VERSION "j1939-2025-03-v2.4-light"

NS_ :

BS_:

BU_:

BO_ 2566547198 ASI3: 8 Vector__XXX
 SG_ DslExhstFldTnk1EmptCnt : 0|32@1+ (1,0) [0|4211081215] "count" Vector__XXX
 SG_ DslExhstFldQltMlfntnCnt : 32|32@1+ (1,0) [0|4211081215] "count" Vector__XXX

BO_ 2633656318 FR1: 8 Vector__XXX
 SG_ EngineOilResistance : 0|32@1+ (1000,0) [0|4211081215000] "ohm" Vector__XXX
 SG_ HydraulicOilResistance : 32|32@1+ (1000,0) [0|4211081215000] "ohm" Vector__XXX

BO_ 2566547710 PC2IIR: 8 Vector__XXX
 SG_ PwCvt2HVtBsAtvIstTstCd : 0|2@1+ (1,0) [0|3] "" Vector__XXX
 SG_ PwCvt2HVtBsPssvIstTstCd : 2|2@1+ (1,0) [0|3] "" Vector__XXX
 SG_ PwCvt2HVtBsHSdRsstCtRqst : 4|2@1+ (1,0) [0|3] "" Vector__XXX
 SG_ PwCvt2HVtBsLwSdRsstCtRqst : 6|2@1+ (1,0) [0|3] "" Vector__XXX

BO_ 2566547966 PC1IIR: 8 Vector__XXX
 SG_ PwCvt1HVtBsAtvIstTstCd : 0|2@1+ (1,0) [0|3] "" Vector__XXX
 SG_ PwCvt1HVtBsPssvIstTstCd : 2|2@1+ (1,0) [0|3] "" Vector__XXX
 SG_ PwCvt1HVtBsHSdRsstCtRqst : 4|2@1+ (1,0) [0|3] "" Vector__XXX
 SG_ PwCvt1HVtBsLwSdRsstCtRqst : 6|2@1+ (1,0) [0|3] "" Vector__XXX

BO_ 2566548222 PC2IRP: 8 Vector__XXX
 SG_ PwrCnvrtr2LmtsRqstPwrCr : 0|8@1+ (1,0) [0|250] "count" Vector__XXX
 SG_ PwrCnvrtr2LmtsRqstPwrCntr : 8|4@1+ (1,0) [0|15] "" Vector__XXX
 SG_ PwrCnvrtr2LmtsRqstEltrlPwrMxmm : 12|12@1+ (0.0625,-125) [-125|125.9375] "%" Vector__XXX
 SG_ PwrCnvrtr2LmtsRqstEltrlPwrMnmm : 24|12@1+ (0.0625,-125) [-125|125.9375] "%" Vector__XXX
 SG_ PwCvt2LtsRqstDES1PwMx : 36|12@1+ (0.0625,-125) [-125|125.9375] "%" Vector__XXX
 SG_ PwCvt2LtsRqstDES1PwM : 48|12@1+ (0.0625,-125) [-125|125.9375] "%" Vector__XXX

BO_ 2566548478 PC2ILRM: 8 Vector__XXX
 SG_ PwrCnvrtr2LmtsRqstEltrlCr : 0|8@1+ (1,0) [0|250] "count" Vector__XXX
 SG_ PwrCnvrtr2LmtsRqstEltrlCntr : 8|4@1+ (1,0) [0|15] "" Vector__XXX
 SG_ PwrCnvrtr2LmtsRqstCrrntMxmm : 12|12@1+ (0.0625,-125) [-125|125.9375] "%" Vector__XXX
 SG_ PwrCnvrtr2LmtsRqstCrrntMnmm : 24|12@1+ (0.0625,-125) [-125|125.9375] "%" Vector__XXX
 SG_ PwrCnvrtr2LmtsRqstFrqnMxmm : 36|12@1+ (0.0625,-125) [-125|125.9375] "%" Vector__XXX
 SG_ PwrCnvrtr2LmtsRqstFrqnMnmm : 48|12@1+ (0.0625,-125) [-125|125.9375] "%" Vector__XXX

BO_ 2566548734 PC2ILRDC: 8 Vector__XXX
 SG_ PwrCnvrtr2LmtsRqstDEnrgSr1Cr : 0|8@1+ (1,0) [0|250] "count" Vector__XXX
 SG_ PwrCnvrtr2LmtsRqstDEnrgSr1Cntr : 8|4@1+ (1,0) [0|15] "" Vector__XXX
 SG_ PwCvt2LtsRqstDES1VtMx : 12|12@1+ (0.0625,-125) [-125|125.9375] "%" Vector__XXX
 SG_ PwCvt2LtsRqstDES1VtM : 24|12@1+ (0.0625,-125) [-125|125.9375] "%" Vector__XXX
 SG_ PwCvt2LtsRqstDES1CtMx : 36|12@1+ (0.0625,-125) [-125|125.9375] "%" Vector__XXX
 SG_ PwCvt2LtsRqstDES1CtM : 48|12@1+ (0.0625,-125) [-125|125.9375] "%" Vector__XXX

BO_ 2566548990 PC1ILRDC: 8 Vector__XXX
 SG_ PwrCnvrtr1LmtsRqstDEnrgSr1Cr : 0|8@1+ (1,0) [0|250] "count" Vector__XXX
 SG_ PwrCnvrtr1LmtsRqstDEnrgSr1Cntr : 8|4@1+ (1,0) [0|15] "" Vector__XXX
 SG_ PwCvt1LtsRqstDES1VtMx : 12|12@1+ (0.0625,-125) [-125|125.9375] "%" Vector__XXX
 SG_ PwCvt1LtsRqstDES1VtM : 24|12@1+ (0.0625,-125) [-125|125.9375] "%" Vector__XXX
 SG_ PwCvt1LtsRqstDES1CtMx : 36|12@1+ (0.0625,-125) [-125|125.9375] "%" Vector__XXX
 SG_ PwCvt1LtsRqstDES1CtM : 48|12@1+ (0.0625,-125) [-125|125.9375] "%" Vector__XXX

BO_ 2566549246 PC1ILRM: 8 Vector__XXX
 SG_ PwrCnvrtr1LmtsRqstEltrlCr : 0|8@1+ (1,0) [0|250] "count" Vector__XXX
 SG_ PwrCnvrtr1LmtsRqstEltrlCntr : 8|4@1+ (1,0) [0|15] "" Vector__XXX
 SG_ PwrCnvrtr1LmtsRqstCrrntMxmm : 12|12@1+ (0.0625,-125) [-125|125.9375] "%" Vector__XXX
 SG_ PwrCnvrtr1LmtsRqstCrrntMnmm : 24|12@1+ (0.0625,-125) [-125|125.9375] "%" Vector__XXX
 SG_ PwrCnvrtr1LmtsRqstFrqnMxmm : 36|12@1+ (0.0625,-125) [-125|125.9375] "%" Vector__XXX
 SG_ PwrCnvrtr1LmtsRqstFrqnMnmm : 48|12@1+ (0.0625,-125) [-125|125.9375] "%" Vector__XXX

BO_ 2566549502 PC1IRP: 8 Vector__XXX
 SG_ PwrCnvrtr1LmtsRqstPwrCr : 0|8@1+ (1,0) [0|250] "count" Vector__XXX
 SG_ PwrCnvrtr1LmtsRqstPwrCntr : 8|4@1+ (1,0) [0|15] "" Vector__XXX
 SG_ PwrCnvrtr1LmtsRqstEltrlPwrMxmm : 12|12@1+ (0.0625,-125) [-125|125.9375] "%" Vector__XXX
 SG_ PwrCnvrtr1LmtsRqstEltrlPwrMnmm : 24|12@1+ (0.0625,-125) [-125|125.9375] "%" Vector__XXX
 SG_ PwCvt1LtsRqstDES1PwMx : 36|12@1+ (0.0625,-125) [-125|125.9375] "%" Vector__XXX
 SG_ PwCvt1LtsRqstDES1PwM : 48|12@1+ (0.0625,-125) [-125|125.9375] "%" Vector__XXX

BO_ 2566549758 PC1LD: 16 Vector__XXX
 SG_ PwrCnvrtr1TtlEnrgCnsmd : 0|32@1+ (100,0) [0|421108121500] "Watt-hour" Vector__XXX
 SG_ PwrCnvrtr1TtlEnrgGnrtd : 32|32@1+ (100,0) [0|421108121500] "Watt-hour" Vector__XXX
 SG_ PwrCnvrtr1TtlChrgCnsmd : 64|32@1+ (100,0) [0|421108121500] "Ah" Vector__XXX
 SG_ PwrCnvrtr1TtlChrgGnrtd : 96|32@1+ (100,0) [0|421108121500] "Ah" Vector__XXX

BO_ 2566550014 PC2LD: 16 Vector__XXX
 SG_ PwrCnvrtr2TtlEnrgCnsmd : 0|32@1+ (100,0) [0|421108121500] "Watt-hour" Vector__XXX
 SG_ PwrCnvrtr2TtlEnrgGnrtd : 32|32@1+ (100,0) [0|421108121500] "Watt-hour" Vector__XXX
 SG_ PwrCnvrtr2TtlChrgCnsmd : 64|32@1+ (100,0) [0|421108121500] "Ah" Vector__XXX
 SG_ PwrCnvrtr2TtlChrgGnrtd : 96|32@1+ (100,0) [0|421108121500] "Ah" Vector__XXX

BO_ 2566550270 PC2IAPL: 8 Vector__XXX
 SG_ PwrCnvrtr2PwrLmtdDTUndfndRsn : 0|2@1+ (1,0) [0|3] "" Vector__XXX
 SG_ PwCvt2PwLtdDTDES1CtMx : 2|2@1+ (1,0) [0|3] "" Vector__XXX
 SG_ PwCvt2PwLtdDTDES1CtM : 4|2@1+ (1,0) [0|3] "" Vector__XXX
 SG_ PwCvt2PwLtdDTDES1VtMx : 6|2@1+ (1,0) [0|3] "" Vector__XXX
 SG_ PwCvt2PwLtdDTDES1VtM : 8|2@1+ (1,0) [0|3] "" Vector__XXX
 SG_ PwrCnvrtr2PwrLmtdDTEltrlPwrMxmm : 10|2@1+ (1,0) [0|3] "" Vector__XXX
 SG_ PwrCnvrtr2PwrLmtdDTEltrlPwrMnmm : 12|2@1+ (1,0) [0|3] "" Vector__XXX
 SG_ PwCvt2PwLtdDTDES1PwMx : 14|2@1+ (1,0) [0|3] "" Vector__XXX
 SG_ PwCvt2PwLtdDTDES1PwM : 16|2@1+ (1,0) [0|3] "" Vector__XXX
 SG_ PwrCnvrtr2PwrLmtdDTCrrntMxmm : 18|2@1+ (1,0) [0|3] "" Vector__XXX
 SG_ PwrCnvrtr2PwrLmtdDTCrrntMnmm : 20|2@1+ (1,0) [0|3] "" Vector__XXX
 SG_ PwrCnvrtr2PwrLmtdDTFrqnMxmm : 22|2@1+ (1,0) [0|3] "" Vector__XXX
 SG_ PwrCnvrtr2PwrLmtdDTFrqnMnmm : 24|2@1+ (1,0) [0|3] "" Vector__XXX
 SG_ PwrCnvrtr2PwrLmtdDTInvrtrTmprtr : 28|2@1+ (1,0) [0|3] "" Vector__XXX
 SG_ PwrCnvrtr2PwrLmtdDTTmprtr : 30|2@1+ (1,0) [0|3] "" Vector__XXX
 SG_ PwrCnvrtr2PwrLmtdDTFltCndtn : 32|2@1+ (1,0) [0|3] "" Vector__XXX
 SG_ PwCvt2PwLtdDTAtvCtRtLt : 34|2@1+ (1,0) [0|3] "" Vector__XXX
 SG_ PwCvt2CtLtdDTMCtsts : 38|2@1+ (1,0) [0|3] "" Vector__XXX

BO_ 2566550526 PC1IAPL: 8 Vector__XXX
 SG_ PwrCnvrtr1PwrLmtdDTUndfndRsn : 0|2@1+ (1,0) [0|3] "" Vector__XXX
 SG_ PwCvt1PwLtdDTDES1CtMx : 2|2@1+ (1,0) [0|3] "" Vector__XXX
 SG_ PwCvt1PwLtdDTDES1CtM : 4|2@1+ (1,0) [0|3] "" Vector__XXX
 SG_ PwCvt1PwLtdDTDES1VtMx : 6|2@1+ (1,0) [0|3] "" Vector__XXX
 SG_ PwCvt1PwLtdDTDES1VtM : 8|2@1+ (1,0) [0|3] "" Vector__XXX
 SG_ PwrCnvrtr1PwrLmtdDTEltrlPwrMxmm : 10|2@1+ (1,0) [0|3] "" Vector__XXX
 SG_ PwrCnvrtr1PwrLmtdDTEltrlPwrMnmm : 12|2@1+ (1,0) [0|3] "" Vector__XXX
 SG_ PwCvt1PwLtdDTDES1PwMx : 14|2@1+ (1,0) [0|3] "" Vector__XXX
 SG_ PwCvt1PwLtdDTDES1PwM : 16|2@1+ (1,0) [0|3] "" Vector__XXX
 SG_ PwrCnvrtr1PwrLmtdDTCrrntMxmm : 18|2@1+ (1,0) [0|3] "" Vector__XXX
 SG_ PwrCnvrtr1PwrLmtdDTCrrntMnmm : 20|2@1+ (1,0) [0|3] "" Vector__XXX
 SG_ PwrCnvrtr1PwrLmtdDTFrqnMxmm : 22|2@1+ (1,0) [0|3] "" Vector__XXX
 SG_ PwrCnvrtr1PwrLmtdDTFrqnMnmm : 24|2@1+ (1,0) [0|3] "" Vector__XXX
 SG_ PwrCnvrtr1PwrLmtdDTInvrtrTmprtr : 28|2@1+ (1,0) [0|3] "" Vector__XXX
 SG_ PwrCnvrtr1PwrLmtdDTTmprtr : 30|2@1+ (1,0) [0|3] "" Vector__XXX
 SG_ PwrCnvrtr1PwrLmtdDTFltCndtn : 32|2@1+ (1,0) [0|3] "" Vector__XXX
 SG_ PwCvt1PwLtdDTAtvCtRtLt : 34|2@1+ (1,0) [0|3] "" Vector__XXX
 SG_ PwCvt1CtLtdDTMCtsts : 38|2@1+ (1,0) [0|3] "" Vector__XXX

BO_ 2365224190 PC2IR1: 8 Vector__XXX
 SG_ PowerConverter2Reference1Crc : 0|8@1+ (1,0) [0|250] "count" Vector__XXX
 SG_ PwrCnvrtr2Rfrn1Cntr : 8|4@1+ (1,0) [0|15] "" Vector__XXX
 SG_ PwrCnvrtr2RfrnFrqn : 32|16@1+ (4,0) [0|257020] "rpm" Vector__XXX
 SG_ PowerConverter2ReferencePower : 48|16@1+ (0.0625,0) [0|4015.9375] "kW" Vector__XXX
 SG_ PowerConverter2ReferenceTorque : 16|16@1+ (0.5,0) [0|32127.5] "Nm" Vector__XXX

BO_ 2365224446 PC2IR2: 8 Vector__XXX
 SG_ PowerConverter2ReferenceCurrent : 32|16@1+ (0.125,0) [0|8031.875] "A" Vector__XXX
 SG_ PowerConverter2Reference2Crc : 0|8@1+ (1,0) [0|250] "count" Vector__XXX
 SG_ PwrCnvrtr2Rfrn2Cntr : 8|4@1+ (1,0) [0|15] "" Vector__XXX
 SG_ PowerConverter2ReferenceVoltage : 48|16@1+ (0.125,0) [0|8031.875] "V" Vector__XXX

BO_ 2566551294 PC2IT: 8 Vector__XXX
 SG_ PowerConverter2Temperature1 : 0|8@1+ (1,-40) [-40|210] "degC" Vector__XXX
 SG_ PowerConverter2Temperature2 : 8|8@1+ (1,-40) [-40|210] "degC" Vector__XXX
 SG_ PowerConverter2Temperature3 : 16|8@1+ (1,-40) [-40|210] "degC" Vector__XXX
 SG_ PowerConverter2Temperature4 : 24|8@1+ (1,-40) [-40|210] "degC" Vector__XXX

BO_ 2566551550 PC1IT: 8 Vector__XXX
 SG_ PowerConverter1Temperature1 : 0|8@1+ (1,-40) [-40|210] "degC" Vector__XXX
 SG_ PowerConverter1Temperature2 : 8|8@1+ (1,-40) [-40|210] "degC" Vector__XXX
 SG_ PowerConverter1Temperature3 : 16|8@1+ (1,-40) [-40|210] "degC" Vector__XXX
 SG_ PowerConverter1Temperature4 : 24|8@1+ (1,-40) [-40|210] "degC" Vector__XXX

BO_ 2365225214 PC1IR2: 8 Vector__XXX
 SG_ PowerConverter1Reference2Crc : 0|8@1+ (1,0) [0|250] "count" Vector__XXX
 SG_ PwrCnvrtr1Rfrn2Cntr : 8|4@1+ (1,0) [0|15] "" Vector__XXX
 SG_ PowerConverter1ReferenceCurrent : 32|16@1+ (0.125,0) [0|8031.875] "A" Vector__XXX
 SG_ PowerConverter1ReferenceVoltage : 48|16@1+ (0.125,0) [0|8031.875] "V" Vector__XXX

BO_ 2365225470 PC1IR1: 8 Vector__XXX
 SG_ PowerConverter1Reference1Crc : 0|8@1+ (1,0) [0|250] "count" Vector__XXX
 SG_ PwrCnvrtr1Rfrn1Cntr : 8|4@1+ (1,0) [0|15] "" Vector__XXX
 SG_ PwrCnvrtr1RfrnFrqn : 32|16@1+ (4,0) [0|257020] "rpm" Vector__XXX
 SG_ PowerConverter1ReferencePower : 48|16@1+ (0.0625,0) [0|4015.9375] "kW" Vector__XXX
 SG_ PowerConverter1ReferenceTorque : 16|16@1+ (0.5,0) [0|32127.5] "Nm" Vector__XXX

BO_ 2365225726 PC1PC: 8 Vector__XXX
 SG_ PwrCnvrtr1PwrCnvrtrPhsUCrrnt : 0|16@1+ (0.125,0) [0|8031.875] "A" Vector__XXX
 SG_ PwrCnvrtr1PwrCnvrtrPhsVCrrnt : 16|16@1+ (0.125,0) [0|8031.875] "A" Vector__XXX
 SG_ PwrCnvrtr1PwrCnvrtrPhsWCrrnt : 32|16@1+ (0.125,0) [0|8031.875] "A" Vector__XXX

BO_ 2365225982 S21PC: 8 Vector__XXX
 SG_ PwrCnvrtr2PwrCnvrtrPhsUCrrnt : 0|16@1+ (0.125,0) [0|8031.875] "A" Vector__XXX
 SG_ PwrCnvrtr2PwrCnvrtrPhsVCrrnt : 16|16@1+ (0.125,0) [0|8031.875] "A" Vector__XXX
 SG_ PwrCnvrtr2PwrCnvrtrPhsWCrrnt : 32|16@1+ (0.125,0) [0|8031.875] "A" Vector__XXX

BO_ 2365226238 PC1PV: 8 Vector__XXX
 SG_ PwrCnvrtr1PwrCnvrtrPhsUVltg : 0|16@1+ (0.125,0) [0|8031.875] "V" Vector__XXX
 SG_ PwrCnvrtr1PwrCnvrtrPhsVVltg : 16|16@1+ (0.125,0) [0|8031.875] "V" Vector__XXX
 SG_ PwrCnvrtr1PwrCnvrtrPhsWVltg : 32|16@1+ (0.125,0) [0|8031.875] "V" Vector__XXX

BO_ 2365226494 PC2PV: 8 Vector__XXX
 SG_ PwrCnvrtr2PwrCnvrtrPhsUVltg : 0|16@1+ (0.125,0) [0|8031.875] "V" Vector__XXX
 SG_ PwrCnvrtr2PwrCnvrtrPhsVVltg : 16|16@1+ (0.125,0) [0|8031.875] "V" Vector__XXX
 SG_ PwrCnvrtr2PwrCnvrtrPhsWVltg : 32|16@1+ (0.125,0) [0|8031.875] "V" Vector__XXX

BO_ 2566553342 SIPST: 8 Vector__XXX
 SG_ PwCvt1PwCvtPsUPwMdSwtTpt : 0|8@1+ (1,-40) [-40|210] "degC" Vector__XXX
 SG_ PwCvt1PwCvtPsVPwMdSwtTpt : 8|8@1+ (1,-40) [-40|210] "degC" Vector__XXX
 SG_ PwCvt1PwCvtPsWPwMdSwtTpt : 16|8@1+ (1,-40) [-40|210] "degC" Vector__XXX
 SG_ PwCvt2PwCvtPsUPwMdSwtTpt : 24|8@1+ (1,-40) [-40|210] "degC" Vector__XXX
 SG_ PwCvt2PwCvtPsVPwMdSwtTpt : 32|8@1+ (1,-40) [-40|210] "degC" Vector__XXX
 SG_ PwCvt2PwCvtPsWPwMdSwtTpt : 40|8@1+ (1,-40) [-40|210] "degC" Vector__XXX

BO_ 2365227006 PC1PSV: 8 Vector__XXX
 SG_ PwCvt1PwCvtPsUPwMdSwtPwSppVt : 0|16@1+ (0.125,0) [0|8031.875] "V" Vector__XXX
 SG_ PwCvt1PwCvtPsVPwMdSwtPwSppVt : 16|16@1+ (0.125,0) [0|8031.875] "V" Vector__XXX
 SG_ PwCvt1PwCvtPsWPwMdSwtPwSppVt : 32|16@1+ (0.125,0) [0|8031.875] "V" Vector__XXX

BO_ 2365227262 PC2PSV: 8 Vector__XXX
 SG_ PwCvt2PwCvtPsUPwMdSwtPwSppVt : 0|16@1+ (0.125,0) [0|8031.875] "V" Vector__XXX
 SG_ PwCvt2PwCvtPsVPwMdSwtPwSppVt : 16|16@1+ (0.125,0) [0|8031.875] "V" Vector__XXX
 SG_ PwCvt2PwCvtPsWPwMdSwtPwSppVt : 32|16@1+ (0.125,0) [0|8031.875] "V" Vector__XXX

BO_ 2365227518 SIT1: 8 Vector__XXX
 SG_ PwrCnvrtr1PwrCnvrtrACrrntOtpt : 0|16@1+ (0.125,0) [0|8031.875] "A" Vector__XXX
 SG_ PwrCnvrtr2PwrCnvrtrACrrntOtpt : 16|16@1+ (0.125,0) [0|8031.875] "A" Vector__XXX
 SG_ PwCvt1PwCvtPwMdSwtTpt : 32|8@1+ (1,-40) [-40|210] "degC" Vector__XXX
 SG_ PwCvt2PwCvtPwMdSwtTpt : 40|8@1+ (1,-40) [-40|210] "degC" Vector__XXX

BO_ 2566554366 TFMRT: 8 Vector__XXX
 SG_ Transformer1PhaseUTemperature : 0|8@1+ (1,-40) [-40|210] "degC" Vector__XXX
 SG_ Transformer1PhaseVTemperature : 8|8@1+ (1,-40) [-40|210] "degC" Vector__XXX
 SG_ Transformer1PhaseWTemperature : 16|8@1+ (1,-40) [-40|210] "degC" Vector__XXX
 SG_ Transformer2PhaseUTemperature : 24|8@1+ (1,-40) [-40|210] "degC" Vector__XXX
 SG_ Transformer2PhaseVTemperature : 32|8@1+ (1,-40) [-40|210] "degC" Vector__XXX
 SG_ Transformer2PhaseWTemperature : 40|8@1+ (1,-40) [-40|210] "degC" Vector__XXX

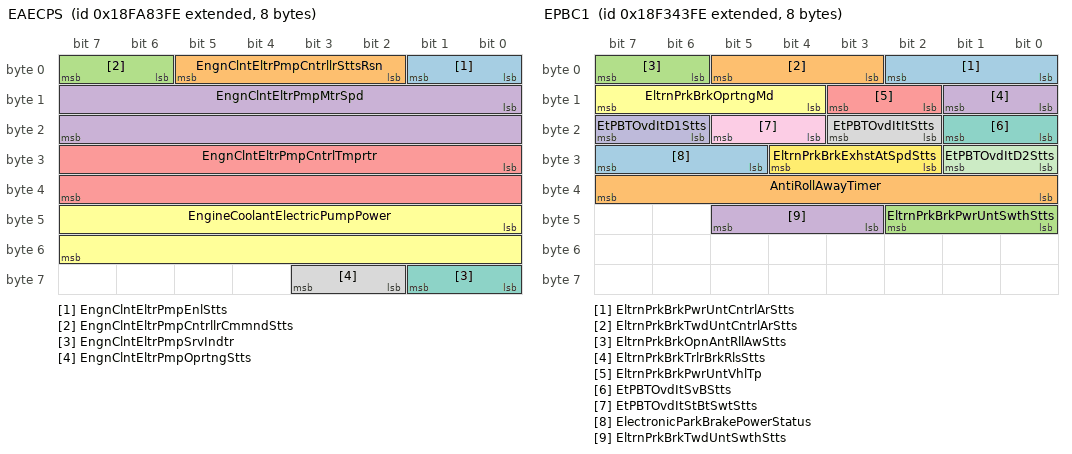
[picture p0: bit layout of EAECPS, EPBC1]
BO_ 2566554622 EAECPS: 8 Vector__XXX
 SG_ EngnClntEltrPmpEnlStts : 0|2@1+ (1,0) [0|3] "" Vector__XXX
 SG_ EngnClntEltrPmpCntrllrSttsRsn : 2|4@1+ (1,0) [0|15] "" Vector__XXX
 SG_ EngnClntEltrPmpCntrllrCmmndStts : 6|2@1+ (1,0) [0|3] "" Vector__XXX
 SG_ EngnClntEltrPmpMtrSpd : 8|16@1+ (0.5,0) [0|32127.5] "rpm" Vector__XXX
 SG_ EngnClntEltrPmpCntrlTmprtr : 24|16@1+ (0.03125,-273) [-273|1734.96875] "degC" Vector__XXX
 SG_ EngineCoolantElectricPumpPower : 40|16@1+ (0.5,0) [0|32127.5] "W" Vector__XXX
 SG_ EngnClntEltrPmpSrvIndtr : 56|2@1+ (1,0) [0|3] "" Vector__XXX
 SG_ EngnClntEltrPmpOprtngStts : 58|2@1+ (1,0) [0|3] "" Vector__XXX

BO_ 2633663742 HVESP11HIST: 19 Vector__XXX
 SG_ Hvesp11StateOfHealth : 0|8@1+ (0.4,0) [0|100] "%" Vector__XXX
 SG_ Hvsp11CnttrOpnUndrLdCnt : 8|16@1+ (1,0) [0|64255] "count" Vector__XXX
 SG_ Hvesp11TotalEnergyThroughput : 24|32@1+ (100,0) [0|421108121500] "Watt-hour" Vector__XXX
 SG_ Hvesp11TotalAccumulatedCharge : 56|32@1+ (100,0) [0|421108121500] "Ah" Vector__XXX
 SG_ Hvesp11TotalLifetimeEnergyInput : 88|32@1+ (1,0) [0|4211081215] "kWh" Vector__XXX
 SG_ Hvsp11TtlLftmEnrgOtpt : 120|32@1+ (1,0) [0|4211081215] "kWh" Vector__XXX

BO_ 2566555134 HVESP11CFG: 19 Vector__XXX
 SG_ Hvesp11NominalVoltage : 0|16@1+ (0.05,0) [0|3212.75] "V" Vector__XXX
 SG_ Hvsp11RmmnddMnmmOprtngVltg : 16|16@1+ (0.05,0) [0|3212.75] "V" Vector__XXX
 SG_ Hvsp11RmmnddMxmmOprtngVltg : 32|16@1+ (0.05,0) [0|3212.75] "V" Vector__XXX
 SG_ Hvsp11RmmnddMnmmSttOfChrg : 48|16@1+ (0.0015625,0) [0|100.3984375] "%" Vector__XXX
 SG_ Hvsp11RmmnddMxmmSttOfChrg : 64|16@1+ (0.0015625,0) [0|100.3984375] "%" Vector__XXX
 SG_ Hvsp11RmmnddMxmmOprtngTmprtr : 80|16@1+ (0.03125,-273) [-273|1734.96875] "degC" Vector__XXX
 SG_ Hvsp11RmmnddMnmmOprtngTmprtr : 96|16@1+ (0.03125,-273) [-273|1734.96875] "degC" Vector__XXX
 SG_ Hvesp11CellMaximumVoltageLimit : 112|8@1+ (0.02044,0) [0|5.11] "V" Vector__XXX
 SG_ Hvesp11CellMinimumVoltageLimit : 120|8@1+ (0.02044,0) [0|5.11] "V" Vector__XXX
 SG_ Hvesp11NominalRatedCapacity : 128|24@1+ (0.001,0) [0|16449.535] "kWh" Vector__XXX

BO_ 2633664254 HVESP12HIST: 19 Vector__XXX
 SG_ Hvesp12StateOfHealth : 0|8@1+ (0.4,0) [0|100] "%" Vector__XXX
 SG_ Hvsp12CnttrOpnUndrLdCnt : 8|16@1+ (1,0) [0|64255] "count" Vector__XXX
 SG_ Hvesp12TotalEnergyThroughput : 24|32@1+ (100,0) [0|421108121500] "Watt-hour" Vector__XXX
 SG_ Hvesp12TotalAccumulatedCharge : 56|32@1+ (100,0) [0|421108121500] "Ah" Vector__XXX
 SG_ Hvesp12TotalLifetimeEnergyInput : 88|32@1+ (1,0) [0|4211081215] "kWh" Vector__XXX
 SG_ Hvsp12TtlLftmEnrgOtpt : 120|32@1+ (1,0) [0|4211081215] "kWh" Vector__XXX

BO_ 2566555646 HVESP12CFG: 19 Vector__XXX
 SG_ Hvesp12NominalVoltage : 0|16@1+ (0.05,0) [0|3212.75] "V" Vector__XXX
 SG_ Hvsp12RmmnddMnmmOprtngVltg : 16|16@1+ (0.05,0) [0|3212.75] "V" Vector__XXX
 SG_ Hvsp12RmmnddMxmmOprtngVltg : 32|16@1+ (0.05,0) [0|3212.75] "V" Vector__XXX
 SG_ Hvsp12RmmnddMnmmSttOfChrg : 48|16@1+ (0.0015625,0) [0|100.3984375] "%" Vector__XXX
 SG_ Hvsp12RmmnddMxmmSttOfChrg : 64|16@1+ (0.0015625,0) [0|100.3984375] "%" Vector__XXX
 SG_ Hvsp12RmmnddMxmmOprtngTmprtr : 80|16@1+ (0.03125,-273) [-273|1734.96875] "degC" Vector__XXX
 SG_ Hvsp12RmmnddMnmmOprtngTmprtr : 96|16@1+ (0.03125,-273) [-273|1734.96875] "degC" Vector__XXX
 SG_ Hvesp12CellMaximumVoltageLimit : 112|8@1+ (0.02044,0) [0|5.11] "V" Vector__XXX
 SG_ Hvesp12CellMinimumVoltageLimit : 120|8@1+ (0.02044,0) [0|5.11] "V" Vector__XXX
 SG_ Hvesp12NominalRatedCapacity : 128|24@1+ (0.001,0) [0|16449.535] "kWh" Vector__XXX

BO_ 2633664766 HVESP13HIST: 19 Vector__XXX
 SG_ Hvesp13StateOfHealth : 0|8@1+ (0.4,0) [0|100] "%" Vector__XXX
 SG_ Hvsp13CnttrOpnUndrLdCnt : 8|16@1+ (1,0) [0|64255] "count" Vector__XXX
 SG_ Hvesp13TotalEnergyThroughput : 24|32@1+ (100,0) [0|421108121500] "Watt-hour" Vector__XXX
 SG_ Hvesp13TotalAccumulatedCharge : 56|32@1+ (100,0) [0|421108121500] "Ah" Vector__XXX
 SG_ Hvesp13TotalLifetimeEnergyInput : 88|32@1+ (1,0) [0|4211081215] "kWh" Vector__XXX
 SG_ Hvsp13TtlLftmEnrgOtpt : 120|32@1+ (1,0) [0|4211081215] "kWh" Vector__XXX

BO_ 2566556158 HVESP13CFG: 19 Vector__XXX
 SG_ Hvesp13NominalVoltage : 0|16@1+ (0.05,0) [0|3212.75] "V" Vector__XXX
 SG_ Hvsp13RmmnddMnmmOprtngVltg : 16|16@1+ (0.05,0) [0|3212.75] "V" Vector__XXX
 SG_ Hvsp13RmmnddMxmmOprtngVltg : 32|16@1+ (0.05,0) [0|3212.75] "V" Vector__XXX
 SG_ Hvsp13RmmnddMnmmSttOfChrg : 48|16@1+ (0.0015625,0) [0|100.3984375] "%" Vector__XXX
 SG_ Hvsp13RmmnddMxmmSttOfChrg : 64|16@1+ (0.0015625,0) [0|100.3984375] "%" Vector__XXX
 SG_ Hvsp13RmmnddMxmmOprtngTmprtr : 80|16@1+ (0.03125,-273) [-273|1734.96875] "degC" Vector__XXX
 SG_ Hvsp13RmmnddMnmmOprtngTmprtr : 96|16@1+ (0.03125,-273) [-273|1734.96875] "degC" Vector__XXX
 SG_ Hvesp13CellMaximumVoltageLimit : 112|8@1+ (0.02044,0) [0|5.11] "V" Vector__XXX
 SG_ Hvesp13CellMinimumVoltageLimit : 120|8@1+ (0.02044,0) [0|5.11] "V" Vector__XXX
 SG_ Hvesp13NominalRatedCapacity : 128|24@1+ (0.001,0) [0|16449.535] "kWh" Vector__XXX

BO_ 2633665278 HVESP14HIST: 19 Vector__XXX
 SG_ Hvesp14StateOfHealth : 0|8@1+ (0.4,0) [0|100] "%" Vector__XXX
 SG_ Hvsp14CnttrOpnUndrLdCnt : 8|16@1+ (1,0) [0|64255] "count" Vector__XXX
 SG_ Hvesp14TotalEnergyThroughput : 24|32@1+ (100,0) [0|421108121500] "Watt-hour" Vector__XXX
 SG_ Hvesp14TotalAccumulatedCharge : 56|32@1+ (100,0) [0|421108121500] "Ah" Vector__XXX
 SG_ Hvesp14TotalLifetimeEnergyInput : 88|32@1+ (1,0) [0|4211081215] "kWh" Vector__XXX
 SG_ Hvsp14TtlLftmEnrgOtpt : 120|32@1+ (1,0) [0|4211081215] "kWh" Vector__XXX

BO_ 2566556670 HVESP14CFG: 19 Vector__XXX
 SG_ Hvesp14NominalVoltage : 0|16@1+ (0.05,0) [0|3212.75] "V" Vector__XXX
 SG_ Hvsp14RmmnddMnmmOprtngVltg : 16|16@1+ (0.05,0) [0|3212.75] "V" Vector__XXX
 SG_ Hvsp14RmmnddMxmmOprtngVltg : 32|16@1+ (0.05,0) [0|3212.75] "V" Vector__XXX
 SG_ Hvsp14RmmnddMnmmSttOfChrg : 48|16@1+ (0.0015625,0) [0|100.3984375] "%" Vector__XXX
 SG_ Hvsp14RmmnddMxmmSttOfChrg : 64|16@1+ (0.0015625,0) [0|100.3984375] "%" Vector__XXX
 SG_ Hvsp14RmmnddMxmmOprtngTmprtr : 80|16@1+ (0.03125,-273) [-273|1734.96875] "degC" Vector__XXX
 SG_ Hvsp14RmmnddMnmmOprtngTmprtr : 96|16@1+ (0.03125,-273) [-273|1734.96875] "degC" Vector__XXX
 SG_ Hvesp14CellMaximumVoltageLimit : 112|8@1+ (0.02044,0) [0|5.11] "V" Vector__XXX
 SG_ Hvesp14CellMinimumVoltageLimit : 120|8@1+ (0.02044,0) [0|5.11] "V" Vector__XXX
 SG_ Hvesp14NominalRatedCapacity : 128|24@1+ (0.001,0) [0|16449.535] "kWh" Vector__XXX

BO_ 2633665790 HVESP15HIST: 19 Vector__XXX
 SG_ Hvesp15StateOfHealth : 0|8@1+ (0.4,0) [0|100] "%" Vector__XXX
 SG_ Hvsp15CnttrOpnUndrLdCnt : 8|16@1+ (1,0) [0|64255] "count" Vector__XXX
 SG_ Hvesp15TotalEnergyThroughput : 24|32@1+ (100,0) [0|421108121500] "Watt-hour" Vector__XXX
 SG_ Hvesp15TotalAccumulatedCharge : 56|32@1+ (100,0) [0|421108121500] "Ah" Vector__XXX
 SG_ Hvesp15TotalLifetimeEnergyInput : 88|32@1+ (1,0) [0|4211081215] "kWh" Vector__XXX
 SG_ Hvsp15TtlLftmEnrgOtpt : 120|32@1+ (1,0) [0|4211081215] "kWh" Vector__XXX

BO_ 2566557182 HVESP15CFG: 19 Vector__XXX
 SG_ Hvesp15NominalVoltage : 0|16@1+ (0.05,0) [0|3212.75] "V" Vector__XXX
 SG_ Hvsp15RmmnddMnmmOprtngVltg : 16|16@1+ (0.05,0) [0|3212.75] "V" Vector__XXX
 SG_ Hvsp15RmmnddMxmmOprtngVltg : 32|16@1+ (0.05,0) [0|3212.75] "V" Vector__XXX
 SG_ Hvsp15RmmnddMnmmSttOfChrg : 48|16@1+ (0.0015625,0) [0|100.3984375] "%" Vector__XXX
 SG_ Hvsp15RmmnddMxmmSttOfChrg : 64|16@1+ (0.0015625,0) [0|100.3984375] "%" Vector__XXX
 SG_ Hvsp15RmmnddMxmmOprtngTmprtr : 80|16@1+ (0.03125,-273) [-273|1734.96875] "degC" Vector__XXX
 SG_ Hvsp15RmmnddMnmmOprtngTmprtr : 96|16@1+ (0.03125,-273) [-273|1734.96875] "degC" Vector__XXX
 SG_ Hvesp15CellMaximumVoltageLimit : 112|8@1+ (0.02044,0) [0|5.11] "V" Vector__XXX
 SG_ Hvesp15CellMinimumVoltageLimit : 120|8@1+ (0.02044,0) [0|5.11] "V" Vector__XXX
 SG_ Hvesp15NominalRatedCapacity : 128|24@1+ (0.001,0) [0|16449.535] "kWh" Vector__XXX

BO_ 2633666302 HVESP16HIST: 19 Vector__XXX
 SG_ Hvesp16StateOfHealth : 0|8@1+ (0.4,0) [0|100] "%" Vector__XXX
 SG_ Hvsp16CnttrOpnUndrLdCnt : 8|16@1+ (1,0) [0|64255] "count" Vector__XXX
 SG_ Hvesp16TotalEnergyThroughput : 24|32@1+ (100,0) [0|421108121500] "Watt-hour" Vector__XXX
 SG_ Hvesp16TotalAccumulatedCharge : 56|32@1+ (100,0) [0|421108121500] "Ah" Vector__XXX
 SG_ Hvesp16TotalLifetimeEnergyInput : 88|32@1+ (1,0) [0|4211081215] "kWh" Vector__XXX
 SG_ Hvsp16TtlLftmEnrgOtpt : 120|32@1+ (1,0) [0|4211081215] "kWh" Vector__XXX

BO_ 2566557694 HVESP16CFG: 19 Vector__XXX
 SG_ Hvesp16NominalVoltage : 0|16@1+ (0.05,0) [0|3212.75] "V" Vector__XXX
 SG_ Hvsp16RmmnddMnmmOprtngVltg : 16|16@1+ (0.05,0) [0|3212.75] "V" Vector__XXX
 SG_ Hvsp16RmmnddMxmmOprtngVltg : 32|16@1+ (0.05,0) [0|3212.75] "V" Vector__XXX
 SG_ Hvsp16RmmnddMnmmSttOfChrg : 48|16@1+ (0.0015625,0) [0|100.3984375] "%" Vector__XXX
 SG_ Hvsp16RmmnddMxmmSttOfChrg : 64|16@1+ (0.0015625,0) [0|100.3984375] "%" Vector__XXX
 SG_ Hvsp16RmmnddMxmmOprtngTmprtr : 80|16@1+ (0.03125,-273) [-273|1734.96875] "degC" Vector__XXX
 SG_ Hvsp16RmmnddMnmmOprtngTmprtr : 96|16@1+ (0.03125,-273) [-273|1734.96875] "degC" Vector__XXX
 SG_ Hvesp16CellMaximumVoltageLimit : 112|8@1+ (0.02044,0) [0|5.11] "V" Vector__XXX
 SG_ Hvesp16CellMinimumVoltageLimit : 120|8@1+ (0.02044,0) [0|5.11] "V" Vector__XXX
 SG_ Hvesp16NominalRatedCapacity : 128|24@1+ (0.001,0) [0|16449.535] "kWh" Vector__XXX

BO_ 2633666814 HVESP17HIST: 19 Vector__XXX
 SG_ Hvesp17StateOfHealth : 0|8@1+ (0.4,0) [0|100] "%" Vector__XXX
 SG_ Hvsp17CnttrOpnUndrLdCnt : 8|16@1+ (1,0) [0|64255] "count" Vector__XXX
 SG_ Hvesp17TotalEnergyThroughput : 24|32@1+ (100,0) [0|421108121500] "Watt-hour" Vector__XXX
 SG_ Hvesp17TotalAccumulatedCharge : 56|32@1+ (100,0) [0|421108121500] "Ah" Vector__XXX
 SG_ Hvesp17TotalLifetimeEnergyInput : 88|32@1+ (1,0) [0|4211081215] "kWh" Vector__XXX
 SG_ Hvsp17TtlLftmEnrgOtpt : 120|32@1+ (1,0) [0|4211081215] "kWh" Vector__XXX

BO_ 2566558206 HVESP17CFG: 19 Vector__XXX
 SG_ Hvesp17NominalVoltage : 0|16@1+ (0.05,0) [0|3212.75] "V" Vector__XXX
 SG_ Hvsp17RmmnddMnmmOprtngVltg : 16|16@1+ (0.05,0) [0|3212.75] "V" Vector__XXX
 SG_ Hvsp17RmmnddMxmmOprtngVltg : 32|16@1+ (0.05,0) [0|3212.75] "V" Vector__XXX
 SG_ Hvsp17RmmnddMnmmSttOfChrg : 48|16@1+ (0.0015625,0) [0|100.3984375] "%" Vector__XXX
 SG_ Hvsp17RmmnddMxmmSttOfChrg : 64|16@1+ (0.0015625,0) [0|100.3984375] "%" Vector__XXX
 SG_ Hvsp17RmmnddMxmmOprtngTmprtr : 80|16@1+ (0.03125,-273) [-273|1734.96875] "degC" Vector__XXX
 SG_ Hvsp17RmmnddMnmmOprtngTmprtr : 96|16@1+ (0.03125,-273) [-273|1734.96875] "degC" Vector__XXX
 SG_ Hvesp17CellMaximumVoltageLimit : 112|8@1+ (0.02044,0) [0|5.11] "V" Vector__XXX
 SG_ Hvesp17CellMinimumVoltageLimit : 120|8@1+ (0.02044,0) [0|5.11] "V" Vector__XXX
 SG_ Hvesp17NominalRatedCapacity : 128|24@1+ (0.001,0) [0|16449.535] "kWh" Vector__XXX

BO_ 2633667326 HVESP18HIST: 19 Vector__XXX
 SG_ Hvesp18StateOfHealth : 0|8@1+ (0.4,0) [0|100] "%" Vector__XXX
 SG_ Hvsp18CnttrOpnUndrLdCnt : 8|16@1+ (1,0) [0|64255] "count" Vector__XXX
 SG_ Hvesp18TotalEnergyThroughput : 24|32@1+ (100,0) [0|421108121500] "Watt-hour" Vector__XXX
 SG_ Hvesp18TotalAccumulatedCharge : 56|32@1+ (100,0) [0|421108121500] "Ah" Vector__XXX
 SG_ Hvesp18TotalLifetimeEnergyInput : 88|32@1+ (1,0) [0|4211081215] "kWh" Vector__XXX
 SG_ Hvsp18TtlLftmEnrgOtpt : 120|32@1+ (1,0) [0|4211081215] "kWh" Vector__XXX

BO_ 2566558718 HVESP18CFG: 19 Vector__XXX
 SG_ Hvesp18NominalVoltage : 0|16@1+ (0.05,0) [0|3212.75] "V" Vector__XXX
 SG_ Hvsp18RmmnddMnmmOprtngVltg : 16|16@1+ (0.05,0) [0|3212.75] "V" Vector__XXX
 SG_ Hvsp18RmmnddMxmmOprtngVltg : 32|16@1+ (0.05,0) [0|3212.75] "V" Vector__XXX
 SG_ Hvsp18RmmnddMnmmSttOfChrg : 48|16@1+ (0.0015625,0) [0|100.3984375] "%" Vector__XXX
 SG_ Hvsp18RmmnddMxmmSttOfChrg : 64|16@1+ (0.0015625,0) [0|100.3984375] "%" Vector__XXX
 SG_ Hvsp18RmmnddMxmmOprtngTmprtr : 80|16@1+ (0.03125,-273) [-273|1734.96875] "degC" Vector__XXX
 SG_ Hvsp18RmmnddMnmmOprtngTmprtr : 96|16@1+ (0.03125,-273) [-273|1734.96875] "degC" Vector__XXX
 SG_ Hvesp18CellMaximumVoltageLimit : 112|8@1+ (0.02044,0) [0|5.11] "V" Vector__XXX
 SG_ Hvesp18CellMinimumVoltageLimit : 120|8@1+ (0.02044,0) [0|5.11] "V" Vector__XXX
 SG_ Hvesp18NominalRatedCapacity : 128|24@1+ (0.001,0) [0|16449.535] "kWh" Vector__XXX

BO_ 2633667838 HVESP19HIST: 19 Vector__XXX
 SG_ Hvesp19StateOfHealth : 0|8@1+ (0.4,0) [0|100] "%" Vector__XXX
 SG_ Hvsp19CnttrOpnUndrLdCnt : 8|16@1+ (1,0) [0|64255] "count" Vector__XXX
 SG_ Hvesp19TotalEnergyThroughput : 24|32@1+ (100,0) [0|421108121500] "Watt-hour" Vector__XXX
 SG_ Hvesp19TotalAccumulatedCharge : 56|32@1+ (100,0) [0|421108121500] "Ah" Vector__XXX
 SG_ Hvesp19TotalLifetimeEnergyInput : 88|32@1+ (1,0) [0|4211081215] "kWh" Vector__XXX
 SG_ Hvsp19TtlLftmEnrgOtpt : 120|32@1+ (1,0) [0|4211081215] "kWh" Vector__XXX

BO_ 2566559230 HVESP19CFG: 19 Vector__XXX
 SG_ Hvesp19NominalVoltage : 0|16@1+ (0.05,0) [0|3212.75] "V" Vector__XXX
 SG_ Hvsp19RmmnddMnmmOprtngVltg : 16|16@1+ (0.05,0) [0|3212.75] "V" Vector__XXX
 SG_ Hvsp19RmmnddMxmmOprtngVltg : 32|16@1+ (0.05,0) [0|3212.75] "V" Vector__XXX
 SG_ Hvsp19RmmnddMnmmSttOfChrg : 48|16@1+ (0.0015625,0) [0|100.3984375] "%" Vector__XXX
 SG_ Hvsp19RmmnddMxmmSttOfChrg : 64|16@1+ (0.0015625,0) [0|100.3984375] "%" Vector__XXX
 SG_ Hvsp19RmmnddMxmmOprtngTmprtr : 80|16@1+ (0.03125,-273) [-273|1734.96875] "degC" Vector__XXX
 SG_ Hvsp19RmmnddMnmmOprtngTmprtr : 96|16@1+ (0.03125,-273) [-273|1734.96875] "degC" Vector__XXX
 SG_ Hvesp19CellMaximumVoltageLimit : 112|8@1+ (0.02044,0) [0|5.11] "V" Vector__XXX
 SG_ Hvesp19CellMinimumVoltageLimit : 120|8@1+ (0.02044,0) [0|5.11] "V" Vector__XXX
 SG_ Hvesp19NominalRatedCapacity : 128|24@1+ (0.001,0) [0|16449.535] "kWh" Vector__XXX

BO_ 2633668350 HVESP20HIST: 19 Vector__XXX
 SG_ Hvesp20StateOfHealth : 0|8@1+ (0.4,0) [0|100] "%" Vector__XXX
 SG_ Hvsp20CnttrOpnUndrLdCnt : 8|16@1+ (1,0) [0|64255] "count" Vector__XXX
 SG_ Hvesp20TotalEnergyThroughput : 24|32@1+ (100,0) [0|421108121500] "Watt-hour" Vector__XXX
 SG_ Hvesp20TotalAccumulatedCharge : 56|32@1+ (100,0) [0|421108121500] "Ah" Vector__XXX
 SG_ Hvesp20TotalLifetimeEnergyInput : 88|32@1+ (1,0) [0|4211081215] "kWh" Vector__XXX
 SG_ Hvsp20TtlLftmEnrgOtpt : 120|32@1+ (1,0) [0|4211081215] "kWh" Vector__XXX

BO_ 2566559742 HVESP20CFG: 19 Vector__XXX
 SG_ Hvesp20NominalVoltage : 0|16@1+ (0.05,0) [0|3212.75] "V" Vector__XXX
 SG_ Hvsp20RmmnddMnmmOprtngVltg : 16|16@1+ (0.05,0) [0|3212.75] "V" Vector__XXX
 SG_ Hvsp20RmmnddMxmmOprtngVltg : 32|16@1+ (0.05,0) [0|3212.75] "V" Vector__XXX
 SG_ Hvsp20RmmnddMnmmSttOfChrg : 48|16@1+ (0.0015625,0) [0|100.3984375] "%" Vector__XXX
 SG_ Hvsp20RmmnddMxmmSttOfChrg : 64|16@1+ (0.0015625,0) [0|100.3984375] "%" Vector__XXX
 SG_ Hvsp20RmmnddMxmmOprtngTmprtr : 80|16@1+ (0.03125,-273) [-273|1734.96875] "degC" Vector__XXX
 SG_ Hvsp20RmmnddMnmmOprtngTmprtr : 96|16@1+ (0.03125,-273) [-273|1734.96875] "degC" Vector__XXX
 SG_ Hvesp20CellMaximumVoltageLimit : 112|8@1+ (0.02044,0) [0|5.11] "V" Vector__XXX
 SG_ Hvesp20CellMinimumVoltageLimit : 120|8@1+ (0.02044,0) [0|5.11] "V" Vector__XXX
 SG_ Hvesp20NominalRatedCapacity : 128|24@1+ (0.001,0) [0|16449.535] "kWh" Vector__XXX

BO_ 2633668862 HVESP21HIST: 19 Vector__XXX
 SG_ Hvesp21StateOfHealth : 0|8@1+ (0.4,0) [0|100] "%" Vector__XXX
 SG_ Hvsp21CnttrOpnUndrLdCnt : 8|16@1+ (1,0) [0|64255] "count" Vector__XXX
 SG_ Hvesp21TotalEnergyThroughput : 24|32@1+ (100,0) [0|421108121500] "Watt-hour" Vector__XXX
 SG_ Hvesp21TotalAccumulatedCharge : 56|32@1+ (100,0) [0|421108121500] "Ah" Vector__XXX
 SG_ Hvesp21TotalLifetimeEnergyInput : 88|32@1+ (1,0) [0|4211081215] "kWh" Vector__XXX
 SG_ Hvsp21TtlLftmEnrgOtpt : 120|32@1+ (1,0) [0|4211081215] "kWh" Vector__XXX

BO_ 2566560254 HVESP21CFG: 19 Vector__XXX
 SG_ Hvesp21NominalVoltage : 0|16@1+ (0.05,0) [0|3212.75] "V" Vector__XXX
 SG_ Hvsp21RmmnddMnmmOprtngVltg : 16|16@1+ (0.05,0) [0|3212.75] "V" Vector__XXX
 SG_ Hvsp21RmmnddMxmmOprtngVltg : 32|16@1+ (0.05,0) [0|3212.75] "V" Vector__XXX
 SG_ Hvsp21RmmnddMnmmSttOfChrg : 48|16@1+ (0.0015625,0) [0|100.3984375] "%" Vector__XXX
 SG_ Hvsp21RmmnddMxmmSttOfChrg : 64|16@1+ (0.0015625,0) [0|100.3984375] "%" Vector__XXX
 SG_ Hvsp21RmmnddMxmmOprtngTmprtr : 80|16@1+ (0.03125,-273) [-273|1734.96875] "degC" Vector__XXX
 SG_ Hvsp21RmmnddMnmmOprtngTmprtr : 96|16@1+ (0.03125,-273) [-273|1734.96875] "degC" Vector__XXX
 SG_ Hvesp21CellMaximumVoltageLimit : 112|8@1+ (0.02044,0) [0|5.11] "V" Vector__XXX
 SG_ Hvesp21CellMinimumVoltageLimit : 120|8@1+ (0.02044,0) [0|5.11] "V" Vector__XXX
 SG_ Hvesp21NominalRatedCapacity : 128|24@1+ (0.001,0) [0|16449.535] "kWh" Vector__XXX

BO_ 2633669374 HVESP22HIST: 19 Vector__XXX
 SG_ Hvesp22StateOfHealth : 0|8@1+ (0.4,0) [0|100] "%" Vector__XXX
 SG_ Hvsp22CnttrOpnUndrLdCnt : 8|16@1+ (1,0) [0|64255] "count" Vector__XXX
 SG_ Hvesp22TotalEnergyThroughput : 24|32@1+ (100,0) [0|421108121500] "Watt-hour" Vector__XXX
 SG_ Hvesp22TotalAccumulatedCharge : 56|32@1+ (100,0) [0|421108121500] "Ah" Vector__XXX
 SG_ Hvesp22TotalLifetimeEnergyInput : 88|32@1+ (1,0) [0|4211081215] "kWh" Vector__XXX
 SG_ Hvsp22TtlLftmEnrgOtpt : 120|32@1+ (1,0) [0|4211081215] "kWh" Vector__XXX

BO_ 2566560766 HVESP22CFG: 19 Vector__XXX
 SG_ Hvesp22NominalVoltage : 0|16@1+ (0.05,0) [0|3212.75] "V" Vector__XXX
 SG_ Hvsp22RmmnddMnmmOprtngVltg : 16|16@1+ (0.05,0) [0|3212.75] "V" Vector__XXX
 SG_ Hvsp22RmmnddMxmmOprtngVltg : 32|16@1+ (0.05,0) [0|3212.75] "V" Vector__XXX
 SG_ Hvsp22RmmnddMnmmSttOfChrg : 48|16@1+ (0.0015625,0) [0|100.3984375] "%" Vector__XXX
 SG_ Hvsp22RmmnddMxmmSttOfChrg : 64|16@1+ (0.0015625,0) [0|100.3984375] "%" Vector__XXX
 SG_ Hvsp22RmmnddMxmmOprtngTmprtr : 80|16@1+ (0.03125,-273) [-273|1734.96875] "degC" Vector__XXX
 SG_ Hvsp22RmmnddMnmmOprtngTmprtr : 96|16@1+ (0.03125,-273) [-273|1734.96875] "degC" Vector__XXX
 SG_ Hvesp22CellMaximumVoltageLimit : 112|8@1+ (0.02044,0) [0|5.11] "V" Vector__XXX
 SG_ Hvesp22CellMinimumVoltageLimit : 120|8@1+ (0.02044,0) [0|5.11] "V" Vector__XXX
 SG_ Hvesp22NominalRatedCapacity : 128|24@1+ (0.001,0) [0|16449.535] "kWh" Vector__XXX

BO_ 2633669886 HVESP23HIST: 19 Vector__XXX
 SG_ Hvesp23StateOfHealth : 0|8@1+ (0.4,0) [0|100] "%" Vector__XXX
 SG_ Hvsp23CnttrOpnUndrLdCnt : 8|16@1+ (1,0) [0|64255] "count" Vector__XXX
 SG_ Hvesp23TotalEnergyThroughput : 24|32@1+ (100,0) [0|421108121500] "Watt-hour" Vector__XXX
 SG_ Hvesp23TotalAccumulatedCharge : 56|32@1+ (100,0) [0|421108121500] "Ah" Vector__XXX
 SG_ Hvesp23TotalLifetimeEnergyInput : 88|32@1+ (1,0) [0|4211081215] "kWh" Vector__XXX
 SG_ Hvsp23TtlLftmEnrgOtpt : 120|32@1+ (1,0) [0|4211081215] "kWh" Vector__XXX

BO_ 2566561278 HVESP23CFG: 19 Vector__XXX
 SG_ Hvesp23NominalVoltage : 0|16@1+ (0.05,0) [0|3212.75] "V" Vector__XXX
 SG_ Hvsp23RmmnddMnmmOprtngVltg : 16|16@1+ (0.05,0) [0|3212.75] "V" Vector__XXX
 SG_ Hvsp23RmmnddMxmmOprtngVltg : 32|16@1+ (0.05,0) [0|3212.75] "V" Vector__XXX
 SG_ Hvsp23RmmnddMnmmSttOfChrg : 48|16@1+ (0.0015625,0) [0|100.3984375] "%" Vector__XXX
 SG_ Hvsp23RmmnddMxmmSttOfChrg : 64|16@1+ (0.0015625,0) [0|100.3984375] "%" Vector__XXX
 SG_ Hvsp23RmmnddMxmmOprtngTmprtr : 80|16@1+ (0.03125,-273) [-273|1734.96875] "degC" Vector__XXX
 SG_ Hvsp23RmmnddMnmmOprtngTmprtr : 96|16@1+ (0.03125,-273) [-273|1734.96875] "degC" Vector__XXX
 SG_ Hvesp23CellMaximumVoltageLimit : 112|8@1+ (0.02044,0) [0|5.11] "V" Vector__XXX
 SG_ Hvesp23CellMinimumVoltageLimit : 120|8@1+ (0.02044,0) [0|5.11] "V" Vector__XXX
 SG_ Hvesp23NominalRatedCapacity : 128|24@1+ (0.001,0) [0|16449.535] "kWh" Vector__XXX

BO_ 2633670398 HVESP24HIST: 19 Vector__XXX
 SG_ Hvesp24StateOfHealth : 0|8@1+ (0.4,0) [0|100] "%" Vector__XXX
 SG_ Hvsp24CnttrOpnUndrLdCnt : 8|16@1+ (1,0) [0|64255] "count" Vector__XXX
 SG_ Hvesp24TotalEnergyThroughput : 24|32@1+ (100,0) [0|421108121500] "Watt-hour" Vector__XXX
 SG_ Hvesp24TotalAccumulatedCharge : 56|32@1+ (100,0) [0|421108121500] "Ah" Vector__XXX
 SG_ Hvesp24TotalLifetimeEnergyInput : 88|32@1+ (1,0) [0|4211081215] "kWh" Vector__XXX
 SG_ Hvsp24TtlLftmEnrgOtpt : 120|32@1+ (1,0) [0|4211081215] "kWh" Vector__XXX

BO_ 2566561790 HVESP24CFG: 19 Vector__XXX
 SG_ Hvesp24NominalVoltage : 0|16@1+ (0.05,0) [0|3212.75] "V" Vector__XXX
 SG_ Hvsp24RmmnddMnmmOprtngVltg : 16|16@1+ (0.05,0) [0|3212.75] "V" Vector__XXX
 SG_ Hvsp24RmmnddMxmmOprtngVltg : 32|16@1+ (0.05,0) [0|3212.75] "V" Vector__XXX
 SG_ Hvsp24RmmnddMnmmSttOfChrg : 48|16@1+ (0.0015625,0) [0|100.3984375] "%" Vector__XXX
 SG_ Hvsp24RmmnddMxmmSttOfChrg : 64|16@1+ (0.0015625,0) [0|100.3984375] "%" Vector__XXX
 SG_ Hvsp24RmmnddMxmmOprtngTmprtr : 80|16@1+ (0.03125,-273) [-273|1734.96875] "degC" Vector__XXX
 SG_ Hvsp24RmmnddMnmmOprtngTmprtr : 96|16@1+ (0.03125,-273) [-273|1734.96875] "degC" Vector__XXX
 SG_ Hvesp24CellMaximumVoltageLimit : 112|8@1+ (0.02044,0) [0|5.11] "V" Vector__XXX
 SG_ Hvesp24CellMinimumVoltageLimit : 120|8@1+ (0.02044,0) [0|5.11] "V" Vector__XXX
 SG_ Hvesp24NominalRatedCapacity : 128|24@1+ (0.001,0) [0|16449.535] "kWh" Vector__XXX

BO_ 2633670910 HVESP25HIST: 19 Vector__XXX
 SG_ Hvesp25StateOfHealth : 0|8@1+ (0.4,0) [0|100] "%" Vector__XXX
 SG_ Hvsp25CnttrOpnUndrLdCnt : 8|16@1+ (1,0) [0|64255] "count" Vector__XXX
 SG_ Hvesp25TotalEnergyThroughput : 24|32@1+ (100,0) [0|421108121500] "Watt-hour" Vector__XXX
 SG_ Hvesp25TotalAccumulatedCharge : 56|32@1+ (100,0) [0|421108121500] "Ah" Vector__XXX
 SG_ Hvesp25TotalLifetimeEnergyInput : 88|32@1+ (1,0) [0|4211081215] "kWh" Vector__XXX
 SG_ Hvsp25TtlLftmEnrgOtpt : 120|32@1+ (1,0) [0|4211081215] "kWh" Vector__XXX

BO_ 2566562302 HVESP25CFG: 19 Vector__XXX
 SG_ Hvesp25NominalVoltage : 0|16@1+ (0.05,0) [0|3212.75] "V" Vector__XXX
 SG_ Hvsp25RmmnddMnmmOprtngVltg : 16|16@1+ (0.05,0) [0|3212.75] "V" Vector__XXX
 SG_ Hvsp25RmmnddMxmmOprtngVltg : 32|16@1+ (0.05,0) [0|3212.75] "V" Vector__XXX
 SG_ Hvsp25RmmnddMnmmSttOfChrg : 48|16@1+ (0.0015625,0) [0|100.3984375] "%" Vector__XXX
 SG_ Hvsp25RmmnddMxmmSttOfChrg : 64|16@1+ (0.0015625,0) [0|100.3984375] "%" Vector__XXX
 SG_ Hvsp25RmmnddMxmmOprtngTmprtr : 80|16@1+ (0.03125,-273) [-273|1734.96875] "degC" Vector__XXX
 SG_ Hvsp25RmmnddMnmmOprtngTmprtr : 96|16@1+ (0.03125,-273) [-273|1734.96875] "degC" Vector__XXX
 SG_ Hvesp25CellMaximumVoltageLimit : 112|8@1+ (0.02044,0) [0|5.11] "V" Vector__XXX
 SG_ Hvesp25CellMinimumVoltageLimit : 120|8@1+ (0.02044,0) [0|5.11] "V" Vector__XXX
 SG_ Hvesp25NominalRatedCapacity : 128|24@1+ (0.001,0) [0|16449.535] "kWh" Vector__XXX

BO_ 2633671422 HVESP26HIST: 19 Vector__XXX
 SG_ Hvesp26StateOfHealth : 0|8@1+ (0.4,0) [0|100] "%" Vector__XXX
 SG_ Hvsp26CnttrOpnUndrLdCnt : 8|16@1+ (1,0) [0|64255] "count" Vector__XXX
 SG_ Hvesp26TotalEnergyThroughput : 24|32@1+ (100,0) [0|421108121500] "Watt-hour" Vector__XXX
 SG_ Hvesp26TotalAccumulatedCharge : 56|32@1+ (100,0) [0|421108121500] "Ah" Vector__XXX
 SG_ Hvesp26TotalLifetimeEnergyInput : 88|32@1+ (1,0) [0|4211081215] "kWh" Vector__XXX
 SG_ Hvsp26TtlLftmEnrgOtpt : 120|32@1+ (1,0) [0|4211081215] "kWh" Vector__XXX

BO_ 2566562814 HVESP26CFG: 19 Vector__XXX
 SG_ Hvesp26NominalVoltage : 0|16@1+ (0.05,0) [0|3212.75] "V" Vector__XXX
 SG_ Hvsp26RmmnddMnmmOprtngVltg : 16|16@1+ (0.05,0) [0|3212.75] "V" Vector__XXX
 SG_ Hvsp26RmmnddMxmmOprtngVltg : 32|16@1+ (0.05,0) [0|3212.75] "V" Vector__XXX
 SG_ Hvsp26RmmnddMnmmSttOfChrg : 48|16@1+ (0.0015625,0) [0|100.3984375] "%" Vector__XXX
 SG_ Hvsp26RmmnddMxmmSttOfChrg : 64|16@1+ (0.0015625,0) [0|100.3984375] "%" Vector__XXX
 SG_ Hvsp26RmmnddMxmmOprtngTmprtr : 80|16@1+ (0.03125,-273) [-273|1734.96875] "degC" Vector__XXX
 SG_ Hvsp26RmmnddMnmmOprtngTmprtr : 96|16@1+ (0.03125,-273) [-273|1734.96875] "degC" Vector__XXX
 SG_ Hvesp26CellMaximumVoltageLimit : 112|8@1+ (0.02044,0) [0|5.11] "V" Vector__XXX
 SG_ Hvesp26CellMinimumVoltageLimit : 120|8@1+ (0.02044,0) [0|5.11] "V" Vector__XXX
 SG_ Hvesp26NominalRatedCapacity : 128|24@1+ (0.001,0) [0|16449.535] "kWh" Vector__XXX

BO_ 2566563070 ADSC2: 8 Vector__XXX
 SG_ AdsVehicleSpeedControlCommand : 0|16@1+ (0.00390625,0) [0|250.99609375] "km/h" Vector__XXX
 SG_ AdsVhlSpdCntrlCmmndPrrt : 16|3@1+ (1,0) [0|7] "" Vector__XXX
 SG_ Adsc2EmbeddedIntegritySupport : 50|2@1+ (1,0) [0|3] "" Vector__XXX
 SG_ Adsc2Counter : 52|4@1+ (1,0) [0|15] "" Vector__XXX
 SG_ Adsc2Crc : 56|8@1+ (1,0) [0|250] "count" Vector__XXX

BO_ 2566658814 HVESSTC1: 8 Vector__XXX
 SG_ HvssTMtSstItCtTptRqst : 0|8@1+ (1,-40) [-40|210] "degC" Vector__XXX
 SG_ HvssTMtSstOttCtTptRqst : 8|8@1+ (1,-40) [-40|210] "degC" Vector__XXX
 SG_ HvssTMtSstCtFwRtRqst : 16|16@1+ (0.5,0) [0|32127.5] "l/min" Vector__XXX
 SG_ HvssThrmlMngmntSstmHtrEnlCmmnd : 32|2@1+ (1,0) [0|3] "" Vector__XXX
 SG_ HvssTMtSstCtPpECd : 34|2@1+ (1,0) [0|3] "" Vector__XXX
 SG_ HvssTMtSstCpssECd : 36|2@1+ (1,0) [0|3] "" Vector__XXX

BO_ 2365332478 HVESSTC2: 8 Vector__XXX
 SG_ HvssTMtSstCtPpSpdCd : 0|16@1+ (0.5,0) [0|32127.5] "rpm" Vector__XXX
 SG_ HvssTMtSstCtPpPtSpdCd : 16|8@1+ (0.5,0) [0|100] "%" Vector__XXX
 SG_ HvssTMtSstCpssSpdCd : 24|16@1+ (0.5,0) [0|32127.5] "rpm" Vector__XXX
 SG_ HvssTMtSstCpssPtSpdCd : 40|8@1+ (0.5,0) [0|100] "%" Vector__XXX

BO_ 2566679038 EVOI1: 8 Vector__XXX
 SG_ HvessEstimatedRemainingDistance : 0|16@1+ (0.25,0) [0|16063.75] "km" Vector__XXX

BO_ 2566079486 EPBC1: 8 Vector__XXX
 SG_ EltrnPrkBrkPwrUntCntrlArStts : 0|3@1+ (1,0) [0|7] "" Vector__XXX
 SG_ EltrnPrkBrkTwdUntCntrlArStts : 3|3@1+ (1,0) [0|7] "" Vector__XXX
 SG_ EltrnPrkBrkOpnAntRllAwStts : 6|2@1+ (1,0) [0|3] "" Vector__XXX
 SG_ EltrnPrkBrkTrlrBrkRlsStts : 8|2@1+ (1,0) [0|3] "" Vector__XXX
 SG_ EltrnPrkBrkPwrUntVhlTp : 10|2@1+ (1,0) [0|3] "" Vector__XXX
 SG_ EltrnPrkBrkOprtngMd : 12|4@1+ (1,0) [0|15] "" Vector__XXX
 SG_ EtPBTOvdItSvBStts : 16|2@1+ (1,0) [0|3] "" Vector__XXX
 SG_ EtPBTOvdItItStts : 18|2@1+ (1,0) [0|3] "" Vector__XXX
 SG_ EtPBTOvdItStBtSwtStts : 20|2@1+ (1,0) [0|3] "" Vector__XXX
 SG_ EtPBTOvdItD1Stts : 22|2@1+ (1,0) [0|3] "" Vector__XXX
 SG_ EtPBTOvdItD2Stts : 24|2@1+ (1,0) [0|3] "" Vector__XXX
 SG_ EltrnPrkBrkExhstAtSpdStts : 26|3@1+ (1,0) [0|7] "" Vector__XXX
 SG_ ElectronicParkBrakePowerStatus : 29|3@1+ (1,0) [0|7] "" Vector__XXX
 SG_ AntiRollAwayTimer : 32|8@1+ (1,0) [0|240] "s" Vector__XXX
 SG_ EltrnPrkBrkPwrUntSwthStts : 40|3@1+ (1,0) [0|7] "" Vector__XXX
 SG_ EltrnPrkBrkTwdUntSwthStts : 43|3@1+ (1,0) [0|7] "" Vector__XXX

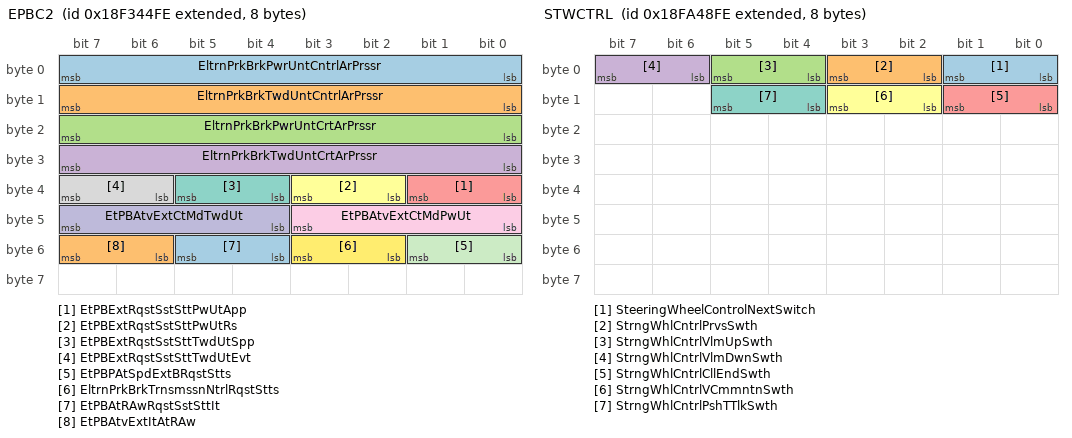
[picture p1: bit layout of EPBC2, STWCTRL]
BO_ 2566079742 EPBC2: 8 Vector__XXX
 SG_ EltrnPrkBrkPwrUntCntrlArPrssr : 0|8@1+ (8,0) [0|2000] "kPa" Vector__XXX
 SG_ EltrnPrkBrkTwdUntCntrlArPrssr : 8|8@1+ (8,0) [0|2000] "kPa" Vector__XXX
 SG_ EltrnPrkBrkPwrUntCrtArPrssr : 16|8@1+ (8,0) [0|2000] "kPa" Vector__XXX
 SG_ EltrnPrkBrkTwdUntCrtArPrssr : 24|8@1+ (8,0) [0|2000] "kPa" Vector__XXX
 SG_ EtPBExtRqstSstSttPwUtApp : 32|2@1+ (1,0) [0|3] "" Vector__XXX
 SG_ EtPBExtRqstSstSttPwUtRs : 34|2@1+ (1,0) [0|3] "" Vector__XXX
 SG_ EtPBExtRqstSstSttTwdUtSpp : 36|2@1+ (1,0) [0|3] "" Vector__XXX
 SG_ EtPBExtRqstSstSttTwdUtEvt : 38|2@1+ (1,0) [0|3] "" Vector__XXX
 SG_ EtPBAtvExtCtMdPwUt : 40|4@1+ (1,0) [0|15] "" Vector__XXX
 SG_ EtPBAtvExtCtMdTwdUt : 44|4@1+ (1,0) [0|15] "" Vector__XXX
 SG_ EtPBPAtSpdExtBRqstStts : 48|2@1+ (1,0) [0|3] "" Vector__XXX
 SG_ EltrnPrkBrkTrnsmssnNtrlRqstStts : 50|2@1+ (1,0) [0|3] "" Vector__XXX
 SG_ EtPBAtRAwRqstSstSttIt : 52|2@1+ (1,0) [0|3] "" Vector__XXX
 SG_ EtPBAtvExtItAtRAw : 54|2@1+ (1,0) [0|3] "" Vector__XXX

BO_ 2566538494 LF2: 8 Vector__XXX
 SG_ TripAverageLoadFactor : 0|8@1+ (0.4,0) [0|100] "%" Vector__XXX
 SG_ TotalAverageLoadFactor : 8|8@1+ (0.4,0) [0|100] "%" Vector__XXX

BO_ 2365212158 GTRACE2: 8 Vector__XXX
 SG_ GeneratorTripKvarHoursImport : 0|32@1+ (1,0) [0|4211081215] "kVArh" Vector__XXX

BO_ 2566539006 SSMOI: 8 Vector__XXX
 SG_ SrtSstmTmTDslMhnOprtn : 0|16@1+ (1,0) [0|64255] "min" Vector__XXX
 SG_ SrtSstmTmTLmtMhnOprtn : 16|16@1+ (1,0) [0|64255] "min" Vector__XXX
 SG_ SrtSstmMhnOprtnDslRsn : 32|4@1+ (1,0) [0|15] "" Vector__XXX
 SG_ SrtSstmMhnOprtnLmtRsn : 36|4@1+ (1,0) [0|15] "" Vector__XXX
 SG_ SrtSstmMhnOprtnStts : 40|3@1+ (1,0) [0|7] "" Vector__XXX

BO_ 2566539262 EFASM: 8 Vector__XXX
 SG_ FuelActuator1ServiceModeRequest : 0|2@1+ (1,0) [0|3] "" Vector__XXX
 SG_ FuelActuator2ServiceModeRequest : 2|2@1+ (1,0) [0|3] "" Vector__XXX

BO_ 2566539518 STWCTRL: 8 Vector__XXX
 SG_ SteeringWheelControlNextSwitch : 0|2@1+ (1,0) [0|3] "" Vector__XXX
 SG_ StrngWhlCntrlPrvsSwth : 2|2@1+ (1,0) [0|3] "" Vector__XXX
 SG_ StrngWhlCntrlVlmUpSwth : 4|2@1+ (1,0) [0|3] "" Vector__XXX
 SG_ StrngWhlCntrlVlmDwnSwth : 6|2@1+ (1,0) [0|3] "" Vector__XXX
 SG_ StrngWhlCntrlCllEndSwth : 8|2@1+ (1,0) [0|3] "" Vector__XXX
 SG_ StrngWhlCntrlVCmmntnSwth : 10|2@1+ (1,0) [0|3] "" Vector__XXX
 SG_ StrngWhlCntrlPshTTlkSwth : 12|2@1+ (1,0) [0|3] "" Vector__XXX

BO_ 2566539774 PA: 8 Vector__XXX
 SG_ FrontParkAssistStatus : 0|3@1+ (1,0) [0|7] "" Vector__XXX
 SG_ RearParkAssistStatus : 3|3@1+ (1,0) [0|7] "" Vector__XXX

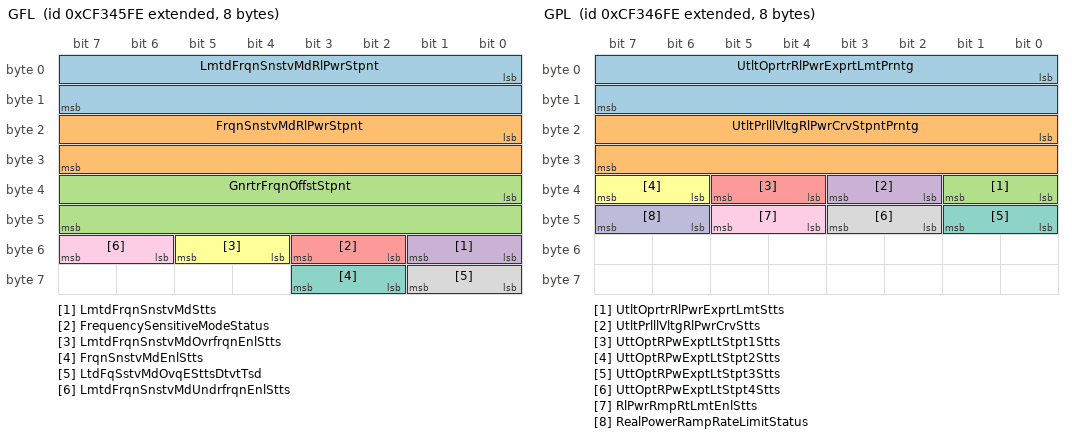
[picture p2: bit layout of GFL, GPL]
BO_ 2364753406 GFL: 8 Vector__XXX
 SG_ LmtdFrqnSnstvMdRlPwrStpnt : 0|16@1+ (0.01,-321.27) [-321.27|321.28] "%" Vector__XXX
 SG_ FrqnSnstvMdRlPwrStpnt : 16|16@1+ (0.01,-321.27) [-321.27|321.28] "%" Vector__XXX
 SG_ GnrtrFrqnOffstStpnt : 32|16@1+ (0.0078125,0) [0|501.9921875] "Hz" Vector__XXX
 SG_ LmtdFrqnSnstvMdStts : 48|2@1+ (1,0) [0|3] "" Vector__XXX
 SG_ FrequencySensitiveModeStatus : 50|2@1+ (1,0) [0|3] "" Vector__XXX
 SG_ LmtdFrqnSnstvMdOvrfrqnEnlStts : 52|2@1+ (1,0) [0|3] "" Vector__XXX
 SG_ FrqnSnstvMdEnlStts : 58|2@1+ (1,0) [0|3] "" Vector__XXX
 SG_ LtdFqSstvMdOvqESttsDtvtTsd : 56|2@1+ (1,0) [0|3] "" Vector__XXX
 SG_ LmtdFrqnSnstvMdUndrfrqnEnlStts : 54|2@1+ (1,0) [0|3] "" Vector__XXX

BO_ 2364753662 GPL: 8 Vector__XXX
 SG_ UtltOprtrRlPwrExprtLmtPrntg : 0|16@1+ (0.01,-321.27) [-321.27|321.28] "%" Vector__XXX
 SG_ UtltPrlllVltgRlPwrCrvStpntPrntg : 16|16@1+ (0.01,-321.27) [-321.27|321.28] "%" Vector__XXX
 SG_ UtltOprtrRlPwrExprtLmtStts : 32|2@1+ (1,0) [0|3] "" Vector__XXX
 SG_ UtltPrlllVltgRlPwrCrvStts : 34|2@1+ (1,0) [0|3] "" Vector__XXX
 SG_ UttOptRPwExptLtStpt1Stts : 36|2@1+ (1,0) [0|3] "" Vector__XXX
 SG_ UttOptRPwExptLtStpt2Stts : 38|2@1+ (1,0) [0|3] "" Vector__XXX
 SG_ UttOptRPwExptLtStpt3Stts : 40|2@1+ (1,0) [0|3] "" Vector__XXX
 SG_ UttOptRPwExptLtStpt4Stts : 42|2@1+ (1,0) [0|3] "" Vector__XXX
 SG_ RlPwrRmpRtLmtEnlStts : 44|2@1+ (1,0) [0|3] "" Vector__XXX
 SG_ RealPowerRampRateLimitStatus : 46|2@1+ (1,0) [0|3] "" Vector__XXX

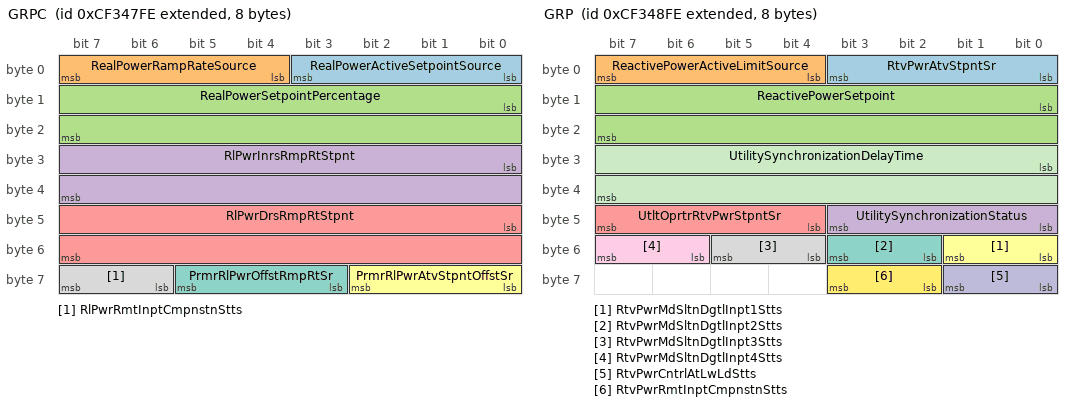
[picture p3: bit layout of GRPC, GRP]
BO_ 2364753918 GRPC: 8 Vector__XXX
 SG_ RealPowerActiveSetpointSource : 0|4@1+ (1,0) [0|15] "" Vector__XXX
 SG_ RealPowerRampRateSource : 4|4@1+ (1,0) [0|15] "" Vector__XXX
 SG_ RealPowerSetpointPercentage : 8|16@1+ (0.01,-321.27) [-321.27|321.28] "%" Vector__XXX
 SG_ RlPwrInrsRmpRtStpnt : 24|16@1+ (0.01,0) [0|642.55] "%/s" Vector__XXX
 SG_ RlPwrDrsRmpRtStpnt : 40|16@1+ (0.01,0) [0|642.55] "%/s" Vector__XXX
 SG_ PrmrRlPwrAtvStpntOffstSr : 56|3@1+ (1,0) [0|7] "" Vector__XXX
 SG_ PrmrRlPwrOffstRmpRtSr : 59|3@1+ (1,0) [0|7] "" Vector__XXX
 SG_ RlPwrRmtInptCmpnstnStts : 62|2@1+ (1,0) [0|3] "" Vector__XXX

BO_ 2364754174 GRP: 8 Vector__XXX
 SG_ RtvPwrAtvStpntSr : 0|4@1+ (1,0) [0|15] "" Vector__XXX
 SG_ ReactivePowerActiveLimitSource : 4|4@1+ (1,0) [0|15] "" Vector__XXX
 SG_ ReactivePowerSetpoint : 8|16@1+ (0.01,-321.27) [-321.27|321.28] "%" Vector__XXX
 SG_ UtilitySynchronizationStatus : 40|4@1+ (1,0) [0|15] "" Vector__XXX
 SG_ UtltOprtrRtvPwrStpntSr : 44|4@1+ (1,0) [0|15] "" Vector__XXX
 SG_ RtvPwrMdSltnDgtlInpt1Stts : 48|2@1+ (1,0) [0|3] "" Vector__XXX
 SG_ RtvPwrMdSltnDgtlInpt2Stts : 50|2@1+ (1,0) [0|3] "" Vector__XXX
 SG_ RtvPwrMdSltnDgtlInpt3Stts : 52|2@1+ (1,0) [0|3] "" Vector__XXX
 SG_ RtvPwrMdSltnDgtlInpt4Stts : 54|2@1+ (1,0) [0|3] "" Vector__XXX
 SG_ RtvPwrCntrlAtLwLdStts : 56|2@1+ (1,0) [0|3] "" Vector__XXX
 SG_ UtilitySynchronizationDelayTime : 24|16@1+ (1,0) [0|64255] "s" Vector__XXX
 SG_ RtvPwrRmtInptCmpnstnStts : 58|2@1+ (1,0) [0|3] "" Vector__XXX

BO_ 2566081022 FCCI: 8 Vector__XXX
 SG_ FlCllEnlsr1HdrgnCnntrtn : 0|8@1+ (500,0) [0|125000] "ppm" Vector__XXX
 SG_ FlCllEnlsr2HdrgnCnntrtn : 8|8@1+ (500,0) [0|125000] "ppm" Vector__XXX
 SG_ FlCllCmprtmntHdrgnCnntrtn : 16|8@1+ (500,0) [0|125000] "ppm" Vector__XXX

BO_ 2365210878 ETC15: 8 Vector__XXX
 SG_ EltrnTrnsmssnCntrl15Cr : 0|8@1+ (1,0) [0|250] "count" Vector__XXX
 SG_ EltrnTrnsmssnCntrl15Cntr : 8|4@1+ (1,0) [0|15] "count" Vector__XXX
 SG_ TrnsmssnAtNtrlAtRtrnRqstFdk : 16|3@1+ (1,0) [0|7] "" Vector__XXX
 SG_ TrnsmssnAtNtrlAtRtrnFntnStt : 24|4@1+ (1,0) [0|15] "" Vector__XXX
 SG_ LaunchProcessStatus : 19|2@1+ (1,0) [0|3] "" Vector__XXX

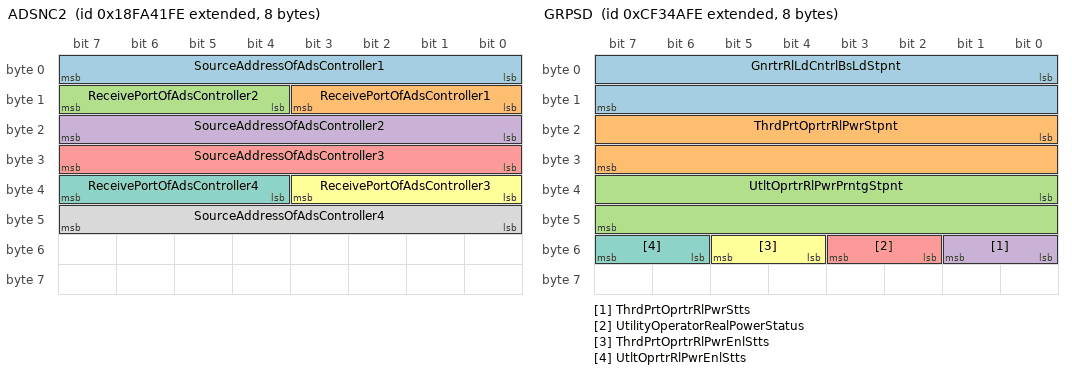
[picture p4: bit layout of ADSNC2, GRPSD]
BO_ 2566537726 ADSNC2: 8 Vector__XXX
 SG_ SourceAddressOfAdsController1 : 0|8@1+ (1,0) [0|250] "sourceadr" Vector__XXX
 SG_ ReceivePortOfAdsController1 : 8|4@1+ (1,0) [0|15] "" Vector__XXX
 SG_ ReceivePortOfAdsController2 : 12|4@1+ (1,0) [0|15] "" Vector__XXX
 SG_ SourceAddressOfAdsController2 : 16|8@1+ (1,0) [0|250] "sourceadr" Vector__XXX
 SG_ SourceAddressOfAdsController3 : 24|8@1+ (1,0) [0|250] "sourceadr" Vector__XXX
 SG_ ReceivePortOfAdsController3 : 32|4@1+ (1,0) [0|15] "" Vector__XXX
 SG_ ReceivePortOfAdsController4 : 36|4@1+ (1,0) [0|15] "" Vector__XXX
 SG_ SourceAddressOfAdsController4 : 40|8@1+ (1,0) [0|250] "sourceadr" Vector__XXX

BO_ 2499429374 HSI2: 8 Vector__XXX
 SG_ HrdOrEvSstmTtlRgnrtvBrkngLvl : 16|8@1+ (0.4,0) [0|100] "%" Vector__XXX

BO_ 2566686206 FCHTRC: 8 Vector__XXX
 SG_ FlCllAxlrHtrMdRqst : 0|4@1+ (1,0) [0|15] "" Vector__XXX
 SG_ FlCllAxlrHtrOtptClntTmprtrStpnt : 16|16@1+ (0.0078125,-273) [-273|228.9921875] "degC" Vector__XXX
 SG_ FlCllAxlrHtrOtptPwrPrntCmmnd : 8|8@1+ (0.4,0) [0|100] "%" Vector__XXX

BO_ 2566686462 FCHTR: 8 Vector__XXX
 SG_ FuelCellAuxiliaryHeaterMode : 0|4@1+ (1,0) [0|15] "" Vector__XXX
 SG_ FlCllAxlrHtrOtptPwrPrnt : 8|8@1+ (0.4,0) [0|100] "%" Vector__XXX
 SG_ FlCllAxlrHtrOtptClntTmprtr : 16|16@1+ (0.0078125,-273) [-273|228.9921875] "degC" Vector__XXX
 SG_ FlCllAxlrHtrInptCrrntLvl : 32|8@1+ (0.25,0) [0|62.5] "A" Vector__XXX
 SG_ FlCllAxlrHtrInptVltgLvl : 40|16@1+ (1,0) [0|64255] "V" Vector__XXX

BO_ 2566686718 FCCP1C: 8 Vector__XXX
 SG_ FlCllClntPmp1SpdCmmnd : 0|16@1+ (0.5,0) [0|32127.5] "rpm" Vector__XXX
 SG_ FlCllClntPmp1PrntSpdCmmnd : 16|8@1+ (0.5,0) [0|125] "%" Vector__XXX
 SG_ FlCllClntPmp1EnlCmmnd : 24|2@1+ (1,0) [0|3] "" Vector__XXX

BO_ 2566686974 FCCP2C: 8 Vector__XXX
 SG_ FlCllClntPmp2SpdCmmnd : 0|16@1+ (0.5,0) [0|32127.5] "rpm" Vector__XXX
 SG_ FlCllClntPmp2PrntSpdCmmnd : 16|8@1+ (0.5,0) [0|125] "%" Vector__XXX
 SG_ FlCllClntPmp2EnlCmmnd : 24|2@1+ (1,0) [0|3] "" Vector__XXX

BO_ 2566687230 FCCP1S: 8 Vector__XXX
 SG_ FuelCellCoolantPump1Speed : 0|16@1+ (0.5,0) [0|32127.5] "rpm" Vector__XXX
 SG_ FlCllClntPmp1InptVltg : 16|16@1+ (1,0) [0|64255] "V" Vector__XXX
 SG_ FlCllClntPmp1InptCrrnt : 32|16@1+ (0.001,0) [0|64.255] "A" Vector__XXX
 SG_ FlCllClntPmp1EnlStts : 48|2@1+ (1,0) [0|3] "" Vector__XXX

BO_ 2566687486 FCCP2S: 8 Vector__XXX
 SG_ FuelCellCoolantPump2Speed : 0|16@1+ (0.5,0) [0|32127.5] "rpm" Vector__XXX
 SG_ FlCllClntPmp2InptVltg : 16|16@1+ (1,0) [0|64255] "V" Vector__XXX
 SG_ FlCllClntPmp2InptCrrnt : 32|16@1+ (0.001,0) [0|64.255] "A" Vector__XXX
 SG_ FlCllClntPmp2EnlStts : 48|2@1+ (1,0) [0|3] "" Vector__XXX

BO_ 2364754686 GRPSD: 8 Vector__XXX
 SG_ GnrtrRlLdCntrlBsLdStpnt : 0|16@1+ (0.01,-321.27) [-321.27|321.28] "%" Vector__XXX
 SG_ ThrdPrtOprtrRlPwrStpnt : 16|16@1+ (0.01,-321.27) [-321.27|321.28] "%" Vector__XXX
 SG_ UtltOprtrRlPwrPrntgStpnt : 32|16@1+ (0.01,-321.27) [-321.27|321.28] "%" Vector__XXX
 SG_ ThrdPrtOprtrRlPwrStts : 48|2@1+ (1,0) [0|3] "" Vector__XXX
 SG_ UtilityOperatorRealPowerStatus : 50|2@1+ (1,0) [0|3] "" Vector__XXX
 SG_ ThrdPrtOprtrRlPwrEnlStts : 52|2@1+ (1,0) [0|3] "" Vector__XXX
 SG_ UtltOprtrRlPwrEnlStts : 54|2@1+ (1,0) [0|3] "" Vector__XXX

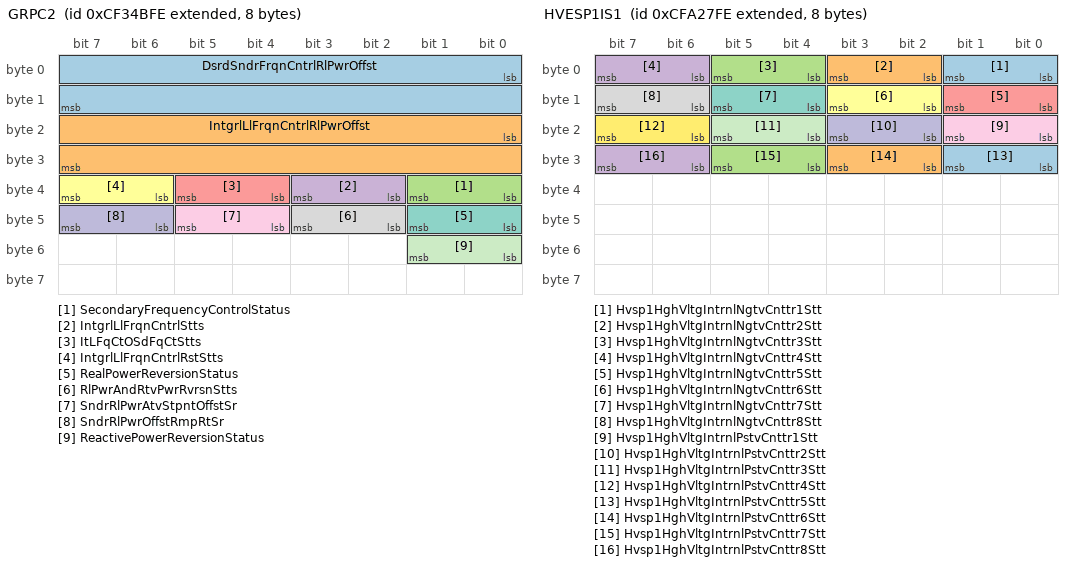
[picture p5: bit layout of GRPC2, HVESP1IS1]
BO_ 2364754942 GRPC2: 8 Vector__XXX
 SG_ DsrdSndrFrqnCntrlRlPwrOffst : 0|16@1+ (0.01,-321.27) [-321.27|321.28] "%" Vector__XXX
 SG_ IntgrlLlFrqnCntrlRlPwrOffst : 16|16@1+ (0.01,-321.27) [-321.27|321.28] "%" Vector__XXX
 SG_ SecondaryFrequencyControlStatus : 32|2@1+ (1,0) [0|3] "" Vector__XXX
 SG_ IntgrlLlFrqnCntrlStts : 34|2@1+ (1,0) [0|3] "" Vector__XXX
 SG_ ItLFqCtOSdFqCtStts : 36|2@1+ (1,0) [0|3] "" Vector__XXX
 SG_ IntgrlLlFrqnCntrlRstStts : 38|2@1+ (1,0) [0|3] "" Vector__XXX
 SG_ RealPowerReversionStatus : 40|2@1+ (1,0) [0|3] "" Vector__XXX
 SG_ RlPwrAndRtvPwrRvrsnStts : 42|2@1+ (1,0) [0|3] "" Vector__XXX
 SG_ SndrRlPwrAtvStpntOffstSr : 44|2@1+ (1,0) [0|3] "" Vector__XXX
 SG_ SndrRlPwrOffstRmpRtSr : 46|2@1+ (1,0) [0|3] "" Vector__XXX
 SG_ ReactivePowerReversionStatus : 48|2@1+ (1,0) [0|3] "" Vector__XXX

BO_ 2364755198 HVESP1D12: 8 Vector__XXX
 SG_ Hvsp1AvllDshrgPwrExtnddRng : 0|16@1+ (0.25,0) [0|16063.75] "kW" Vector__XXX
 SG_ Hvsp1AvllChrgPwrExtnddRng : 16|16@1+ (0.25,0) [0|16063.75] "kW" Vector__XXX
 SG_ Hvesp1VoltageLevelExtendedRange : 32|16@1+ (0.125,0) [0|8031.875] "V" Vector__XXX
 SG_ Hvesp1CurrentExtendedRange : 48|16@1+ (0.125,-4000) [-4000|4031.875] "A" Vector__XXX

BO_ 2364755454 HVESP1D13: 8 Vector__XXX
 SG_ Hvsp1MxIsttsDsCtLtExtddR : 0|16@1+ (0.125,-4000) [-4000|0] "A" Vector__XXX
 SG_ Hvsp1MxIsttsCCtLtExtddR : 16|16@1+ (0.125,-4000) [0|4031.875] "A" Vector__XXX
 SG_ Hvsp1NmnlDshrgCrrntLmt : 32|16@1+ (0.125,-4000) [-4000|0] "A" Vector__XXX
 SG_ Hvesp1NominalChargeCurrentLimit : 48|16@1+ (0.125,-4000) [0|4031.875] "A" Vector__XXX

BO_ 2364755710 HVESP2D12: 8 Vector__XXX
 SG_ Hvsp2AvllDshrgPwrExtnddRng : 0|16@1+ (0.25,0) [0|16063.75] "kW" Vector__XXX
 SG_ Hvsp2AvllChrgPwrExtnddRng : 16|16@1+ (0.25,0) [0|16063.75] "kW" Vector__XXX
 SG_ Hvesp2VoltageLevelExtendedRange : 32|16@1+ (0.125,0) [0|8031.875] "V" Vector__XXX
 SG_ Hvesp2CurrentExtendedRange : 48|16@1+ (0.125,-4000) [-4000|4031.875] "A" Vector__XXX

BO_ 2364755966 HVESP2D13: 8 Vector__XXX
 SG_ Hvsp2MxIsttsDsCtLtExtddR : 0|16@1+ (0.125,-4000) [-4000|0] "A" Vector__XXX
 SG_ Hvsp2MxIsttsCCtLtExtddR : 16|16@1+ (0.125,-4000) [0|4031.875] "A" Vector__XXX
 SG_ Hvsp2NmnlDshrgCrrntLmt : 32|16@1+ (0.125,-4000) [-4000|0] "A" Vector__XXX
 SG_ Hvesp2NominalChargeCurrentLimit : 48|16@1+ (0.125,-4000) [0|4031.875] "A" Vector__XXX

BO_ 2364756222 HVESP3D12: 8 Vector__XXX
 SG_ Hvsp3AvllDshrgPwrExtnddRng : 0|16@1+ (0.25,0) [0|16063.75] "kW" Vector__XXX
 SG_ Hvsp3AvllChrgPwrExtnddRng : 16|16@1+ (0.25,0) [0|16063.75] "kW" Vector__XXX
 SG_ Hvesp3VoltageLevelExtendedRange : 32|16@1+ (0.125,0) [0|8031.875] "V" Vector__XXX
 SG_ Hvesp3CurrentExtendedRange : 48|16@1+ (0.125,-4000) [-4000|4031.875] "A" Vector__XXX

BO_ 2364756478 HVESP3D13: 8 Vector__XXX
 SG_ Hvsp3MxIsttsDsCtLtExtddR : 0|16@1+ (0.125,-4000) [-4000|0] "A" Vector__XXX
 SG_ Hvsp3MxIsttsCCtLtExtddR : 16|16@1+ (0.125,-4000) [0|4031.875] "A" Vector__XXX
 SG_ Hvsp3NmnlDshrgCrrntLmt : 32|16@1+ (0.125,-4000) [-4000|0] "A" Vector__XXX
 SG_ Hvesp3NominalChargeCurrentLimit : 48|16@1+ (0.125,-4000) [0|4031.875] "A" Vector__XXX

BO_ 2364756734 HVESP4D12: 8 Vector__XXX
 SG_ Hvsp4AvllDshrgPwrExtnddRng : 0|16@1+ (0.25,0) [0|16063.75] "kW" Vector__XXX
 SG_ Hvsp4AvllChrgPwrExtnddRng : 16|16@1+ (0.25,0) [0|16063.75] "kW" Vector__XXX
 SG_ Hvesp4VoltageLevelExtendedRange : 32|16@1+ (0.125,0) [0|8031.875] "V" Vector__XXX
 SG_ Hvesp4CurrentExtendedRange : 48|16@1+ (0.125,-4000) [-4000|4031.875] "A" Vector__XXX

BO_ 2364756990 HVESP4D13: 8 Vector__XXX
 SG_ Hvsp4MxIsttsDsCtLtExtddR : 0|16@1+ (0.125,-4000) [-4000|0] "A" Vector__XXX
 SG_ Hvsp4MxIsttsCCtLtExtddR : 16|16@1+ (0.125,-4000) [0|4031.875] "A" Vector__XXX
 SG_ Hvsp4NmnlDshrgCrrntLmt : 32|16@1+ (0.125,-4000) [-4000|0] "A" Vector__XXX
 SG_ Hvesp4NominalChargeCurrentLimit : 48|16@1+ (0.125,-4000) [0|4031.875] "A" Vector__XXX

BO_ 2364757246 HVESP5D12: 8 Vector__XXX
 SG_ Hvsp5AvllDshrgPwrExtnddRng : 0|16@1+ (0.25,0) [0|16063.75] "kW" Vector__XXX
 SG_ Hvsp5AvllChrgPwrExtnddRng : 16|16@1+ (0.25,0) [0|16063.75] "kW" Vector__XXX
 SG_ Hvesp5VoltageLevelExtendedRange : 32|16@1+ (0.125,0) [0|8031.875] "V" Vector__XXX
 SG_ Hvesp5CurrentExtendedRange : 48|16@1+ (0.125,-4000) [-4000|4031.875] "A" Vector__XXX

BO_ 2364757502 HVESP5D13: 8 Vector__XXX
 SG_ Hvsp5MxIsttsDsCtLtExtddR : 0|16@1+ (0.125,-4000) [-4000|0] "A" Vector__XXX
 SG_ Hvsp5MxIsttsCCtLtExtddR : 16|16@1+ (0.125,-4000) [0|4031.875] "A" Vector__XXX
 SG_ Hvsp5NmnlDshrgCrrntLmt : 32|16@1+ (0.125,-4000) [-4000|0] "A" Vector__XXX
 SG_ Hvesp5NominalChargeCurrentLimit : 48|16@1+ (0.125,-4000) [0|4031.875] "A" Vector__XXX

BO_ 2364757758 HVESP6D12: 8 Vector__XXX
 SG_ Hvsp6AvllDshrgPwrExtnddRng : 0|16@1+ (0.25,0) [0|16063.75] "kW" Vector__XXX
 SG_ Hvsp6AvllChrgPwrExtnddRng : 16|16@1+ (0.25,0) [0|16063.75] "kW" Vector__XXX
 SG_ Hvesp6VoltageLevelExtendedRange : 32|16@1+ (0.125,0) [0|8031.875] "V" Vector__XXX
 SG_ Hvesp6CurrentExtendedRange : 48|16@1+ (0.125,-4000) [-4000|4031.875] "A" Vector__XXX

BO_ 2364758014 HVESP6D13: 8 Vector__XXX
 SG_ Hvsp6MxIsttsDsCtLtExtddR : 0|16@1+ (0.125,-4000) [-4000|0] "A" Vector__XXX
 SG_ Hvsp6MxIsttsCCtLtExtddR : 16|16@1+ (0.125,-4000) [0|4031.875] "A" Vector__XXX
 SG_ Hvsp6NmnlDshrgCrrntLmt : 32|16@1+ (0.125,-4000) [-4000|0] "A" Vector__XXX
 SG_ Hvesp6NominalChargeCurrentLimit : 48|16@1+ (0.125,-4000) [0|4031.875] "A" Vector__XXX

BO_ 2364758270 HVESP7D12: 8 Vector__XXX
 SG_ Hvsp7AvllDshrgPwrExtnddRng : 0|16@1+ (0.25,0) [0|16063.75] "kW" Vector__XXX
 SG_ Hvsp7AvllChrgPwrExtnddRng : 16|16@1+ (0.25,0) [0|16063.75] "kW" Vector__XXX
 SG_ Hvesp7VoltageLevelExtendedRange : 32|16@1+ (0.125,0) [0|8031.875] "V" Vector__XXX
 SG_ Hvesp7CurrentExtendedRange : 48|16@1+ (0.125,-4000) [-4000|4031.875] "A" Vector__XXX

BO_ 2364758526 HVESP7D13: 8 Vector__XXX
 SG_ Hvsp7MxIsttsDsCtLtExtddR : 0|16@1+ (0.125,-4000) [-4000|0] "A" Vector__XXX
 SG_ Hvsp7MxIsttsCCtLtExtddR : 16|16@1+ (0.125,-4000) [0|4031.875] "A" Vector__XXX
 SG_ Hvsp7NmnlDshrgCrrntLmt : 32|16@1+ (0.125,-4000) [-4000|0] "A" Vector__XXX
 SG_ Hvesp7NominalChargeCurrentLimit : 48|16@1+ (0.125,-4000) [0|4031.875] "A" Vector__XXX

BO_ 2364758782 HVESP8D12: 8 Vector__XXX
 SG_ Hvsp8AvllDshrgPwrExtnddRng : 0|16@1+ (0.25,0) [0|16063.75] "kW" Vector__XXX
 SG_ Hvsp8AvllChrgPwrExtnddRng : 16|16@1+ (0.25,0) [0|16063.75] "kW" Vector__XXX
 SG_ Hvesp8VoltageLevelExtendedRange : 32|16@1+ (0.125,0) [0|8031.875] "V" Vector__XXX
 SG_ Hvesp8CurrentExtendedRange : 48|16@1+ (0.125,-4000) [-4000|4031.875] "A" Vector__XXX

BO_ 2364759038 HVESP8D13: 8 Vector__XXX
 SG_ Hvsp8MxIsttsDsCtLtExtddR : 0|16@1+ (0.125,-4000) [-4000|0] "A" Vector__XXX
 SG_ Hvsp8MxIsttsCCtLtExtddR : 16|16@1+ (0.125,-4000) [0|4031.875] "A" Vector__XXX
 SG_ Hvsp8NmnlDshrgCrrntLmt : 32|16@1+ (0.125,-4000) [-4000|0] "A" Vector__XXX
 SG_ Hvesp8NominalChargeCurrentLimit : 48|16@1+ (0.125,-4000) [0|4031.875] "A" Vector__XXX

BO_ 2364759294 HVESP9D12: 8 Vector__XXX
 SG_ Hvsp9AvllDshrgPwrExtnddRng : 0|16@1+ (0.25,0) [0|16063.75] "kW" Vector__XXX
 SG_ Hvsp9AvllChrgPwrExtnddRng : 16|16@1+ (0.25,0) [0|16063.75] "kW" Vector__XXX
 SG_ Hvesp9VoltageLevelExtendedRange : 32|16@1+ (0.125,0) [0|8031.875] "V" Vector__XXX
 SG_ Hvesp9CurrentExtendedRange : 48|16@1+ (0.125,-4000) [-4000|4031.875] "A" Vector__XXX

BO_ 2364759550 HVESP9D13: 8 Vector__XXX
 SG_ Hvsp9MxIsttsDsCtLtExtddR : 0|16@1+ (0.125,-4000) [-4000|0] "A" Vector__XXX
 SG_ Hvsp9MxIsttsCCtLtExtddR : 16|16@1+ (0.125,-4000) [0|4031.875] "A" Vector__XXX
 SG_ Hvsp9NmnlDshrgCrrntLmt : 32|16@1+ (0.125,-4000) [-4000|0] "A" Vector__XXX
 SG_ Hvesp9NominalChargeCurrentLimit : 48|16@1+ (0.125,-4000) [0|4031.875] "A" Vector__XXX

BO_ 2364759806 HVESP10D12: 8 Vector__XXX
 SG_ Hvsp10AvllDshrgPwrExtnddRng : 0|16@1+ (0.25,0) [0|16063.75] "kW" Vector__XXX
 SG_ Hvsp10AvllChrgPwrExtnddRng : 16|16@1+ (0.25,0) [0|16063.75] "kW" Vector__XXX
 SG_ Hvsp10VltgLvlExtnddRng : 32|16@1+ (0.125,0) [0|8031.875] "V" Vector__XXX
 SG_ Hvesp10CurrentExtendedRange : 48|16@1+ (0.125,-4000) [-4000|4031.875] "A" Vector__XXX

BO_ 2364760062 HVESP10D13: 8 Vector__XXX
 SG_ Hvsp10MxIsttsDsCtLtExtddR : 0|16@1+ (0.125,-4000) [-4000|0] "A" Vector__XXX
 SG_ Hvsp10MxIsttsCCtLtExtddR : 16|16@1+ (0.125,-4000) [0|4031.875] "A" Vector__XXX
 SG_ Hvsp10NmnlDshrgCrrntLmt : 32|16@1+ (0.125,-4000) [-4000|0] "A" Vector__XXX
 SG_ Hvsp10NmnlChrgCrrntLmt : 48|16@1+ (0.125,-4000) [0|4031.875] "A" Vector__XXX

BO_ 2364760318 HVESP11D12: 8 Vector__XXX
 SG_ Hvsp11AvllDshrgPwrExtnddRng : 0|16@1+ (0.25,0) [0|16063.75] "kW" Vector__XXX
 SG_ Hvsp11AvllChrgPwrExtnddRng : 16|16@1+ (0.25,0) [0|16063.75] "kW" Vector__XXX
 SG_ Hvsp11VltgLvlExtnddRng : 32|16@1+ (0.125,0) [0|8031.875] "V" Vector__XXX
 SG_ Hvesp11CurrentExtendedRange : 48|16@1+ (0.125,-4000) [-4000|4031.875] "A" Vector__XXX

BO_ 2364760574 HVESP11D13: 8 Vector__XXX
 SG_ Hvsp11MxIsttsDsCtLtExtddR : 0|16@1+ (0.125,-4000) [-4000|0] "A" Vector__XXX
 SG_ Hvsp11MxIsttsCCtLtExtddR : 16|16@1+ (0.125,-4000) [0|4031.875] "A" Vector__XXX
 SG_ Hvsp11NmnlDshrgCrrntLmt : 32|16@1+ (0.125,-4000) [-4000|0] "A" Vector__XXX
 SG_ Hvsp11NmnlChrgCrrntLmt : 48|16@1+ (0.125,-4000) [0|4031.875] "A" Vector__XXX

BO_ 2364760830 HVESP12D12: 8 Vector__XXX
 SG_ Hvsp12AvllDshrgPwrExtnddRng : 0|16@1+ (0.25,0) [0|16063.75] "kW" Vector__XXX
 SG_ Hvsp12AvllChrgPwrExtnddRng : 16|16@1+ (0.25,0) [0|16063.75] "kW" Vector__XXX
 SG_ Hvsp12VltgLvlExtnddRng : 32|16@1+ (0.125,0) [0|8031.875] "V" Vector__XXX
 SG_ Hvesp12CurrentExtendedRange : 48|16@1+ (0.125,-4000) [-4000|4031.875] "A" Vector__XXX

BO_ 2364761086 HVESP12D13: 8 Vector__XXX
 SG_ Hvsp12MxIsttsDsCtLtExtddR : 0|16@1+ (0.125,-4000) [-4000|0] "A" Vector__XXX
 SG_ Hvsp12MxIsttsCCtLtExtddR : 16|16@1+ (0.125,-4000) [0|4031.875] "A" Vector__XXX
 SG_ Hvsp12NmnlDshrgCrrntLmt : 32|16@1+ (0.125,-4000) [-4000|0] "A" Vector__XXX
 SG_ Hvsp12NmnlChrgCrrntLmt : 48|16@1+ (0.125,-4000) [0|4031.875] "A" Vector__XXX

BO_ 2365203710 HVESSD12: 8 Vector__XXX
 SG_ HvessIntakeCoolantPressure : 0|8@1+ (2,0) [0|500] "kPa" Vector__XXX
 SG_ HvssEstmtdDshrgTmRmnng : 8|16@1+ (0.1,0) [0|6425.5] "min" Vector__XXX
 SG_ HvssEstmtdChrgTmRmnng : 24|16@1+ (0.1,0) [0|6425.5] "min" Vector__XXX
 SG_ HvssHghVltgExpsrIndtr : 40|2@1+ (1,0) [0|3] "" Vector__XXX
 SG_ HvessPowerHoldRelayStatus : 42|2@1+ (1,0) [0|3] "" Vector__XXX
 SG_ HvssHghVltgBsPstvPrChrgRlStt : 44|2@1+ (1,0) [0|3] "" Vector__XXX
 SG_ HvssHghVltgBsNgtvPrChrgRlStt : 46|2@1+ (1,0) [0|3] "" Vector__XXX

BO_ 2365203966 HVESSD13: 8 Vector__XXX
 SG_ HvssAvllDshrgPwrExtnddRng : 0|16@1+ (0.25,0) [0|16063.75] "kW" Vector__XXX
 SG_ HvssAvllChrgPwrExtnddRng : 16|16@1+ (0.25,0) [0|16063.75] "kW" Vector__XXX
 SG_ HvessVoltageLevelExtendedRange : 32|16@1+ (0.125,0) [0|8031.875] "V" Vector__XXX
 SG_ HvessCurrentExtendedRange : 48|16@1+ (0.125,-4000) [-4000|4031.875] "A" Vector__XXX

BO_ 2365204222 HVESSD14: 8 Vector__XXX
 SG_ HvessBusVoltageExtendedRange : 32|16@1+ (0.125,0) [0|8031.875] "V" Vector__XXX
 SG_ HvssMxIsttsDsCtLtExtddR : 0|16@1+ (0.125,-4000) [-4000|0] "A" Vector__XXX
 SG_ HvssMxIsttsCCtLtExtddR : 16|16@1+ (0.125,-4000) [0|4031.875] "A" Vector__XXX
 SG_ HvssMnmmDshrgVltgLmt : 48|16@1+ (0.05,0) [0|3212.75] "V" Vector__XXX

BO_ 2365204478 HVESP1IS1: 8 Vector__XXX
 SG_ Hvsp1HghVltgIntrnlNgtvCnttr1Stt : 0|2@1+ (1,0) [0|3] "" Vector__XXX
 SG_ Hvsp1HghVltgIntrnlNgtvCnttr2Stt : 2|2@1+ (1,0) [0|3] "" Vector__XXX
 SG_ Hvsp1HghVltgIntrnlNgtvCnttr3Stt : 4|2@1+ (1,0) [0|3] "" Vector__XXX
 SG_ Hvsp1HghVltgIntrnlNgtvCnttr4Stt : 6|2@1+ (1,0) [0|3] "" Vector__XXX
 SG_ Hvsp1HghVltgIntrnlNgtvCnttr5Stt : 8|2@1+ (1,0) [0|3] "" Vector__XXX
 SG_ Hvsp1HghVltgIntrnlNgtvCnttr6Stt : 10|2@1+ (1,0) [0|3] "" Vector__XXX
 SG_ Hvsp1HghVltgIntrnlNgtvCnttr7Stt : 12|2@1+ (1,0) [0|3] "" Vector__XXX
 SG_ Hvsp1HghVltgIntrnlNgtvCnttr8Stt : 14|2@1+ (1,0) [0|3] "" Vector__XXX
 SG_ Hvsp1HghVltgIntrnlPstvCnttr1Stt : 16|2@1+ (1,0) [0|3] "" Vector__XXX
 SG_ Hvsp1HghVltgIntrnlPstvCnttr2Stt : 18|2@1+ (1,0) [0|3] "" Vector__XXX
 SG_ Hvsp1HghVltgIntrnlPstvCnttr3Stt : 20|2@1+ (1,0) [0|3] "" Vector__XXX
 SG_ Hvsp1HghVltgIntrnlPstvCnttr4Stt : 22|2@1+ (1,0) [0|3] "" Vector__XXX
 SG_ Hvsp1HghVltgIntrnlPstvCnttr5Stt : 24|2@1+ (1,0) [0|3] "" Vector__XXX
 SG_ Hvsp1HghVltgIntrnlPstvCnttr6Stt : 26|2@1+ (1,0) [0|3] "" Vector__XXX
 SG_ Hvsp1HghVltgIntrnlPstvCnttr7Stt : 28|2@1+ (1,0) [0|3] "" Vector__XXX
 SG_ Hvsp1HghVltgIntrnlPstvCnttr8Stt : 30|2@1+ (1,0) [0|3] "" Vector__XXX

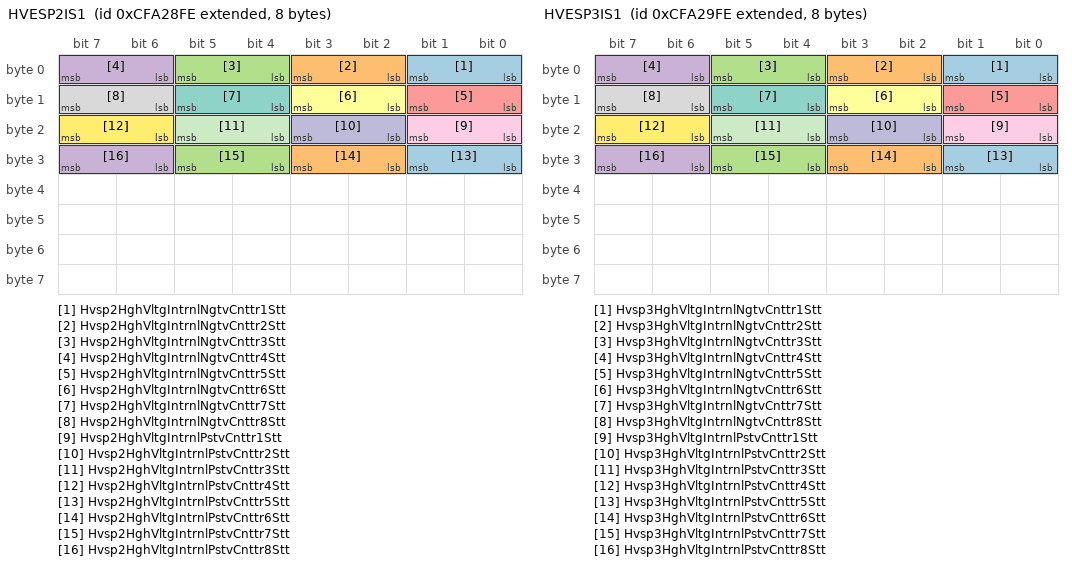
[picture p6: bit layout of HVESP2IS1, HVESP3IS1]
BO_ 2365204734 HVESP2IS1: 8 Vector__XXX
 SG_ Hvsp2HghVltgIntrnlNgtvCnttr1Stt : 0|2@1+ (1,0) [0|3] "" Vector__XXX
 SG_ Hvsp2HghVltgIntrnlNgtvCnttr2Stt : 2|2@1+ (1,0) [0|3] "" Vector__XXX
 SG_ Hvsp2HghVltgIntrnlNgtvCnttr3Stt : 4|2@1+ (1,0) [0|3] "" Vector__XXX
 SG_ Hvsp2HghVltgIntrnlNgtvCnttr4Stt : 6|2@1+ (1,0) [0|3] "" Vector__XXX
 SG_ Hvsp2HghVltgIntrnlNgtvCnttr5Stt : 8|2@1+ (1,0) [0|3] "" Vector__XXX
 SG_ Hvsp2HghVltgIntrnlNgtvCnttr6Stt : 10|2@1+ (1,0) [0|3] "" Vector__XXX
 SG_ Hvsp2HghVltgIntrnlNgtvCnttr7Stt : 12|2@1+ (1,0) [0|3] "" Vector__XXX
 SG_ Hvsp2HghVltgIntrnlNgtvCnttr8Stt : 14|2@1+ (1,0) [0|3] "" Vector__XXX
 SG_ Hvsp2HghVltgIntrnlPstvCnttr1Stt : 16|2@1+ (1,0) [0|3] "" Vector__XXX
 SG_ Hvsp2HghVltgIntrnlPstvCnttr2Stt : 18|2@1+ (1,0) [0|3] "" Vector__XXX
 SG_ Hvsp2HghVltgIntrnlPstvCnttr3Stt : 20|2@1+ (1,0) [0|3] "" Vector__XXX
 SG_ Hvsp2HghVltgIntrnlPstvCnttr4Stt : 22|2@1+ (1,0) [0|3] "" Vector__XXX
 SG_ Hvsp2HghVltgIntrnlPstvCnttr5Stt : 24|2@1+ (1,0) [0|3] "" Vector__XXX
 SG_ Hvsp2HghVltgIntrnlPstvCnttr6Stt : 26|2@1+ (1,0) [0|3] "" Vector__XXX
 SG_ Hvsp2HghVltgIntrnlPstvCnttr7Stt : 28|2@1+ (1,0) [0|3] "" Vector__XXX
 SG_ Hvsp2HghVltgIntrnlPstvCnttr8Stt : 30|2@1+ (1,0) [0|3] "" Vector__XXX

BO_ 2365204990 HVESP3IS1: 8 Vector__XXX
 SG_ Hvsp3HghVltgIntrnlNgtvCnttr1Stt : 0|2@1+ (1,0) [0|3] "" Vector__XXX
 SG_ Hvsp3HghVltgIntrnlNgtvCnttr2Stt : 2|2@1+ (1,0) [0|3] "" Vector__XXX
 SG_ Hvsp3HghVltgIntrnlNgtvCnttr3Stt : 4|2@1+ (1,0) [0|3] "" Vector__XXX
 SG_ Hvsp3HghVltgIntrnlNgtvCnttr4Stt : 6|2@1+ (1,0) [0|3] "" Vector__XXX
 SG_ Hvsp3HghVltgIntrnlNgtvCnttr5Stt : 8|2@1+ (1,0) [0|3] "" Vector__XXX
 SG_ Hvsp3HghVltgIntrnlNgtvCnttr6Stt : 10|2@1+ (1,0) [0|3] "" Vector__XXX
 SG_ Hvsp3HghVltgIntrnlNgtvCnttr7Stt : 12|2@1+ (1,0) [0|3] "" Vector__XXX
 SG_ Hvsp3HghVltgIntrnlNgtvCnttr8Stt : 14|2@1+ (1,0) [0|3] "" Vector__XXX
 SG_ Hvsp3HghVltgIntrnlPstvCnttr1Stt : 16|2@1+ (1,0) [0|3] "" Vector__XXX
 SG_ Hvsp3HghVltgIntrnlPstvCnttr2Stt : 18|2@1+ (1,0) [0|3] "" Vector__XXX
 SG_ Hvsp3HghVltgIntrnlPstvCnttr3Stt : 20|2@1+ (1,0) [0|3] "" Vector__XXX
 SG_ Hvsp3HghVltgIntrnlPstvCnttr4Stt : 22|2@1+ (1,0) [0|3] "" Vector__XXX
 SG_ Hvsp3HghVltgIntrnlPstvCnttr5Stt : 24|2@1+ (1,0) [0|3] "" Vector__XXX
 SG_ Hvsp3HghVltgIntrnlPstvCnttr6Stt : 26|2@1+ (1,0) [0|3] "" Vector__XXX
 SG_ Hvsp3HghVltgIntrnlPstvCnttr7Stt : 28|2@1+ (1,0) [0|3] "" Vector__XXX
 SG_ Hvsp3HghVltgIntrnlPstvCnttr8Stt : 30|2@1+ (1,0) [0|3] "" Vector__XXX

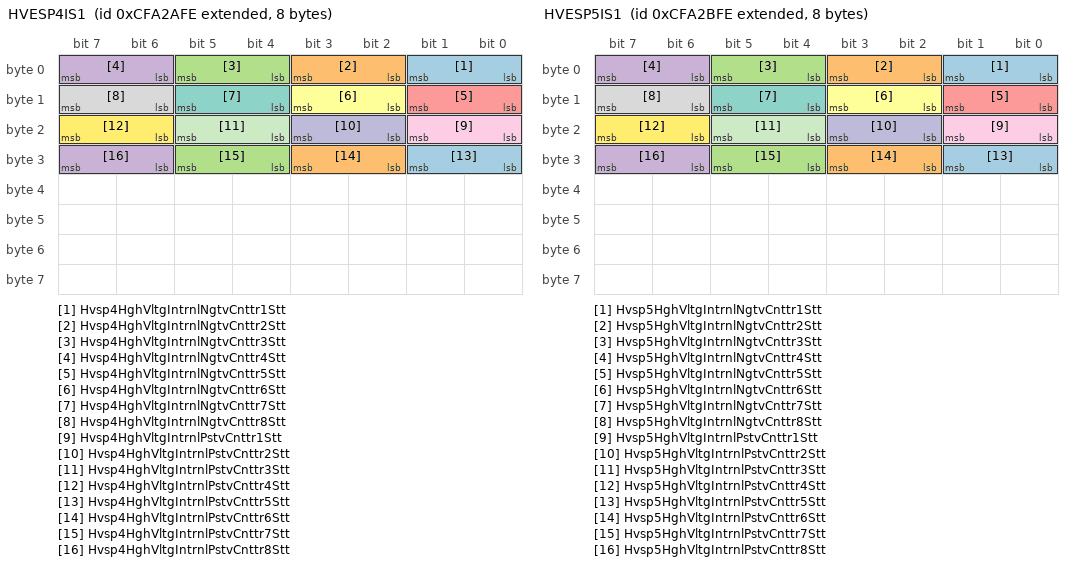
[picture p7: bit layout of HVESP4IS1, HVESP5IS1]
BO_ 2365205246 HVESP4IS1: 8 Vector__XXX
 SG_ Hvsp4HghVltgIntrnlNgtvCnttr1Stt : 0|2@1+ (1,0) [0|3] "" Vector__XXX
 SG_ Hvsp4HghVltgIntrnlNgtvCnttr2Stt : 2|2@1+ (1,0) [0|3] "" Vector__XXX
 SG_ Hvsp4HghVltgIntrnlNgtvCnttr3Stt : 4|2@1+ (1,0) [0|3] "" Vector__XXX
 SG_ Hvsp4HghVltgIntrnlNgtvCnttr4Stt : 6|2@1+ (1,0) [0|3] "" Vector__XXX
 SG_ Hvsp4HghVltgIntrnlNgtvCnttr5Stt : 8|2@1+ (1,0) [0|3] "" Vector__XXX
 SG_ Hvsp4HghVltgIntrnlNgtvCnttr6Stt : 10|2@1+ (1,0) [0|3] "" Vector__XXX
 SG_ Hvsp4HghVltgIntrnlNgtvCnttr7Stt : 12|2@1+ (1,0) [0|3] "" Vector__XXX
 SG_ Hvsp4HghVltgIntrnlNgtvCnttr8Stt : 14|2@1+ (1,0) [0|3] "" Vector__XXX
 SG_ Hvsp4HghVltgIntrnlPstvCnttr1Stt : 16|2@1+ (1,0) [0|3] "" Vector__XXX
 SG_ Hvsp4HghVltgIntrnlPstvCnttr2Stt : 18|2@1+ (1,0) [0|3] "" Vector__XXX
 SG_ Hvsp4HghVltgIntrnlPstvCnttr3Stt : 20|2@1+ (1,0) [0|3] "" Vector__XXX
 SG_ Hvsp4HghVltgIntrnlPstvCnttr4Stt : 22|2@1+ (1,0) [0|3] "" Vector__XXX
 SG_ Hvsp4HghVltgIntrnlPstvCnttr5Stt : 24|2@1+ (1,0) [0|3] "" Vector__XXX
 SG_ Hvsp4HghVltgIntrnlPstvCnttr6Stt : 26|2@1+ (1,0) [0|3] "" Vector__XXX
 SG_ Hvsp4HghVltgIntrnlPstvCnttr7Stt : 28|2@1+ (1,0) [0|3] "" Vector__XXX
 SG_ Hvsp4HghVltgIntrnlPstvCnttr8Stt : 30|2@1+ (1,0) [0|3] "" Vector__XXX

BO_ 2365205502 HVESP5IS1: 8 Vector__XXX
 SG_ Hvsp5HghVltgIntrnlNgtvCnttr1Stt : 0|2@1+ (1,0) [0|3] "" Vector__XXX
 SG_ Hvsp5HghVltgIntrnlNgtvCnttr2Stt : 2|2@1+ (1,0) [0|3] "" Vector__XXX
 SG_ Hvsp5HghVltgIntrnlNgtvCnttr3Stt : 4|2@1+ (1,0) [0|3] "" Vector__XXX
 SG_ Hvsp5HghVltgIntrnlNgtvCnttr4Stt : 6|2@1+ (1,0) [0|3] "" Vector__XXX
 SG_ Hvsp5HghVltgIntrnlNgtvCnttr5Stt : 8|2@1+ (1,0) [0|3] "" Vector__XXX
 SG_ Hvsp5HghVltgIntrnlNgtvCnttr6Stt : 10|2@1+ (1,0) [0|3] "" Vector__XXX
 SG_ Hvsp5HghVltgIntrnlNgtvCnttr7Stt : 12|2@1+ (1,0) [0|3] "" Vector__XXX
 SG_ Hvsp5HghVltgIntrnlNgtvCnttr8Stt : 14|2@1+ (1,0) [0|3] "" Vector__XXX
 SG_ Hvsp5HghVltgIntrnlPstvCnttr1Stt : 16|2@1+ (1,0) [0|3] "" Vector__XXX
 SG_ Hvsp5HghVltgIntrnlPstvCnttr2Stt : 18|2@1+ (1,0) [0|3] "" Vector__XXX
 SG_ Hvsp5HghVltgIntrnlPstvCnttr3Stt : 20|2@1+ (1,0) [0|3] "" Vector__XXX
 SG_ Hvsp5HghVltgIntrnlPstvCnttr4Stt : 22|2@1+ (1,0) [0|3] "" Vector__XXX
 SG_ Hvsp5HghVltgIntrnlPstvCnttr5Stt : 24|2@1+ (1,0) [0|3] "" Vector__XXX
 SG_ Hvsp5HghVltgIntrnlPstvCnttr6Stt : 26|2@1+ (1,0) [0|3] "" Vector__XXX
 SG_ Hvsp5HghVltgIntrnlPstvCnttr7Stt : 28|2@1+ (1,0) [0|3] "" Vector__XXX
 SG_ Hvsp5HghVltgIntrnlPstvCnttr8Stt : 30|2@1+ (1,0) [0|3] "" Vector__XXX

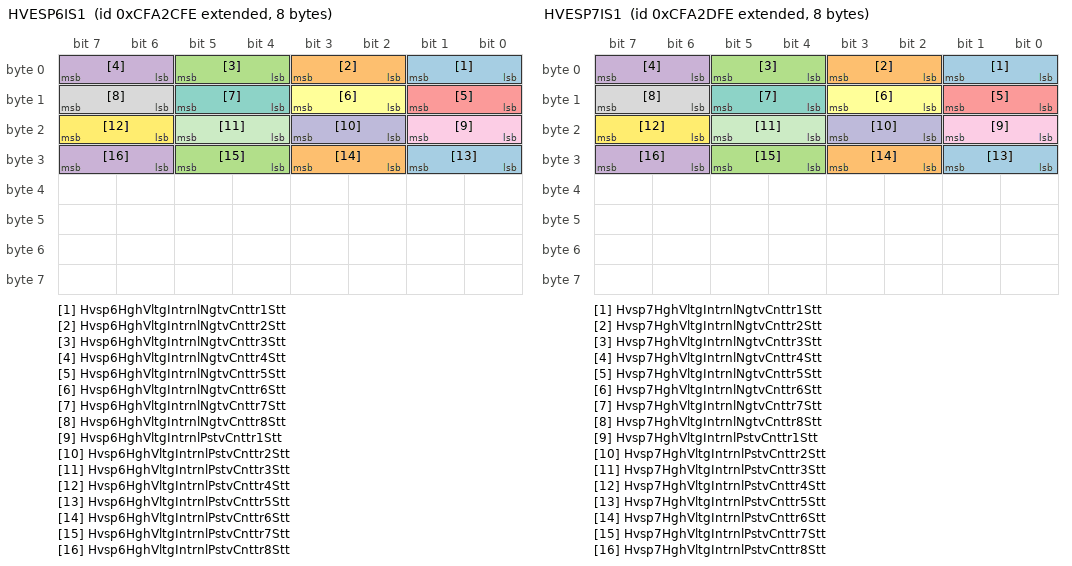
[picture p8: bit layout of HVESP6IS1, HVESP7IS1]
BO_ 2365205758 HVESP6IS1: 8 Vector__XXX
 SG_ Hvsp6HghVltgIntrnlNgtvCnttr1Stt : 0|2@1+ (1,0) [0|3] "" Vector__XXX
 SG_ Hvsp6HghVltgIntrnlNgtvCnttr2Stt : 2|2@1+ (1,0) [0|3] "" Vector__XXX
 SG_ Hvsp6HghVltgIntrnlNgtvCnttr3Stt : 4|2@1+ (1,0) [0|3] "" Vector__XXX
 SG_ Hvsp6HghVltgIntrnlNgtvCnttr4Stt : 6|2@1+ (1,0) [0|3] "" Vector__XXX
 SG_ Hvsp6HghVltgIntrnlNgtvCnttr5Stt : 8|2@1+ (1,0) [0|3] "" Vector__XXX
 SG_ Hvsp6HghVltgIntrnlNgtvCnttr6Stt : 10|2@1+ (1,0) [0|3] "" Vector__XXX
 SG_ Hvsp6HghVltgIntrnlNgtvCnttr7Stt : 12|2@1+ (1,0) [0|3] "" Vector__XXX
 SG_ Hvsp6HghVltgIntrnlNgtvCnttr8Stt : 14|2@1+ (1,0) [0|3] "" Vector__XXX
 SG_ Hvsp6HghVltgIntrnlPstvCnttr1Stt : 16|2@1+ (1,0) [0|3] "" Vector__XXX
 SG_ Hvsp6HghVltgIntrnlPstvCnttr2Stt : 18|2@1+ (1,0) [0|3] "" Vector__XXX
 SG_ Hvsp6HghVltgIntrnlPstvCnttr3Stt : 20|2@1+ (1,0) [0|3] "" Vector__XXX
 SG_ Hvsp6HghVltgIntrnlPstvCnttr4Stt : 22|2@1+ (1,0) [0|3] "" Vector__XXX
 SG_ Hvsp6HghVltgIntrnlPstvCnttr5Stt : 24|2@1+ (1,0) [0|3] "" Vector__XXX
 SG_ Hvsp6HghVltgIntrnlPstvCnttr6Stt : 26|2@1+ (1,0) [0|3] "" Vector__XXX
 SG_ Hvsp6HghVltgIntrnlPstvCnttr7Stt : 28|2@1+ (1,0) [0|3] "" Vector__XXX
 SG_ Hvsp6HghVltgIntrnlPstvCnttr8Stt : 30|2@1+ (1,0) [0|3] "" Vector__XXX

BO_ 2365206014 HVESP7IS1: 8 Vector__XXX
 SG_ Hvsp7HghVltgIntrnlNgtvCnttr1Stt : 0|2@1+ (1,0) [0|3] "" Vector__XXX
 SG_ Hvsp7HghVltgIntrnlNgtvCnttr2Stt : 2|2@1+ (1,0) [0|3] "" Vector__XXX
 SG_ Hvsp7HghVltgIntrnlNgtvCnttr3Stt : 4|2@1+ (1,0) [0|3] "" Vector__XXX
 SG_ Hvsp7HghVltgIntrnlNgtvCnttr4Stt : 6|2@1+ (1,0) [0|3] "" Vector__XXX
 SG_ Hvsp7HghVltgIntrnlNgtvCnttr5Stt : 8|2@1+ (1,0) [0|3] "" Vector__XXX
 SG_ Hvsp7HghVltgIntrnlNgtvCnttr6Stt : 10|2@1+ (1,0) [0|3] "" Vector__XXX
 SG_ Hvsp7HghVltgIntrnlNgtvCnttr7Stt : 12|2@1+ (1,0) [0|3] "" Vector__XXX
 SG_ Hvsp7HghVltgIntrnlNgtvCnttr8Stt : 14|2@1+ (1,0) [0|3] "" Vector__XXX
 SG_ Hvsp7HghVltgIntrnlPstvCnttr1Stt : 16|2@1+ (1,0) [0|3] "" Vector__XXX
 SG_ Hvsp7HghVltgIntrnlPstvCnttr2Stt : 18|2@1+ (1,0) [0|3] "" Vector__XXX
 SG_ Hvsp7HghVltgIntrnlPstvCnttr3Stt : 20|2@1+ (1,0) [0|3] "" Vector__XXX
 SG_ Hvsp7HghVltgIntrnlPstvCnttr4Stt : 22|2@1+ (1,0) [0|3] "" Vector__XXX
 SG_ Hvsp7HghVltgIntrnlPstvCnttr5Stt : 24|2@1+ (1,0) [0|3] "" Vector__XXX
 SG_ Hvsp7HghVltgIntrnlPstvCnttr6Stt : 26|2@1+ (1,0) [0|3] "" Vector__XXX
 SG_ Hvsp7HghVltgIntrnlPstvCnttr7Stt : 28|2@1+ (1,0) [0|3] "" Vector__XXX
 SG_ Hvsp7HghVltgIntrnlPstvCnttr8Stt : 30|2@1+ (1,0) [0|3] "" Vector__XXX

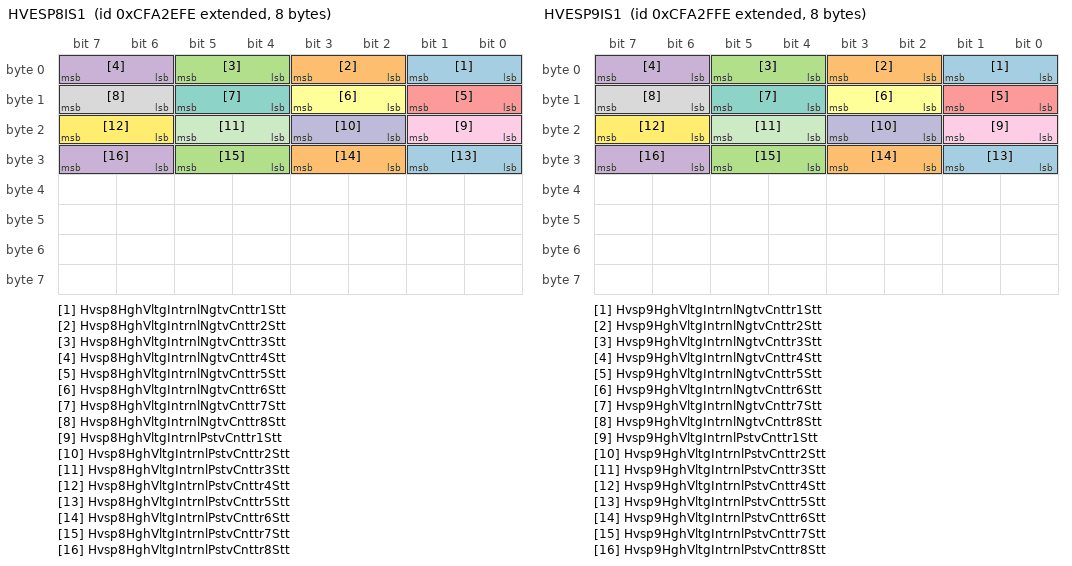
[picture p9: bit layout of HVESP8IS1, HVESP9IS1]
BO_ 2365206270 HVESP8IS1: 8 Vector__XXX
 SG_ Hvsp8HghVltgIntrnlNgtvCnttr1Stt : 0|2@1+ (1,0) [0|3] "" Vector__XXX
 SG_ Hvsp8HghVltgIntrnlNgtvCnttr2Stt : 2|2@1+ (1,0) [0|3] "" Vector__XXX
 SG_ Hvsp8HghVltgIntrnlNgtvCnttr3Stt : 4|2@1+ (1,0) [0|3] "" Vector__XXX
 SG_ Hvsp8HghVltgIntrnlNgtvCnttr4Stt : 6|2@1+ (1,0) [0|3] "" Vector__XXX
 SG_ Hvsp8HghVltgIntrnlNgtvCnttr5Stt : 8|2@1+ (1,0) [0|3] "" Vector__XXX
 SG_ Hvsp8HghVltgIntrnlNgtvCnttr6Stt : 10|2@1+ (1,0) [0|3] "" Vector__XXX
 SG_ Hvsp8HghVltgIntrnlNgtvCnttr7Stt : 12|2@1+ (1,0) [0|3] "" Vector__XXX
 SG_ Hvsp8HghVltgIntrnlNgtvCnttr8Stt : 14|2@1+ (1,0) [0|3] "" Vector__XXX
 SG_ Hvsp8HghVltgIntrnlPstvCnttr1Stt : 16|2@1+ (1,0) [0|3] "" Vector__XXX
 SG_ Hvsp8HghVltgIntrnlPstvCnttr2Stt : 18|2@1+ (1,0) [0|3] "" Vector__XXX
 SG_ Hvsp8HghVltgIntrnlPstvCnttr3Stt : 20|2@1+ (1,0) [0|3] "" Vector__XXX
 SG_ Hvsp8HghVltgIntrnlPstvCnttr4Stt : 22|2@1+ (1,0) [0|3] "" Vector__XXX
 SG_ Hvsp8HghVltgIntrnlPstvCnttr5Stt : 24|2@1+ (1,0) [0|3] "" Vector__XXX
 SG_ Hvsp8HghVltgIntrnlPstvCnttr6Stt : 26|2@1+ (1,0) [0|3] "" Vector__XXX
 SG_ Hvsp8HghVltgIntrnlPstvCnttr7Stt : 28|2@1+ (1,0) [0|3] "" Vector__XXX
 SG_ Hvsp8HghVltgIntrnlPstvCnttr8Stt : 30|2@1+ (1,0) [0|3] "" Vector__XXX

BO_ 2365206526 HVESP9IS1: 8 Vector__XXX
 SG_ Hvsp9HghVltgIntrnlNgtvCnttr1Stt : 0|2@1+ (1,0) [0|3] "" Vector__XXX
 SG_ Hvsp9HghVltgIntrnlNgtvCnttr2Stt : 2|2@1+ (1,0) [0|3] "" Vector__XXX
 SG_ Hvsp9HghVltgIntrnlNgtvCnttr3Stt : 4|2@1+ (1,0) [0|3] "" Vector__XXX
 SG_ Hvsp9HghVltgIntrnlNgtvCnttr4Stt : 6|2@1+ (1,0) [0|3] "" Vector__XXX
 SG_ Hvsp9HghVltgIntrnlNgtvCnttr5Stt : 8|2@1+ (1,0) [0|3] "" Vector__XXX
 SG_ Hvsp9HghVltgIntrnlNgtvCnttr6Stt : 10|2@1+ (1,0) [0|3] "" Vector__XXX
 SG_ Hvsp9HghVltgIntrnlNgtvCnttr7Stt : 12|2@1+ (1,0) [0|3] "" Vector__XXX
 SG_ Hvsp9HghVltgIntrnlNgtvCnttr8Stt : 14|2@1+ (1,0) [0|3] "" Vector__XXX
 SG_ Hvsp9HghVltgIntrnlPstvCnttr1Stt : 16|2@1+ (1,0) [0|3] "" Vector__XXX
 SG_ Hvsp9HghVltgIntrnlPstvCnttr2Stt : 18|2@1+ (1,0) [0|3] "" Vector__XXX
 SG_ Hvsp9HghVltgIntrnlPstvCnttr3Stt : 20|2@1+ (1,0) [0|3] "" Vector__XXX
 SG_ Hvsp9HghVltgIntrnlPstvCnttr4Stt : 22|2@1+ (1,0) [0|3] "" Vector__XXX
 SG_ Hvsp9HghVltgIntrnlPstvCnttr5Stt : 24|2@1+ (1,0) [0|3] "" Vector__XXX
 SG_ Hvsp9HghVltgIntrnlPstvCnttr6Stt : 26|2@1+ (1,0) [0|3] "" Vector__XXX
 SG_ Hvsp9HghVltgIntrnlPstvCnttr7Stt : 28|2@1+ (1,0) [0|3] "" Vector__XXX
 SG_ Hvsp9HghVltgIntrnlPstvCnttr8Stt : 30|2@1+ (1,0) [0|3] "" Vector__XXX

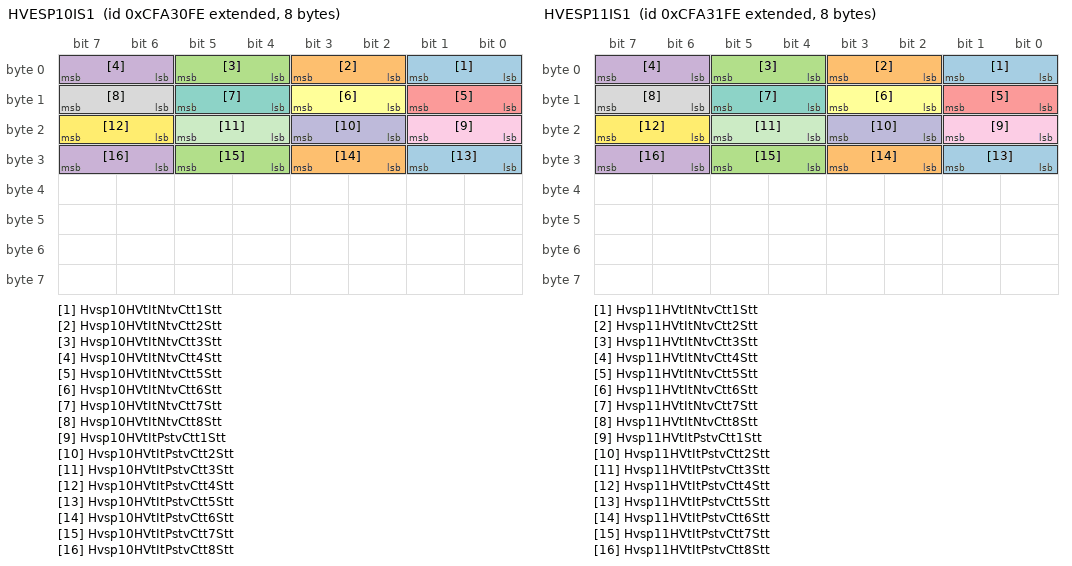
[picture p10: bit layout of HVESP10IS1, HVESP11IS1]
BO_ 2365206782 HVESP10IS1: 8 Vector__XXX
 SG_ Hvsp10HVtItNtvCtt1Stt : 0|2@1+ (1,0) [0|3] "" Vector__XXX
 SG_ Hvsp10HVtItNtvCtt2Stt : 2|2@1+ (1,0) [0|3] "" Vector__XXX
 SG_ Hvsp10HVtItNtvCtt3Stt : 4|2@1+ (1,0) [0|3] "" Vector__XXX
 SG_ Hvsp10HVtItNtvCtt4Stt : 6|2@1+ (1,0) [0|3] "" Vector__XXX
 SG_ Hvsp10HVtItNtvCtt5Stt : 8|2@1+ (1,0) [0|3] "" Vector__XXX
 SG_ Hvsp10HVtItNtvCtt6Stt : 10|2@1+ (1,0) [0|3] "" Vector__XXX
 SG_ Hvsp10HVtItNtvCtt7Stt : 12|2@1+ (1,0) [0|3] "" Vector__XXX
 SG_ Hvsp10HVtItNtvCtt8Stt : 14|2@1+ (1,0) [0|3] "" Vector__XXX
 SG_ Hvsp10HVtItPstvCtt1Stt : 16|2@1+ (1,0) [0|3] "" Vector__XXX
 SG_ Hvsp10HVtItPstvCtt2Stt : 18|2@1+ (1,0) [0|3] "" Vector__XXX
 SG_ Hvsp10HVtItPstvCtt3Stt : 20|2@1+ (1,0) [0|3] "" Vector__XXX
 SG_ Hvsp10HVtItPstvCtt4Stt : 22|2@1+ (1,0) [0|3] "" Vector__XXX
 SG_ Hvsp10HVtItPstvCtt5Stt : 24|2@1+ (1,0) [0|3] "" Vector__XXX
 SG_ Hvsp10HVtItPstvCtt6Stt : 26|2@1+ (1,0) [0|3] "" Vector__XXX
 SG_ Hvsp10HVtItPstvCtt7Stt : 28|2@1+ (1,0) [0|3] "" Vector__XXX
 SG_ Hvsp10HVtItPstvCtt8Stt : 30|2@1+ (1,0) [0|3] "" Vector__XXX

BO_ 2365207038 HVESP11IS1: 8 Vector__XXX
 SG_ Hvsp11HVtItNtvCtt1Stt : 0|2@1+ (1,0) [0|3] "" Vector__XXX
 SG_ Hvsp11HVtItNtvCtt2Stt : 2|2@1+ (1,0) [0|3] "" Vector__XXX
 SG_ Hvsp11HVtItNtvCtt3Stt : 4|2@1+ (1,0) [0|3] "" Vector__XXX
 SG_ Hvsp11HVtItNtvCtt4Stt : 6|2@1+ (1,0) [0|3] "" Vector__XXX
 SG_ Hvsp11HVtItNtvCtt5Stt : 8|2@1+ (1,0) [0|3] "" Vector__XXX
 SG_ Hvsp11HVtItNtvCtt6Stt : 10|2@1+ (1,0) [0|3] "" Vector__XXX
 SG_ Hvsp11HVtItNtvCtt7Stt : 12|2@1+ (1,0) [0|3] "" Vector__XXX
 SG_ Hvsp11HVtItNtvCtt8Stt : 14|2@1+ (1,0) [0|3] "" Vector__XXX
 SG_ Hvsp11HVtItPstvCtt1Stt : 16|2@1+ (1,0) [0|3] "" Vector__XXX
 SG_ Hvsp11HVtItPstvCtt2Stt : 18|2@1+ (1,0) [0|3] "" Vector__XXX
 SG_ Hvsp11HVtItPstvCtt3Stt : 20|2@1+ (1,0) [0|3] "" Vector__XXX
 SG_ Hvsp11HVtItPstvCtt4Stt : 22|2@1+ (1,0) [0|3] "" Vector__XXX
 SG_ Hvsp11HVtItPstvCtt5Stt : 24|2@1+ (1,0) [0|3] "" Vector__XXX
 SG_ Hvsp11HVtItPstvCtt6Stt : 26|2@1+ (1,0) [0|3] "" Vector__XXX
 SG_ Hvsp11HVtItPstvCtt7Stt : 28|2@1+ (1,0) [0|3] "" Vector__XXX
 SG_ Hvsp11HVtItPstvCtt8Stt : 30|2@1+ (1,0) [0|3] "" Vector__XXX

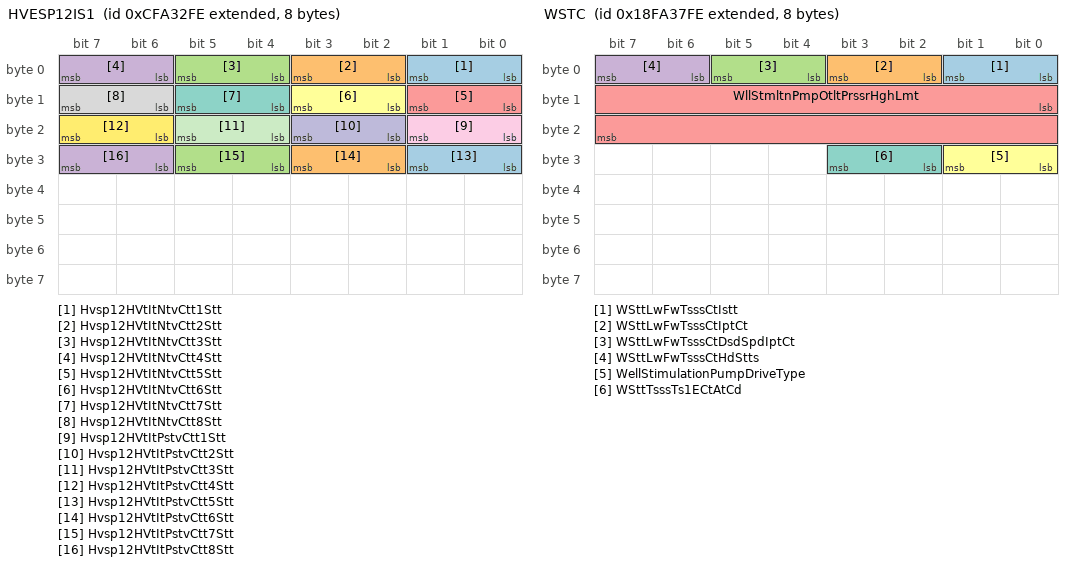
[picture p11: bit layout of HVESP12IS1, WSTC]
BO_ 2365207294 HVESP12IS1: 8 Vector__XXX
 SG_ Hvsp12HVtItNtvCtt1Stt : 0|2@1+ (1,0) [0|3] "" Vector__XXX
 SG_ Hvsp12HVtItNtvCtt2Stt : 2|2@1+ (1,0) [0|3] "" Vector__XXX
 SG_ Hvsp12HVtItNtvCtt3Stt : 4|2@1+ (1,0) [0|3] "" Vector__XXX
 SG_ Hvsp12HVtItNtvCtt4Stt : 6|2@1+ (1,0) [0|3] "" Vector__XXX
 SG_ Hvsp12HVtItNtvCtt5Stt : 8|2@1+ (1,0) [0|3] "" Vector__XXX
 SG_ Hvsp12HVtItNtvCtt6Stt : 10|2@1+ (1,0) [0|3] "" Vector__XXX
 SG_ Hvsp12HVtItNtvCtt7Stt : 12|2@1+ (1,0) [0|3] "" Vector__XXX
 SG_ Hvsp12HVtItNtvCtt8Stt : 14|2@1+ (1,0) [0|3] "" Vector__XXX
 SG_ Hvsp12HVtItPstvCtt1Stt : 16|2@1+ (1,0) [0|3] "" Vector__XXX
 SG_ Hvsp12HVtItPstvCtt2Stt : 18|2@1+ (1,0) [0|3] "" Vector__XXX
 SG_ Hvsp12HVtItPstvCtt3Stt : 20|2@1+ (1,0) [0|3] "" Vector__XXX
 SG_ Hvsp12HVtItPstvCtt4Stt : 22|2@1+ (1,0) [0|3] "" Vector__XXX
 SG_ Hvsp12HVtItPstvCtt5Stt : 24|2@1+ (1,0) [0|3] "" Vector__XXX
 SG_ Hvsp12HVtItPstvCtt6Stt : 26|2@1+ (1,0) [0|3] "" Vector__XXX
 SG_ Hvsp12HVtItPstvCtt7Stt : 28|2@1+ (1,0) [0|3] "" Vector__XXX
 SG_ Hvsp12HVtItPstvCtt8Stt : 30|2@1+ (1,0) [0|3] "" Vector__XXX

BO_ 2499425790 RTBI: 8 Vector__XXX
 SG_ RefuseTransitStatus : 0|2@1+ (1,0) [0|3] "" Vector__XXX
 SG_ RefuseFrontLoaderArmPosition : 2|4@1+ (1,0) [0|15] "" Vector__XXX
 SG_ RefuseFrontLoaderForkPosition : 6|2@1+ (1,0) [0|3] "" Vector__XXX
 SG_ RefuseTailgatePosition : 8|2@1+ (1,0) [0|3] "" Vector__XXX
 SG_ RefuseOverheightOverwidthStatus : 10|2@1+ (1,0) [0|3] "" Vector__XXX

BO_ 2566534910 EFLP14: 8 Vector__XXX
 SG_ EngnThrttlVlv1OtltPrssr : 0|16@1+ (0.1,0) [0|6425.5] "kPa" Vector__XXX
 SG_ EngnThrttlVlv1OtltAsltPrssr : 16|16@1+ (0.1,0) [0|6425.5] "kPa" Vector__XXX
 SG_ EngnThrttlVlv2OtltPrssr : 32|16@1+ (0.1,0) [0|6425.5] "kPa" Vector__XXX
 SG_ EngnThrttlVlv2OtltAsltPrssr : 48|16@1+ (0.1,0) [0|6425.5] "kPa" Vector__XXX

BO_ 2566535166 WSTC: 8 Vector__XXX
 SG_ WSttLwFwTsssCtIstt : 0|2@1+ (1,0) [0|3] "" Vector__XXX
 SG_ WSttLwFwTsssCtIptCt : 2|2@1+ (1,0) [0|3] "" Vector__XXX
 SG_ WSttLwFwTsssCtDsdSpdIptCt : 4|2@1+ (1,0) [0|3] "" Vector__XXX
 SG_ WSttLwFwTsssCtHdStts : 6|2@1+ (1,0) [0|3] "" Vector__XXX
 SG_ WllStmltnPmpOtltPrssrHghLmt : 8|16@1+ (5,0) [0|321275] "kPa" Vector__XXX
 SG_ WellStimulationPumpDriveType : 24|2@1+ (1,0) [0|3] "" Vector__XXX
 SG_ WSttTsssTs1ECtAtCd : 26|2@1+ (1,0) [0|3] "" Vector__XXX

BO_ 2566535422 WSPPS1: 8 Vector__XXX
 SG_ WllStmltnPmpOtltPrssrLvl1Prnt : 0|8@1+ (0.5,0) [0|125] "%" Vector__XXX
 SG_ WllStmltnPmpOtltPrssrLvl2Prnt : 8|8@1+ (0.5,0) [0|125] "%" Vector__XXX
 SG_ WllStmltnPmpOtltPrssrLvl3Prnt : 16|8@1+ (0.5,0) [0|125] "%" Vector__XXX
 SG_ WllStmltnPmpOtltPrssrLvl4Prnt : 24|8@1+ (0.5,0) [0|125] "%" Vector__XXX
 SG_ WllStmltnPmpOtltPrssrLvl5Prnt : 32|8@1+ (0.5,0) [0|125] "%" Vector__XXX
 SG_ WllStmltnPdOprtngPrssrUpprLmt : 40|16@1+ (5,0) [0|321275] "kPa" Vector__XXX
 SG_ WSttPpOttPssDFAv : 56|2@1+ (1,0) [0|3] "" Vector__XXX
 SG_ WllStmltnSstmCntrllrEnlStts : 58|2@1+ (1,0) [0|3] "" Vector__XXX

BO_ 2566535678 WSPPS2: 8 Vector__XXX
 SG_ WllStmltnDshrgPrssrRspnsLvl1Ftr : 0|8@1+ (0.5,0) [0|125] "%" Vector__XXX
 SG_ WllStmltnDshrgPrssrRspnsLvl2Ftr : 8|8@1+ (0.5,0) [0|125] "%" Vector__XXX
 SG_ WllStmltnDshrgPrssrRspnsLvl3Ftr : 16|8@1+ (0.5,0) [0|125] "%" Vector__XXX
 SG_ WllStmltnDshrgPrssrRspnsLvl4Ftr : 24|8@1+ (0.5,0) [0|125] "%" Vector__XXX
 SG_ WllStmltnDshrgPrssrRspnsLvl5Ftr : 32|8@1+ (0.5,0) [0|125] "%" Vector__XXX
 SG_ WllStmltnIntlRmpGnFtr : 40|8@1+ (0.5,0) [0|125] "%" Vector__XXX
 SG_ WSttOttPssPttLvAtvStts : 48|4@1+ (1,0) [0|15] "" Vector__XXX

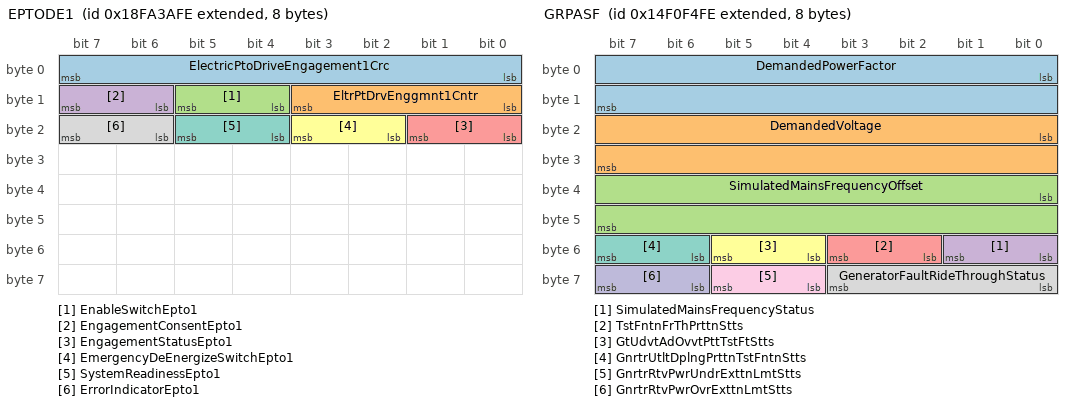
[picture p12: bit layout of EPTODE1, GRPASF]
BO_ 2566535934 EPTODE1: 8 Vector__XXX
 SG_ ElectricPtoDriveEngagement1Crc : 0|8@1+ (1,0) [0|250] "count" Vector__XXX
 SG_ EltrPtDrvEnggmnt1Cntr : 8|4@1+ (1,0) [0|15] "" Vector__XXX
 SG_ EnableSwitchEpto1 : 12|2@1+ (1,0) [0|3] "" Vector__XXX
 SG_ EngagementConsentEpto1 : 14|2@1+ (1,0) [0|3] "" Vector__XXX
 SG_ EngagementStatusEpto1 : 16|2@1+ (1,0) [0|3] "" Vector__XXX
 SG_ EmergencyDeEnergizeSwitchEpto1 : 18|2@1+ (1,0) [0|3] "" Vector__XXX
 SG_ SystemReadinessEpto1 : 20|2@1+ (1,0) [0|3] "" Vector__XXX
 SG_ ErrorIndicatorEpto1 : 22|2@1+ (1,0) [0|3] "" Vector__XXX

BO_ 2566536190 EPTO1I: 8 Vector__XXX
 SG_ Epto1CurrentLimit : 0|16@1+ (0.05,0) [0|3212.75] "A" Vector__XXX
 SG_ Epto1Current : 16|16@1+ (0.05,0) [0|3212.75] "A" Vector__XXX
 SG_ Epto1Voltage : 32|16@1+ (0.05,0) [0|3212.75] "V" Vector__XXX

BO_ 2566536446 E02SI: 8 Vector__XXX
 SG_ EngnExhstO2Snsr1ArFlEqvlnRt : 0|16@1+ (0.0000305,0) [0|1.9597775] "" Vector__XXX
 SG_ EngineExhaustO2Sensor1Voltage : 16|8@1+ (0.01,0) [0|2.5] "V" Vector__XXX
 SG_ EngnExhstO2Snsr2ArFlEqvlnRt : 24|16@1+ (0.0000305,0) [0|1.9597775] "" Vector__XXX
 SG_ EngineExhaustO2Sensor2Voltage : 40|8@1+ (0.01,0) [0|2.5] "V" Vector__XXX

BO_ 2566536702 GFSP3: 8 Vector__XXX
 SG_ EngnGssFl2SpplPrssr1 : 0|16@1+ (0.5,0) [0|32127.5] "kPa" Vector__XXX
 SG_ EGssF1SppPssRtOttPss : 16|16@1+ (1,0) [0|64255] "kPa" Vector__XXX
 SG_ EGssF2SppPssRtOttPss : 32|16@1+ (1,0) [0|64255] "kPa" Vector__XXX
 SG_ EngnGssFl1SpplPrssrRgltrPstn : 48|8@1+ (0.4,0) [0|100] "%" Vector__XXX
 SG_ EngnGssFl2SpplPrssrRgltrPstn : 56|8@1+ (0.4,0) [0|100] "%" Vector__XXX

BO_ 2499428094 TS: 8 Vector__XXX
 SG_ TrafficSignSpeedLimit : 0|16@1+ (0.00390625,0) [0|250.99609375] "km/h" Vector__XXX

BO_ 2566537214 EC4: 8 Vector__XXX
 SG_ EngnClngFnClntAtvtnTmprtr : 0|16@1+ (0.03125,-273) [-273|1734.96875] "degC" Vector__XXX
 SG_ EngnClngFnIntkMnfldAtvtnTmprtr : 16|16@1+ (0.03125,-273) [-273|1734.96875] "degC" Vector__XXX

BO_ 2633768190 RCI1: 8 Vector__XXX
 SG_ RefrigeratedCompartmentPosition : 0|16@1+ (1,0) [0|64255] "count" Vector__XXX
 SG_ RefrigeratedCompartmentId : 16|24@1+ (1,0) [0|16449535] "count" Vector__XXX
 SG_ RefrigeratedCompartmentHumidity : 40|8@1+ (0.4,0) [0|100] "%" Vector__XXX
 SG_ RfrgrtdCmprtmntTmprtr : 48|16@1+ (0.03125,-273) [-273|1734.96875] "degC" Vector__XXX

BO_ 2633768446 RCI2: 8 Vector__XXX
 SG_ TransportationCompartmentDoorId : 0|8@1+ (1,0) [0|250] "count" Vector__XXX
 SG_ TrnsprttnCmprtmntDrStts : 8|2@1+ (1,0) [0|3] "" Vector__XXX

BO_ 2352611070 XAR: 8 Vector__XXX
 SG_ ExtrnlAAlrtnRqstCr : 0|16@1+ (1,0) [0|64255] "count" Vector__XXX
 SG_ ExtrnlAAlrtnRqstCntr : 16|8@1+ (1,0) [0|250] "count" Vector__XXX
 SG_ ExternalAccAccelerationRequest : 24|16@1+ (0.00048828125,-15.6865234375) [-15.6865234375|15.68798828125] "m/(s*s)" Vector__XXX
 SG_ ExtrnlAAlrtnRqstCntrlMd : 40|2@1+ (1,0) [0|3] "" Vector__XXX
 SG_ InMessageIntegrityDataSupported : 42|2@1+ (1,0) [0|3] "" Vector__XXX

BO_ 2554003198 BCH1C1: 8 Vector__XXX
 SG_ ChargerCommandCrc : 0|8@1+ (1,0) [0|250] "count" Vector__XXX
 SG_ ChargerCommandSequenceCounter : 8|4@1+ (1,0) [0|15] "" Vector__XXX
 SG_ ChargerCommandTargetVoltage : 16|16@1+ (0.05,0) [0|3212.75] "V" Vector__XXX
 SG_ ChargerCommandTargetCurrent : 32|16@1+ (0.0625,0) [0|4015.9375] "A" Vector__XXX

BO_ 2554068734 BCH2C1: 8 Vector__XXX
 SG_ AuxChargerCommandCrc : 0|8@1+ (1,0) [0|250] "count" Vector__XXX
 SG_ AxChrgrCmmndSqnCntr : 8|4@1+ (1,0) [0|15] "" Vector__XXX
 SG_ AuxChargerCommandTargetVoltage : 16|16@1+ (0.05,0) [0|3212.75] "V" Vector__XXX
 SG_ AuxChargerCommandTargetCurrent : 32|16@1+ (0.0625,0) [0|4015.9375] "A" Vector__XXX

BO_ 2555051774 EVMCDCS1: 8 Vector__XXX
 SG_ EvMltCnntnCnCndtnngFlg : 0|2@1+ (1,0) [0|3] "" Vector__XXX
 SG_ EvMltCnntnRssCndtnngFlg : 2|2@1+ (1,0) [0|3] "" Vector__XXX
 SG_ EvMultiConnectionErrorCode : 8|4@1+ (1,0) [0|15] "" Vector__XXX
 SG_ EvMultiConnectionStateOfCharge : 16|8@1+ (0.5,0) [0|125] "%" Vector__XXX

BO_ 2555117310 EVMCDCLIM1: 8 Vector__XXX
 SG_ HrdOrEvMltCnntnDChrgngVltgMxmm : 0|16@1+ (0.05,0) [0|3212.75] "V" Vector__XXX
 SG_ HrdOrEvMltCnntnDChrgngCrrntMxmm : 16|16@1+ (0.0625,0) [0|4015.9375] "A" Vector__XXX
 SG_ HrdOrEvMltCnntnDChrgngPwrMxmm : 32|16@1+ (0.05,0) [0|3212.75] "kW" Vector__XXX
 SG_ HdOEvMtCtRqstdETsTp : 48|4@1+ (1,0) [0|15] "" Vector__XXX

BO_ 2565900286 WCSS1: 8 Vector__XXX
 SG_ WirelessChargerSystemState : 0|8@1+ (1,0) [0|250] "" Vector__XXX
 SG_ WrlssChrgrPrsntChrgngVltg : 8|16@1+ (0.03125,0) [0|2007.96875] "V" Vector__XXX
 SG_ WrlssChrgrPrsntChrgngCrrnt : 24|16@1+ (0.1,-3212.7) [-3212.7|3212.8] "A" Vector__XXX
 SG_ WirelessChargerDeratingReason : 40|8@1+ (1,0) [0|250] "" Vector__XXX

BO_ 2565900542 WCAQS: 8 Vector__XXX
 SG_ WrlssChrgrAlgnmntXQlt : 0|8@1+ (0.8,-100) [-100|100] "%" Vector__XXX
 SG_ WrlssChrgrAlgnmntYQlt : 8|8@1+ (0.8,-100) [-100|100] "%" Vector__XXX
 SG_ WrlssChrgrAlgnmntZQlt : 16|8@1+ (0.8,-100) [-100|100] "%" Vector__XXX
 SG_ WrlssChrgrAlgnmntOvrllQlt : 24|8@1+ (0.4,0) [0|100] "%" Vector__XXX

BO_ 2498819326 GRPASF: 8 Vector__XXX
 SG_ DemandedPowerFactor : 0|16@1+ (0.00006103515625,-1) [-1|2.92181396484375] "" Vector__XXX
 SG_ DemandedVoltage : 16|16@1+ (0.01,-321.28) [-321.28|321.27] "V" Vector__XXX
 SG_ SimulatedMainsFrequencyOffset : 32|16@1+ (0.0078125,0) [0|501.9921875] "Hz" Vector__XXX
 SG_ SimulatedMainsFrequencyStatus : 48|2@1+ (1,0) [0|3] "" Vector__XXX
 SG_ TstFntnFrThPrttnStts : 50|2@1+ (1,0) [0|3] "" Vector__XXX
 SG_ GtUdvtAdOvvtPttTstFtStts : 52|2@1+ (1,0) [0|3] "" Vector__XXX
 SG_ GnrtrUtltDplngPrttnTstFntnStts : 54|2@1+ (1,0) [0|3] "" Vector__XXX
 SG_ GeneratorFaultRideThroughStatus : 56|4@1+ (1,0) [0|15] "" Vector__XXX
 SG_ GnrtrRtvPwrUndrExttnLmtStts : 60|2@1+ (1,0) [0|3] "" Vector__XXX
 SG_ GnrtrRtvPwrOvrExttnLmtStts : 62|2@1+ (1,0) [0|3] "" Vector__XXX

BO_ 2364761342 TVD: 8 Vector__XXX
 SG_ LftTrnsmssnOtptShftDrtnlSpd : 0|16@1+ (0.25,-8031.75) [-8031.75|8032] "rpm" Vector__XXX
 SG_ RghtTrnsmssnOtptShftDrtnlSpd : 16|16@1+ (0.25,-8031.75) [-8031.75|8032] "rpm" Vector__XXX

BO_ 2566088190 EAPMCF3S2: 8 Vector__XXX
 SG_ PrplsnMtrClntFn3Vltg : 0|16@1+ (0.05,0) [0|3212.75] "V" Vector__XXX
 SG_ PrplsnMtrClntFn3Crrnt : 16|16@1+ (0.05,-1600) [-1600|1612.75] "A" Vector__XXX
 SG_ PrplsnMtrClntFn3HvlStts : 32|2@1+ (1,0) [0|3] "" Vector__XXX
 SG_ PrplsnMtrClntFn3PrntSpdStts : 34|2@1+ (1,0) [0|3] "" Vector__XXX
 SG_ PrplsnMtrClntFn3PrntSpd : 40|8@1+ (0.5,0) [0|125] "%" Vector__XXX

BO_ 2566088446 EAPMCF2S2: 8 Vector__XXX
 SG_ PrplsnMtrClntFn2Vltg : 0|16@1+ (0.05,0) [0|3212.75] "V" Vector__XXX
 SG_ PrplsnMtrClntFn2Crrnt : 16|16@1+ (0.05,-1600) [-1600|1612.75] "A" Vector__XXX
 SG_ PrplsnMtrClntFn2HvlStts : 32|2@1+ (1,0) [0|3] "" Vector__XXX
 SG_ PrplsnMtrClntFn2PrntSpdStts : 34|2@1+ (1,0) [0|3] "" Vector__XXX
 SG_ PrplsnMtrClntFn2PrntSpd : 40|8@1+ (0.5,0) [0|125] "%" Vector__XXX

BO_ 2566088702 EAPMCF1S2: 8 Vector__XXX
 SG_ PrplsnMtrClntFn1Vltg : 0|16@1+ (0.05,0) [0|3212.75] "V" Vector__XXX
 SG_ PrplsnMtrClntFn1Crrnt : 16|16@1+ (0.05,-1600) [-1600|1612.75] "A" Vector__XXX
 SG_ PrplsnMtrClntFn1HvlStts : 32|2@1+ (1,0) [0|3] "" Vector__XXX
 SG_ PrplsnMtrClntFn1PrntSpdStts : 34|2@1+ (1,0) [0|3] "" Vector__XXX
 SG_ PrplsnMtrClntFn1PrntSpd : 40|8@1+ (0.5,0) [0|125] "%" Vector__XXX

BO_ 2566088958 EAPECF3S2: 8 Vector__XXX
 SG_ PwrEltrnsClntFn3Vltg : 0|16@1+ (0.05,0) [0|3212.75] "V" Vector__XXX
 SG_ PwrEltrnsClntFn3Crrnt : 16|16@1+ (0.05,-1600) [-1600|1612.75] "A" Vector__XXX
 SG_ PwrEltrnsClntFn3HvlStts : 32|2@1+ (1,0) [0|3] "" Vector__XXX
 SG_ PwrEltrnsClntFn3PrntSpdStts : 34|2@1+ (1,0) [0|3] "" Vector__XXX
 SG_ PwrEltrnsClntFn3PrntSpd : 40|8@1+ (0.5,0) [0|125] "%" Vector__XXX

BO_ 2566089214 EAPECF2S2: 8 Vector__XXX
 SG_ PwrEltrnsClntFn2Vltg : 0|16@1+ (0.05,0) [0|3212.75] "V" Vector__XXX
 SG_ PwrEltrnsClntFn2Crrnt : 16|16@1+ (0.05,-1600) [-1600|1612.75] "A" Vector__XXX
 SG_ PwrEltrnsClntFn2HvlStts : 32|2@1+ (1,0) [0|3] "" Vector__XXX
 SG_ PwrEltrnsClntFn2PrntSpdStts : 34|2@1+ (1,0) [0|3] "" Vector__XXX
 SG_ PwrEltrnsClntFn2PrntSpd : 40|8@1+ (0.5,0) [0|125] "%" Vector__XXX

BO_ 2566089470 EAPECF1S2: 8 Vector__XXX
 SG_ PwrEltrnsClntFn1Vltg : 0|16@1+ (0.05,0) [0|3212.75] "V" Vector__XXX
 SG_ PwrEltrnsClntFn1Crrnt : 16|16@1+ (0.05,-1600) [-1600|1612.75] "A" Vector__XXX
 SG_ PwrEltrnsClntFn1HvlStts : 32|2@1+ (1,0) [0|3] "" Vector__XXX
 SG_ PwrEltrnsClntFn1PrntSpdStts : 34|2@1+ (1,0) [0|3] "" Vector__XXX
 SG_ PwrEltrnsClntFn1PrntSpd : 40|8@1+ (0.5,0) [0|125] "%" Vector__XXX

BO_ 2566089726 EAPMOPS2: 8 Vector__XXX
 SG_ PropulsionMotorOilPumpVoltage : 0|16@1+ (0.05,0) [0|3212.75] "V" Vector__XXX
 SG_ PropulsionMotorOilPumpCurrent : 16|16@1+ (0.05,-1600) [-1600|1612.75] "A" Vector__XXX
 SG_ PrplsnMtrOlPmpHvlStts : 32|2@1+ (1,0) [0|3] "" Vector__XXX
 SG_ PrplsnMtrOlPmpPrntSpdStts : 34|2@1+ (1,0) [0|3] "" Vector__XXX
 SG_ PrplsnMtrOlPmpPrntSpd : 40|8@1+ (0.5,0) [0|125] "%" Vector__XXX

BO_ 2566089982 EAPMCPS2: 8 Vector__XXX
 SG_ PrplsnMtrClntPmpVltg : 0|16@1+ (0.05,0) [0|3212.75] "V" Vector__XXX
 SG_ PrplsnMtrClntPmpCrrnt : 16|16@1+ (0.05,-1600) [-1600|1612.75] "A" Vector__XXX
 SG_ PrplsnMtrClntPmpHvlStts : 32|2@1+ (1,0) [0|3] "" Vector__XXX
 SG_ PrplsnMtrClntPmpPrntSpdStts : 34|2@1+ (1,0) [0|3] "" Vector__XXX
 SG_ PrplsnMtrClntPmpPrntSpd : 40|8@1+ (0.5,0) [0|125] "%" Vector__XXX

BO_ 2566090238 EAPECPS2: 8 Vector__XXX
 SG_ PwrEltrnsClntPmpVltg : 0|16@1+ (0.05,0) [0|3212.75] "V" Vector__XXX
 SG_ PwrEltrnsClntPmpCrrnt : 16|16@1+ (0.05,-1600) [-1600|1612.75] "A" Vector__XXX
 SG_ PwrEltrnsClntPmpHvlStts : 32|2@1+ (1,0) [0|3] "" Vector__XXX
 SG_ PwrEltrnsClntPmpPrntSpdStts : 34|2@1+ (1,0) [0|3] "" Vector__XXX
 SG_ PwrEltrnsClntPmpPrntSpd : 40|8@1+ (0.5,0) [0|125] "%" Vector__XXX

BO_ 2566090494 EAGCPS2: 8 Vector__XXX
 SG_ GeneratorCoolantPumpVoltage : 0|16@1+ (0.05,0) [0|3212.75] "V" Vector__XXX
 SG_ GeneratorCoolantPumpCurrent : 16|16@1+ (0.05,-1600) [-1600|1612.75] "A" Vector__XXX
 SG_ GeneratorCoolantPumpHvilStatus : 32|2@1+ (1,0) [0|3] "" Vector__XXX
 SG_ GnrtrClntPmpPrntSpdStts : 34|2@1+ (1,0) [0|3] "" Vector__XXX
 SG_ GnrtrClntPmpPrntSpd : 40|8@1+ (0.5,0) [0|125] "%" Vector__XXX

BO_ 2566090750 EAGCFS2: 8 Vector__XXX
 SG_ GeneratorCoolantFanVoltage : 0|16@1+ (0.05,0) [0|3212.75] "V" Vector__XXX
 SG_ GeneratorCoolantFanCurrent : 16|16@1+ (0.05,-1600) [-1600|1612.75] "A" Vector__XXX
 SG_ GeneratorCoolantFanHvilStatus : 32|2@1+ (1,0) [0|3] "" Vector__XXX
 SG_ GnrtrClntFnPrntSpdStts : 34|2@1+ (1,0) [0|3] "" Vector__XXX
 SG_ GeneratorCoolantFanPercentSpeed : 40|8@1+ (0.5,0) [0|125] "%" Vector__XXX

BO_ 2566091006 EAMS2: 8 Vector__XXX
 SG_ EltrfdAssrMtrVltg : 0|16@1+ (0.05,0) [0|3212.75] "V" Vector__XXX
 SG_ EltrfdAssrMtrCrrnt : 16|16@1+ (0.05,-1600) [-1600|1612.75] "A" Vector__XXX
 SG_ EltrfdAssrMtrHvlStts : 32|2@1+ (1,0) [0|3] "" Vector__XXX
 SG_ EltrfdAssrMtrInstnOfSttsDtSt2 : 34|4@1+ (1,0) [0|15] "" Vector__XXX
 SG_ EltrfdAssrMtrPrntSpdStts : 38|2@1+ (1,0) [0|3] "" Vector__XXX
 SG_ EltrfdAssrMtrPrntSpd : 40|8@1+ (0.5,0) [0|125] "%" Vector__XXX

BO_ 2633637886 ASI6: 8 Vector__XXX
 SG_ Aftertreatment2DefDosingMode : 0|8@1+ (1,0) [0|250] "count" Vector__XXX

BO_ 2566529278 EVMCDCLIM2: 8 Vector__XXX
 SG_ Evmcdclim2ExtendedId : 0|8@1+ (1,0) [0|250] "count" Vector__XXX
 SG_ EvMltCnntnBlkSttOfChrg : 8|8@1+ (0.5,0) [0|125] "%" Vector__XXX
 SG_ EvMltCnntnFllSttOfChrg : 16|8@1+ (0.5,0) [0|125] "%" Vector__XXX
 SG_ EvMultiConnectionEnergyCapacity : 24|16@1+ (1,0) [0|64255] "kWh" Vector__XXX
 SG_ EvMltCnntnEnrgRqstd : 40|16@1+ (1,0) [0|64255] "kWh" Vector__XXX

BO_ 2566529534 EVMCDCCIP: 8 Vector__XXX
 SG_ EvmcdccipExtendedId : 0|8@1+ (1,0) [0|250] "count" Vector__XXX
 SG_ EvMltCnntnBlkChrgngCmplt : 8|2@1+ (1,0) [0|3] "" Vector__XXX
 SG_ EvMltCnntnFllChrgngCmplt : 10|2@1+ (1,0) [0|3] "" Vector__XXX
 SG_ EvMltCnntnBlkChrgTmRmnng : 16|16@1+ (10,0) [0|642550] "s" Vector__XXX
 SG_ EvMltCnntnFllChrgTmRmnng : 32|16@1+ (10,0) [0|642550] "s" Vector__XXX
 SG_ EvMultiConnectionDepartureTime : 48|16@1+ (10,0) [0|642550] "s" Vector__XXX

BO_ 2566529790 SSV: 8 Vector__XXX
 SG_ EngnCrnksPrssrSnsrMdlSpplVltg : 0|8@1+ (0.05,0) [0|12.5] "V" Vector__XXX
 SG_ EngnFlDlvrPrssrSnsrMdlSpplVltg : 8|8@1+ (0.05,0) [0|12.5] "V" Vector__XXX
 SG_ EExstGsRtItPssSsMdSppVt : 16|8@1+ (0.05,0) [0|12.5] "V" Vector__XXX
 SG_ EngnFltrdFlSnsrMdlSpplVltg : 24|8@1+ (0.05,0) [0|12.5] "V" Vector__XXX
 SG_ EngnOlSnsrMdlSpplVltg : 32|8@1+ (0.05,0) [0|12.5] "V" Vector__XXX
 SG_ DsPttFtPssSsMdSppVt : 40|8@1+ (0.05,0) [0|12.5] "V" Vector__XXX
 SG_ EngnIntkArSnsrMdlSpplVltg : 48|8@1+ (0.05,0) [0|12.5] "V" Vector__XXX

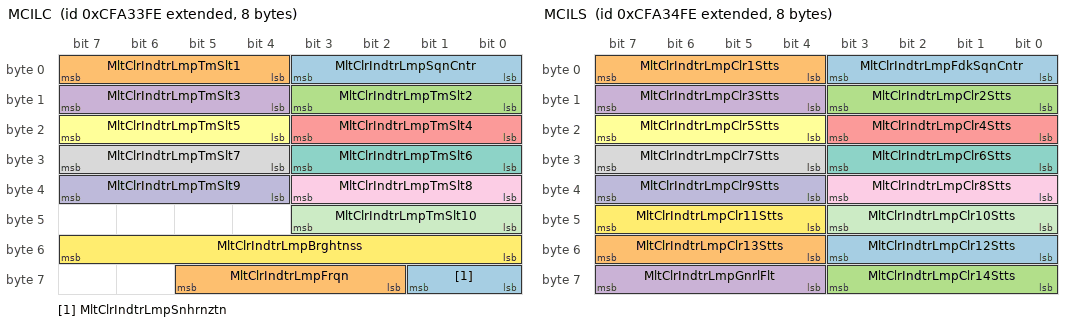
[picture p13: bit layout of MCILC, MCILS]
BO_ 2365207550 MCILC: 8 Vector__XXX
 SG_ MltClrIndtrLmpSqnCntr : 0|4@1+ (1,0) [0|13] "count" Vector__XXX
 SG_ MltClrIndtrLmpTmSlt1 : 4|4@1+ (1,0) [0|15] "" Vector__XXX
 SG_ MltClrIndtrLmpTmSlt2 : 8|4@1+ (1,0) [0|15] "" Vector__XXX
 SG_ MltClrIndtrLmpTmSlt3 : 12|4@1+ (1,0) [0|15] "" Vector__XXX
 SG_ MltClrIndtrLmpTmSlt4 : 16|4@1+ (1,0) [0|15] "" Vector__XXX
 SG_ MltClrIndtrLmpTmSlt5 : 20|4@1+ (1,0) [0|15] "" Vector__XXX
 SG_ MltClrIndtrLmpTmSlt6 : 24|4@1+ (1,0) [0|15] "" Vector__XXX
 SG_ MltClrIndtrLmpTmSlt7 : 28|4@1+ (1,0) [0|15] "" Vector__XXX
 SG_ MltClrIndtrLmpTmSlt8 : 32|4@1+ (1,0) [0|15] "" Vector__XXX
 SG_ MltClrIndtrLmpTmSlt9 : 36|4@1+ (1,0) [0|15] "" Vector__XXX
 SG_ MltClrIndtrLmpTmSlt10 : 40|4@1+ (1,0) [0|15] "" Vector__XXX
 SG_ MltClrIndtrLmpBrghtnss : 48|8@1+ (1,0) [0|100] "%" Vector__XXX
 SG_ MltClrIndtrLmpSnhrnztn : 56|2@1+ (1,0) [0|3] "" Vector__XXX
 SG_ MltClrIndtrLmpFrqn : 58|4@1+ (1,0) [0|15] "" Vector__XXX

BO_ 2365207806 MCILS: 8 Vector__XXX
 SG_ MltClrIndtrLmpFdkSqnCntr : 0|4@1+ (1,0) [0|13] "count" Vector__XXX
 SG_ MltClrIndtrLmpClr1Stts : 4|4@1+ (1,0) [0|15] "" Vector__XXX
 SG_ MltClrIndtrLmpClr2Stts : 8|4@1+ (1,0) [0|15] "" Vector__XXX
 SG_ MltClrIndtrLmpClr3Stts : 12|4@1+ (1,0) [0|15] "" Vector__XXX
 SG_ MltClrIndtrLmpClr4Stts : 16|4@1+ (1,0) [0|15] "" Vector__XXX
 SG_ MltClrIndtrLmpClr5Stts : 20|4@1+ (1,0) [0|15] "" Vector__XXX
 SG_ MltClrIndtrLmpClr6Stts : 24|4@1+ (1,0) [0|15] "" Vector__XXX
 SG_ MltClrIndtrLmpClr7Stts : 28|4@1+ (1,0) [0|15] "" Vector__XXX
 SG_ MltClrIndtrLmpClr8Stts : 32|4@1+ (1,0) [0|15] "" Vector__XXX
 SG_ MltClrIndtrLmpClr9Stts : 36|4@1+ (1,0) [0|15] "" Vector__XXX
 SG_ MltClrIndtrLmpClr10Stts : 40|4@1+ (1,0) [0|15] "" Vector__XXX
 SG_ MltClrIndtrLmpClr11Stts : 44|4@1+ (1,0) [0|15] "" Vector__XXX
 SG_ MltClrIndtrLmpClr12Stts : 48|4@1+ (1,0) [0|15] "" Vector__XXX
 SG_ MltClrIndtrLmpClr13Stts : 52|4@1+ (1,0) [0|15] "" Vector__XXX
 SG_ MltClrIndtrLmpClr14Stts : 56|4@1+ (1,0) [0|15] "" Vector__XXX
 SG_ MltClrIndtrLmpGnrlFlt : 60|4@1+ (1,0) [0|15] "" Vector__XXX

BO_ 2566648574 EFS3: 8 Vector__XXX
 SG_ EngnFlFltrDffrntlPrssrHghRsltn : 0|16@1+ (0.01,0) [0|642.55] "kPa" Vector__XXX
 SG_ EFFtStSdDtPssHRst : 16|16@1+ (0.03125,-273) [-273|1734.96875] "degC" Vector__XXX

BO_ 2633761022 TWBW: 16 Vector__XXX
 SG_ BrkWrLfRmnngTrlrAxl1LftWhl : 0|8@1+ (0.4,0) [0|100] "%" Vector__XXX
 SG_ BrkWrLfRmnngTrlrAxl1RghtWhl : 8|8@1+ (0.4,0) [0|100] "%" Vector__XXX
 SG_ BrkWrLfRmnngTrlrAxl2LftWhl : 16|8@1+ (0.4,0) [0|100] "%" Vector__XXX
 SG_ BrkWrLfRmnngTrlrAxl2RghtWhl : 24|8@1+ (0.4,0) [0|100] "%" Vector__XXX
 SG_ BrkWrLfRmnngTrlrAxl3LftWhl : 32|8@1+ (0.4,0) [0|100] "%" Vector__XXX
 SG_ BrkWrLfRmnngTrlrAxl3RghtWhl : 40|8@1+ (0.4,0) [0|100] "%" Vector__XXX
 SG_ BrkWrLfRmnngTrlrAxl4LftWhl : 48|8@1+ (0.4,0) [0|100] "%" Vector__XXX
 SG_ BrkWrLfRmnngTrlrAxl4RghtWhl : 56|8@1+ (0.4,0) [0|100] "%" Vector__XXX
 SG_ BrkWrLfRmnngTrlrAxl5LftWhl : 64|8@1+ (0.4,0) [0|100] "%" Vector__XXX
 SG_ BrkWrLfRmnngTrlrAxl5RghtWhl : 72|8@1+ (0.4,0) [0|100] "%" Vector__XXX
 SG_ BrkWrLfRmnngTrlrAxl6LftWhl : 80|8@1+ (0.4,0) [0|100] "%" Vector__XXX
 SG_ BrkWrLfRmnngTrlrAxl6RghtWhl : 88|8@1+ (0.4,0) [0|100] "%" Vector__XXX
 SG_ BrkWrLfRmnngTrlrAxl7LftWhl : 96|8@1+ (0.4,0) [0|100] "%" Vector__XXX
 SG_ BrkWrLfRmnngTrlrAxl7RghtWhl : 104|8@1+ (0.4,0) [0|100] "%" Vector__XXX
 SG_ BrkWrLfRmnngTrlrAxl8LftWhl : 112|8@1+ (0.4,0) [0|100] "%" Vector__XXX
 SG_ BrkWrLfRmnngTrlrAxl8RghtWhl : 120|8@1+ (0.4,0) [0|100] "%" Vector__XXX

BO_ 2566659838 VEP16: 8 Vector__XXX
 SG_ SlBttrPk1Bttr1ChrgCrrntLmt : 0|16@1+ (0.05,-1600) [0|1600] "A" Vector__XXX
 SG_ SlBttrPk1Bttr2ChrgCrrntLmt : 16|16@1+ (0.05,-1600) [0|1600] "A" Vector__XXX
 SG_ SlBttrPk1Bttr3ChrgCrrntLmt : 32|16@1+ (0.05,-1600) [0|1600] "A" Vector__XXX
 SG_ SlBttrPk1Bttr4ChrgCrrntLmt : 48|16@1+ (0.05,-1600) [0|1600] "A" Vector__XXX

BO_ 2566660094 VEP17: 8 Vector__XXX
 SG_ SlBttrPk1Bttr1DshrgCrrntLmt : 0|16@1+ (0.05,-1600) [-1600|0] "A" Vector__XXX
 SG_ SlBttrPk1Bttr2DshrgCrrntLmt : 16|16@1+ (0.05,-1600) [-1600|0] "A" Vector__XXX
 SG_ SlBttrPk1Bttr3DshrgCrrntLmt : 32|16@1+ (0.05,-1600) [-1600|0] "A" Vector__XXX
 SG_ SlBttrPk1Bttr4DshrgCrrntLmt : 48|16@1+ (0.05,-1600) [-1600|0] "A" Vector__XXX

BO_ 2565904382 MG1ITPS: 8 Vector__XXX
 SG_ MtrGnrtr1InvrtrThrmlCpltUsd : 0|8@1+ (0.4,0) [0|100] "%" Vector__XXX
 SG_ MtrGnrtr1InvrtrThrmlCpltLmt : 8|8@1+ (0.4,0) [0|100] "%" Vector__XXX

BO_ 2565904638 MG2ITPS: 8 Vector__XXX
 SG_ MtrGnrtr2InvrtrThrmlCpltUsd : 0|8@1+ (0.4,0) [0|100] "%" Vector__XXX
 SG_ MtrGnrtr2InvrtrThrmlCpltLmt : 8|8@1+ (0.4,0) [0|100] "%" Vector__XXX

BO_ 2565904894 MG3ITPS: 8 Vector__XXX
 SG_ MtrGnrtr3InvrtrThrmlCpltUsd : 0|8@1+ (0.4,0) [0|100] "%" Vector__XXX
 SG_ MtrGnrtr3InvrtrThrmlCpltLmt : 8|8@1+ (0.4,0) [0|100] "%" Vector__XXX

BO_ 2565905150 MG4ITPS: 8 Vector__XXX
 SG_ MtrGnrtr4InvrtrThrmlCpltUsd : 0|8@1+ (0.4,0) [0|100] "%" Vector__XXX
 SG_ MtrGnrtr4InvrtrThrmlCpltLmt : 8|8@1+ (0.4,0) [0|100] "%" Vector__XXX

BO_ 2565905406 MG5ITPS: 8 Vector__XXX
 SG_ MtrGnrtr5InvrtrThrmlCpltUsd : 0|8@1+ (0.4,0) [0|100] "%" Vector__XXX
 SG_ MtrGnrtr5InvrtrThrmlCpltLmt : 8|8@1+ (0.4,0) [0|100] "%" Vector__XXX

BO_ 2565905662 MG6ITPS: 8 Vector__XXX
 SG_ MtrGnrtr6InvrtrThrmlCpltUsd : 0|8@1+ (0.4,0) [0|100] "%" Vector__XXX
 SG_ MtrGnrtr6InvrtrThrmlCpltLmt : 8|8@1+ (0.4,0) [0|100] "%" Vector__XXX

BO_ 2565918462 ETCC4: 8 Vector__XXX
 SG_ EngnTrhrgrWstgtAttr3Cmmnd : 0|16@1+ (0.0025,0) [0|160.6375] "%" Vector__XXX
 SG_ EngnTrhrgrWstgtAttr4Cmmnd : 16|16@1+ (0.0025,0) [0|160.6375] "%" Vector__XXX

BO_ 2565918718 ETWAI2: 8 Vector__XXX
 SG_ EngnTrhrgrWstgtAttr3OprtnStts : 0|4@1+ (1,0) [0|15] "" Vector__XXX
 SG_ EngnTrhrgrWstgtAttr4OprtnStts : 4|4@1+ (1,0) [0|15] "" Vector__XXX

BO_ 2566523646 MG1TPS: 8 Vector__XXX
 SG_ MtrGnrtr1ThrmlCpltUsd : 0|8@1+ (0.4,0) [0|100] "%" Vector__XXX
 SG_ MtrGnrtr1ThrmlCpltLmt : 8|8@1+ (0.4,0) [0|100] "%" Vector__XXX

BO_ 2566523902 MG2TPS: 8 Vector__XXX
 SG_ MtrGnrtr2ThrmlCpltUsd : 0|8@1+ (0.4,0) [0|100] "%" Vector__XXX
 SG_ MtrGnrtr2ThrmlCpltLmt : 8|8@1+ (0.4,0) [0|100] "%" Vector__XXX

BO_ 2566524158 MG3TPS: 8 Vector__XXX
 SG_ MtrGnrtr3ThrmlCpltUsd : 0|8@1+ (0.4,0) [0|100] "%" Vector__XXX
 SG_ MtrGnrtr3ThrmlCpltLmt : 8|8@1+ (0.4,0) [0|100] "%" Vector__XXX

BO_ 2566524414 MG4TPS: 8 Vector__XXX
 SG_ MtrGnrtr4ThrmlCpltUsd : 0|8@1+ (0.4,0) [0|100] "%" Vector__XXX
 SG_ MtrGnrtr4ThrmlCpltLmt : 8|8@1+ (0.4,0) [0|100] "%" Vector__XXX

BO_ 2566524670 MG5TPS: 8 Vector__XXX
 SG_ MtrGnrtr5ThrmlCpltUsd : 0|8@1+ (0.4,0) [0|100] "%" Vector__XXX
 SG_ MtrGnrtr5ThrmlCpltLmt : 8|8@1+ (0.4,0) [0|100] "%" Vector__XXX

BO_ 2566524926 MG6TPS: 8 Vector__XXX
 SG_ MtrGnrtr6ThrmlCpltUsd : 0|8@1+ (0.4,0) [0|100] "%" Vector__XXX
 SG_ MtrGnrtr6ThrmlCpltLmt : 8|8@1+ (0.4,0) [0|100] "%" Vector__XXX

BO_ 2566525182 OBPETD: 8 Vector__XXX
 SG_ ObpEventSeconds : 0|8@1+ (0.25,0) [0|59.75] "s" Vector__XXX
 SG_ ObpEventMinutes : 8|8@1+ (1,0) [0|59] "min" Vector__XXX
 SG_ ObpEventHours : 16|8@1+ (1,0) [0|23] "h" Vector__XXX
 SG_ ObpEventMonth : 24|8@1+ (1,0) [1|12] "month" Vector__XXX
 SG_ ObpEventDay : 32|8@1+ (0.25,0) [0.25|31.75] "days" Vector__XXX
 SG_ ObpEventYear : 40|8@1+ (1,1985) [1985|2235] "year" Vector__XXX
 SG_ ObpEventLocalMinuteOffset : 48|8@1+ (1,-125) [-59|59] "min" Vector__XXX
 SG_ ObpEventLocalHourOffset : 56|8@1+ (1,-125) [-23|23] "h" Vector__XXX

BO_ 2566525438 A1LOSCRSI1: 8 Vector__XXX
 SG_ Atttt1TtLtOSDsExstFdUsd : 0|32@1+ (0.05,0) [0|210554060.75] "l" Vector__XXX
 SG_ Atttt1TpLtOSDsExstFd : 32|32@1+ (0.05,0) [0|210554060.75] "l" Vector__XXX

BO_ 2566525950 CSERSC: 20 Vector__XXX
 SG_ CtCCtstHtEUtFtpCdSttTT : 0|16@1+ (1,0) [0|64255] "kJ" Vector__XXX
 SG_ CtCCtstHtEUtFtpEOtptE : 16|16@1+ (1,0) [0|64255] "kJ" Vector__XXX
 SG_ CtCCtstHtEUtCtstCdSttTTptTsd : 32|16@1+ (1,0) [0|64255] "kJ" Vector__XXX
 SG_ CtCEOtptEUtFtpCdSttTT : 48|16@1+ (5,0) [0|321275] "kJ" Vector__XXX
 SG_ CtCEOtptEUtCtstCdSttTTptTsd : 64|16@1+ (5,0) [0|321275] "kJ" Vector__XXX
 SG_ CtCEMssUtFtpCdSttTT : 80|16@1+ (5,0) [0|321275] "g" Vector__XXX
 SG_ CtCEMssUtFtpEOtptE : 96|16@1+ (5,0) [0|321275] "g" Vector__XXX
 SG_ CtCEMssUtCdSttTCtstTptTsd : 112|16@1+ (5,0) [0|321275] "g" Vector__XXX
 SG_ CrrntClTmUntlFtpEngnOtptEnrg : 128|16@1+ (1,0) [0|64255] "s" Vector__XXX
 SG_ CtCTUtCtstCdSttTTptTsd : 144|16@1+ (1,0) [0|64255] "s" Vector__XXX

BO_ 2566526206 CSERSA: 20 Vector__XXX
 SG_ AvCtstHtEUtFtpCdSttTT : 0|16@1+ (1,0) [0|64255] "kJ" Vector__XXX
 SG_ AvCtstHtEUtFtpEOtptE : 16|16@1+ (1,0) [0|64255] "kJ" Vector__XXX
 SG_ AvCtstHtEUtCtstCdSttTTptTsd : 32|16@1+ (1,0) [0|64255] "kJ" Vector__XXX
 SG_ AvEOtptEUtFtpCdSttTT : 48|16@1+ (5,0) [0|321275] "kJ" Vector__XXX
 SG_ AvEOtptEUtCdSttTCtstTptTsd : 64|16@1+ (5,0) [0|321275] "kJ" Vector__XXX
 SG_ AvrgEgrMssAtFtpCldStrtTrkngTm : 80|16@1+ (5,0) [0|321275] "g" Vector__XXX
 SG_ AvrgEgrMssAtFtpEngnOtptEnrg : 96|16@1+ (5,0) [0|321275] "g" Vector__XXX
 SG_ AvEMssUtFtpCdSttTCtstTpt : 112|16@1+ (5,0) [0|321275] "g" Vector__XXX
 SG_ AvrgTmUntlFtpEngnOtptEnrg : 128|16@1+ (1,0) [0|64255] "s" Vector__XXX
 SG_ AvTUtCtstCdSttTTpt : 144|16@1+ (1,0) [0|64255] "s" Vector__XXX

BO_ 2365200126 HVESSIS1: 8 Vector__XXX
 SG_ HvssHghVltgIntrnlVltgLvl1 : 0|16@1+ (0.125,0) [0|8031.875] "V" Vector__XXX
 SG_ HvssHghVltgIntrnlCrrnt1 : 16|16@1+ (0.125,-4000) [-4000|4031.875] "A" Vector__XXX
 SG_ HvssHghVltgIntrnlVltgLvl2 : 32|16@1+ (0.125,0) [0|8031.875] "V" Vector__XXX
 SG_ HvssHghVltgIntrnlCrrnt2 : 48|16@1+ (0.125,-4000) [-4000|4031.875] "A" Vector__XXX

BO_ 2365200382 HVESSIS2: 8 Vector__XXX
 SG_ HvssHghVltgIntrnlVltgLvl3 : 0|16@1+ (0.125,0) [0|8031.875] "V" Vector__XXX
 SG_ HvssHghVltgIntrnlCrrnt3 : 16|16@1+ (0.125,-4000) [-4000|4031.875] "A" Vector__XXX
 SG_ HvssHghVltgIntrnlVltgLvl4 : 32|16@1+ (0.125,0) [0|8031.875] "V" Vector__XXX
 SG_ HvssHghVltgIntrnlCrrnt4 : 48|16@1+ (0.125,-4000) [-4000|4031.875] "A" Vector__XXX

BO_ 2365200638 HVESSIS3: 8 Vector__XXX
 SG_ HvssHghVltgIntrnlVltgLvl5 : 0|16@1+ (0.125,0) [0|8031.875] "V" Vector__XXX
 SG_ HvssHghVltgIntrnlCrrnt5 : 16|16@1+ (0.125,-4000) [-4000|4031.875] "A" Vector__XXX
 SG_ HvssHghVltgIntrnlVltgLvl6 : 32|16@1+ (0.125,0) [0|8031.875] "V" Vector__XXX
 SG_ HvssHghVltgIntrnlCrrnt6 : 48|16@1+ (0.125,-4000) [-4000|4031.875] "A" Vector__XXX

BO_ 2365200894 HVESSIS4: 8 Vector__XXX
 SG_ HvssHghVltgIntrnlVltgLvl7 : 0|16@1+ (0.125,0) [0|8031.875] "V" Vector__XXX
 SG_ HvssHghVltgIntrnlCrrnt7 : 16|16@1+ (0.125,-4000) [-4000|4031.875] "A" Vector__XXX
 SG_ HvssHghVltgIntrnlVltgLvl8 : 32|16@1+ (0.125,0) [0|8031.875] "V" Vector__XXX
 SG_ HvssHghVltgIntrnlCrrnt8 : 48|16@1+ (0.125,-4000) [-4000|4031.875] "A" Vector__XXX

BO_ 2432310014 EEC23: 8 Vector__XXX
 SG_ EngnCrnksPrssrCntrlAttr1Cmmnd : 0|16@1+ (0.0025,0) [0|160.6375] "%" Vector__XXX
 SG_ EngnCrnksPrssrCntrlAttr2Cmmnd : 16|16@1+ (0.0025,0) [0|160.6375] "%" Vector__XXX

BO_ 2432310270 EEC24: 8 Vector__XXX
 SG_ EngnCrnksPrssrCntrlAttr1Tmprtr : 0|8@1+ (1,-40) [-40|210] "degC" Vector__XXX
 SG_ EngnCrnksPrssrCntrlAttr1Pstn : 8|8@1+ (0.4,0) [0|100] "%" Vector__XXX
 SG_ ECsPssCtAtt1DsdPst : 16|8@1+ (0.4,0) [0|100] "%" Vector__XXX
 SG_ ECsPssCtAtt1PF : 24|5@1+ (1,0) [0|31] "" Vector__XXX
 SG_ ECsPssCtAtt1TptStts : 29|3@1+ (1,0) [0|7] "" Vector__XXX
 SG_ ECsPssCtAtt1OptStts : 32|4@1+ (1,0) [0|15] "" Vector__XXX

BO_ 2432310526 EEC25: 8 Vector__XXX
 SG_ EngnCrnksPrssrCntrlAttr2Tmprtr : 0|8@1+ (1,-40) [-40|210] "degC" Vector__XXX
 SG_ EngnCrnksPrssrCntrlAttr2Pstn : 8|8@1+ (0.4,0) [0|100] "%" Vector__XXX
 SG_ ECsPssCtAtt2DsdPst : 16|8@1+ (0.4,0) [0|100] "%" Vector__XXX
 SG_ ECsPssCtAtt2PF : 24|5@1+ (1,0) [0|31] "" Vector__XXX
 SG_ ECsPssCtAtt2TptStts : 29|3@1+ (1,0) [0|7] "" Vector__XXX
 SG_ ECsPssCtAtt2OptStts : 32|4@1+ (1,0) [0|15] "" Vector__XXX

BO_ 2365201918 HVBCC1: 8 Vector__XXX
 SG_ HghVltgBsIntrf1CnntCmmnd : 0|2@1+ (1,0) [0|3] "" Vector__XXX
 SG_ HghVltgBsIntrf2CnntCmmnd : 2|2@1+ (1,0) [0|3] "" Vector__XXX
 SG_ HghVltgBsIntrf3CnntCmmnd : 4|2@1+ (1,0) [0|3] "" Vector__XXX
 SG_ HghVltgBsIntrf4CnntCmmnd : 6|2@1+ (1,0) [0|3] "" Vector__XXX
 SG_ HghVltgBsIntrf5CnntCmmnd : 8|2@1+ (1,0) [0|3] "" Vector__XXX
 SG_ HghVltgBsIntrf6CnntCmmnd : 10|2@1+ (1,0) [0|3] "" Vector__XXX
 SG_ HghVltgBsIntrf7CnntCmmnd : 12|2@1+ (1,0) [0|3] "" Vector__XXX
 SG_ HghVltgBsIntrf8CnntCmmnd : 14|2@1+ (1,0) [0|3] "" Vector__XXX
 SG_ HghVltgBsIntrf9CnntCmmnd : 16|2@1+ (1,0) [0|3] "" Vector__XXX
 SG_ HghVltgBsIntrf10CnntCmmnd : 18|2@1+ (1,0) [0|3] "" Vector__XXX
 SG_ HghVltgBsIntrf11CnntCmmnd : 20|2@1+ (1,0) [0|3] "" Vector__XXX
 SG_ HghVltgBsIntrf12CnntCmmnd : 22|2@1+ (1,0) [0|3] "" Vector__XXX
 SG_ HghVltgBsIntrf13CnntCmmnd : 24|2@1+ (1,0) [0|3] "" Vector__XXX
 SG_ HghVltgBsIntrf14CnntCmmnd : 26|2@1+ (1,0) [0|3] "" Vector__XXX
 SG_ HghVltgBsIntrf15CnntCmmnd : 28|2@1+ (1,0) [0|3] "" Vector__XXX
 SG_ HghVltgBsIntrf16CnntCmmnd : 30|2@1+ (1,0) [0|3] "" Vector__XXX
 SG_ HghVltgBsIntrf17CnntCmmnd : 32|2@1+ (1,0) [0|3] "" Vector__XXX
 SG_ HghVltgBsIntrf18CnntCmmnd : 34|2@1+ (1,0) [0|3] "" Vector__XXX
 SG_ HghVltgBsIntrf19CnntCmmnd : 36|2@1+ (1,0) [0|3] "" Vector__XXX
 SG_ HghVltgBsIntrf20CnntCmmnd : 38|2@1+ (1,0) [0|3] "" Vector__XXX
 SG_ HghVltgBsIntrf21CnntCmmnd : 40|2@1+ (1,0) [0|3] "" Vector__XXX
 SG_ HghVltgBsIntrf22CnntCmmnd : 42|2@1+ (1,0) [0|3] "" Vector__XXX
 SG_ HghVltgBsIntrf23CnntCmmnd : 44|2@1+ (1,0) [0|3] "" Vector__XXX
 SG_ HghVltgBsIntrf24CnntCmmnd : 46|2@1+ (1,0) [0|3] "" Vector__XXX
 SG_ Hvbcc1EmbeddedIntegritySupport : 50|2@1+ (1,0) [0|3] "" Vector__XXX
 SG_ Hvbcc1Counter : 52|4@1+ (1,0) [0|15] "" Vector__XXX
 SG_ Hvbcc1Crc : 56|8@1+ (1,0) [0|250] "count" Vector__XXX

BO_ 2365202174 HVBCS1: 8 Vector__XXX
 SG_ HghVltgBsIntrf1PstvCnttrStt : 0|2@1+ (1,0) [0|3] "" Vector__XXX
 SG_ HghVltgBsIntrf1NgtvCnttrStt : 2|2@1+ (1,0) [0|3] "" Vector__XXX
 SG_ HghVltgBsIntrf2PstvCnttrStt : 4|2@1+ (1,0) [0|3] "" Vector__XXX
 SG_ HghVltgBsIntrf2NgtvCnttrStt : 6|2@1+ (1,0) [0|3] "" Vector__XXX
 SG_ HghVltgBsIntrf3PstvCnttrStt : 8|2@1+ (1,0) [0|3] "" Vector__XXX
 SG_ HghVltgBsIntrf3NgtvCnttrStt : 10|2@1+ (1,0) [0|3] "" Vector__XXX
 SG_ HghVltgBsIntrf4PstvCnttrStt : 12|2@1+ (1,0) [0|3] "" Vector__XXX
 SG_ HghVltgBsIntrf4NgtvCnttrStt : 14|2@1+ (1,0) [0|3] "" Vector__XXX
 SG_ HghVltgBsIntrf5PstvCnttrStt : 16|2@1+ (1,0) [0|3] "" Vector__XXX
 SG_ HghVltgBsIntrf5NgtvCnttrStt : 18|2@1+ (1,0) [0|3] "" Vector__XXX
 SG_ HghVltgBsIntrf6PstvCnttrStt : 20|2@1+ (1,0) [0|3] "" Vector__XXX
 SG_ HghVltgBsIntrf6NgtvCnttrStt : 22|2@1+ (1,0) [0|3] "" Vector__XXX
 SG_ HghVltgBsIntrf7PstvCnttrStt : 24|2@1+ (1,0) [0|3] "" Vector__XXX
 SG_ HghVltgBsIntrf7NgtvCnttrStt : 26|2@1+ (1,0) [0|3] "" Vector__XXX
 SG_ HghVltgBsIntrf8PstvCnttrStt : 28|2@1+ (1,0) [0|3] "" Vector__XXX
 SG_ HghVltgBsIntrf8NgtvCnttrStt : 30|2@1+ (1,0) [0|3] "" Vector__XXX
 SG_ Hvbcs1EmbeddedIntegritySupport : 50|2@1+ (1,0) [0|3] "" Vector__XXX
 SG_ Hvbcs1Counter : 52|4@1+ (1,0) [0|15] "" Vector__XXX
 SG_ Hvbcs1Crc : 56|8@1+ (1,0) [0|250] "count" Vector__XXX

BO_ 2365333758 HVESSMS2: 8 Vector__XXX
 SG_ HvessModule33OperationalStatus : 0|2@1+ (1,0) [0|3] "" Vector__XXX
 SG_ HvessModule34OperationalStatus : 2|2@1+ (1,0) [0|3] "" Vector__XXX
 SG_ HvessModule35OperationalStatus : 4|2@1+ (1,0) [0|3] "" Vector__XXX
 SG_ HvessModule36OperationalStatus : 6|2@1+ (1,0) [0|3] "" Vector__XXX
 SG_ HvessModule37OperationalStatus : 8|2@1+ (1,0) [0|3] "" Vector__XXX
 SG_ HvessModule38OperationalStatus : 10|2@1+ (1,0) [0|3] "" Vector__XXX
 SG_ HvessModule39OperationalStatus : 12|2@1+ (1,0) [0|3] "" Vector__XXX
 SG_ HvessModule40OperationalStatus : 14|2@1+ (1,0) [0|3] "" Vector__XXX
 SG_ HvessModule41OperationalStatus : 16|2@1+ (1,0) [0|3] "" Vector__XXX
 SG_ HvessModule42OperationalStatus : 18|2@1+ (1,0) [0|3] "" Vector__XXX
 SG_ HvessModule43OperationalStatus : 20|2@1+ (1,0) [0|3] "" Vector__XXX
 SG_ HvessModule44OperationalStatus : 22|2@1+ (1,0) [0|3] "" Vector__XXX
 SG_ HvessModule45OperationalStatus : 24|2@1+ (1,0) [0|3] "" Vector__XXX
 SG_ HvessModule46OperationalStatus : 26|2@1+ (1,0) [0|3] "" Vector__XXX
 SG_ HvessModule47OperationalStatus : 28|2@1+ (1,0) [0|3] "" Vector__XXX
 SG_ HvessModule48OperationalStatus : 30|2@1+ (1,0) [0|3] "" Vector__XXX
 SG_ HvessModule49OperationalStatus : 32|2@1+ (1,0) [0|3] "" Vector__XXX
 SG_ HvessModule50OperationalStatus : 34|2@1+ (1,0) [0|3] "" Vector__XXX
 SG_ HvessModule51OperationalStatus : 36|2@1+ (1,0) [0|3] "" Vector__XXX
 SG_ HvessModule52OperationalStatus : 38|2@1+ (1,0) [0|3] "" Vector__XXX
 SG_ HvessModule53OperationalStatus : 40|2@1+ (1,0) [0|3] "" Vector__XXX
 SG_ HvessModule54OperationalStatus : 42|2@1+ (1,0) [0|3] "" Vector__XXX
 SG_ HvessModule55OperationalStatus : 44|2@1+ (1,0) [0|3] "" Vector__XXX
 SG_ HvessModule56OperationalStatus : 46|2@1+ (1,0) [0|3] "" Vector__XXX
 SG_ HvessModule57OperationalStatus : 48|2@1+ (1,0) [0|3] "" Vector__XXX
 SG_ HvessModule58OperationalStatus : 50|2@1+ (1,0) [0|3] "" Vector__XXX
 SG_ HvessModule59OperationalStatus : 52|2@1+ (1,0) [0|3] "" Vector__XXX
 SG_ HvessModule60OperationalStatus : 54|2@1+ (1,0) [0|3] "" Vector__XXX
 SG_ HvessModule61OperationalStatus : 56|2@1+ (1,0) [0|3] "" Vector__XXX
 SG_ HvessModule62OperationalStatus : 58|2@1+ (1,0) [0|3] "" Vector__XXX
 SG_ HvessModule63OperationalStatus : 60|2@1+ (1,0) [0|3] "" Vector__XXX
 SG_ HvessModule64OperationalStatus : 62|2@1+ (1,0) [0|3] "" Vector__XXX

BO_ 2365334014 HVESSMS3: 8 Vector__XXX
 SG_ HvessModule65OperationalStatus : 0|2@1+ (1,0) [0|3] "" Vector__XXX
 SG_ HvessModule66OperationalStatus : 2|2@1+ (1,0) [0|3] "" Vector__XXX
 SG_ HvessModule67OperationalStatus : 4|2@1+ (1,0) [0|3] "" Vector__XXX
 SG_ HvessModule68OperationalStatus : 6|2@1+ (1,0) [0|3] "" Vector__XXX
 SG_ HvessModule69OperationalStatus : 8|2@1+ (1,0) [0|3] "" Vector__XXX
 SG_ HvessModule70OperationalStatus : 10|2@1+ (1,0) [0|3] "" Vector__XXX
 SG_ HvessModule71OperationalStatus : 12|2@1+ (1,0) [0|3] "" Vector__XXX
 SG_ HvessModule72OperationalStatus : 14|2@1+ (1,0) [0|3] "" Vector__XXX
 SG_ HvessModule73OperationalStatus : 16|2@1+ (1,0) [0|3] "" Vector__XXX
 SG_ HvessModule74OperationalStatus : 18|2@1+ (1,0) [0|3] "" Vector__XXX
 SG_ HvessModule75OperationalStatus : 20|2@1+ (1,0) [0|3] "" Vector__XXX
 SG_ HvessModule76OperationalStatus : 22|2@1+ (1,0) [0|3] "" Vector__XXX
 SG_ HvessModule77OperationalStatus : 24|2@1+ (1,0) [0|3] "" Vector__XXX
 SG_ HvessModule78OperationalStatus : 26|2@1+ (1,0) [0|3] "" Vector__XXX
 SG_ HvessModule79OperationalStatus : 28|2@1+ (1,0) [0|3] "" Vector__XXX
 SG_ HvessModule80OperationalStatus : 30|2@1+ (1,0) [0|3] "" Vector__XXX
 SG_ HvessModule81OperationalStatus : 32|2@1+ (1,0) [0|3] "" Vector__XXX
 SG_ HvessModule82OperationalStatus : 34|2@1+ (1,0) [0|3] "" Vector__XXX
 SG_ HvessModule83OperationalStatus : 36|2@1+ (1,0) [0|3] "" Vector__XXX
 SG_ HvessModule84OperationalStatus : 38|2@1+ (1,0) [0|3] "" Vector__XXX
 SG_ HvessModule85OperationalStatus : 40|2@1+ (1,0) [0|3] "" Vector__XXX
 SG_ HvessModule86OperationalStatus : 42|2@1+ (1,0) [0|3] "" Vector__XXX
 SG_ HvessModule87OperationalStatus : 44|2@1+ (1,0) [0|3] "" Vector__XXX
 SG_ HvessModule88OperationalStatus : 46|2@1+ (1,0) [0|3] "" Vector__XXX
 SG_ HvessModule89OperationalStatus : 48|2@1+ (1,0) [0|3] "" Vector__XXX
 SG_ HvessModule90OperationalStatus : 50|2@1+ (1,0) [0|3] "" Vector__XXX
 SG_ HvessModule91OperationalStatus : 52|2@1+ (1,0) [0|3] "" Vector__XXX
 SG_ HvessModule92OperationalStatus : 54|2@1+ (1,0) [0|3] "" Vector__XXX
 SG_ HvessModule93OperationalStatus : 56|2@1+ (1,0) [0|3] "" Vector__XXX
 SG_ HvessModule94OperationalStatus : 58|2@1+ (1,0) [0|3] "" Vector__XXX
 SG_ HvessModule95OperationalStatus : 60|2@1+ (1,0) [0|3] "" Vector__XXX
 SG_ HvessModule96OperationalStatus : 62|2@1+ (1,0) [0|3] "" Vector__XXX

BO_ 2566662398 CCVS6: 8 Vector__XXX
 SG_ CrrntRdwVhlSpdLmtMd : 0|4@1+ (1,0) [0|15] "" Vector__XXX
 SG_ SltdRdwVhlSpdLmt : 8|16@1+ (0.00390625,0) [0|250.99609375] "km/h" Vector__XXX
 SG_ CurrentRoadwayVehicleSpeedLimit : 24|16@1+ (0.00390625,0) [0|250.99609375] "km/h" Vector__XXX
 SG_ MapBasedVehicleSpeedLimit : 40|16@1+ (0.00390625,0) [0|250.99609375] "km/h" Vector__XXX
 SG_ CrrntRdwVhlSpdLmtDgrdtnStts : 56|3@1+ (1,0) [0|7] "" Vector__XXX

BO_ 2365342974 HVESSD15: 8 Vector__XXX
 SG_ HvssNmnlDshrgCrrntLmt : 0|16@1+ (0.125,-4000) [-4000|0] "A" Vector__XXX
 SG_ HvessNominalChargeCurrentLimit : 16|16@1+ (0.125,-4000) [0|4031.875] "A" Vector__XXX

BO_ 2566522622 DD3: 8 Vector__XXX
 SG_ PrdtvVhlSpdAdjstmntIndtrStt : 0|3@1+ (1,0) [0|7] "" Vector__XXX
 SG_ PrdtvVhlSpdAdjstmntSpd : 8|16@1+ (0.00390625,0) [0|250.99609375] "km/h" Vector__XXX

BO_ 2566523134 REFTIME: 8 Vector__XXX
 SG_ ReferenceTime : 0|32@1+ (1,0) [0|4211081215] "s" Vector__XXX
 SG_ ReferenceTimeFractional : 32|24@1+ (1,0) [0|999999] "micro s" Vector__XXX
 SG_ TimeEpoch : 56|4@1+ (1,0) [0|15] "" Vector__XXX
 SG_ TimeTxReason : 60|4@1+ (1,0) [0|15] "" Vector__XXX

BO_ 2566523390 SH: 8 Vector__XXX
 SG_ TotalSoftwareDistance : 0|32@1+ (0.125,0) [0|526385151.875] "km" Vector__XXX

BO_ 2352938750 FCSCC: 8 Vector__XXX
 SG_ FuelCellSystemControlCommandCrc : 0|8@1+ (1,0) [0|250] "count" Vector__XXX
 SG_ FlCllSstmCntrlCmmndCntr : 8|4@1+ (1,0) [0|15] "" Vector__XXX
 SG_ FuelCellSystemStateCommand : 16|4@1+ (1,0) [0|15] "" Vector__XXX
 SG_ FlCllSstmCntrlMdCmmnd : 20|4@1+ (1,0) [0|15] "" Vector__XXX
 SG_ FuelCellSystemNetOutputCommand : 24|16@1+ (0.00390625,-125) [0|125.99609375] "%" Vector__XXX
 SG_ FuelCellSystemPurgeWaterCommand : 40|3@1+ (1,0) [0|7] "" Vector__XXX

BO_ 2353004286 FCSPLC: 8 Vector__XXX
 SG_ FlCllSstmPwrLmtCmmndCr : 0|8@1+ (1,0) [0|250] "count" Vector__XXX
 SG_ FlCllSstmPwrLmtCmmndCntr : 8|4@1+ (1,0) [0|15] "" Vector__XXX
 SG_ FlCllSstmNtPwrMxmmLmtCmmnd : 16|16@1+ (0.00390625,-125) [0|125.99609375] "%" Vector__XXX
 SG_ FlCllSstmNtPwrMnmmLmtCmmnd : 32|16@1+ (0.00390625,-125) [0|125.99609375] "%" Vector__XXX

BO_ 2353069822 FCSCLC: 8 Vector__XXX
 SG_ FlCllSstmCrrntLmtCmmndCr : 0|8@1+ (1,0) [0|250] "count" Vector__XXX
 SG_ FlCllSstmCrrntLmtCmmndCntr : 8|4@1+ (1,0) [0|15] "" Vector__XXX
 SG_ FlCllSstmNtCrrntMxmmLmtCmmnd : 16|16@1+ (0.00390625,-125) [0|125.99609375] "%" Vector__XXX
 SG_ FlCllSstmNtCrrntMnmmLmtCmmnd : 32|16@1+ (0.00390625,-125) [0|125.99609375] "%" Vector__XXX

BO_ 2554461950 HSSCC: 8 Vector__XXX
 SG_ HdrgnStrgSstmCntrlCmmndCr : 0|8@1+ (1,0) [0|250] "count" Vector__XXX
 SG_ HdrgnStrgSstmCntrlCmmndCntr : 8|4@1+ (1,0) [0|15] "" Vector__XXX
 SG_ HydrogenSupplyRequest : 12|2@1+ (1,0) [0|3] "" Vector__XXX

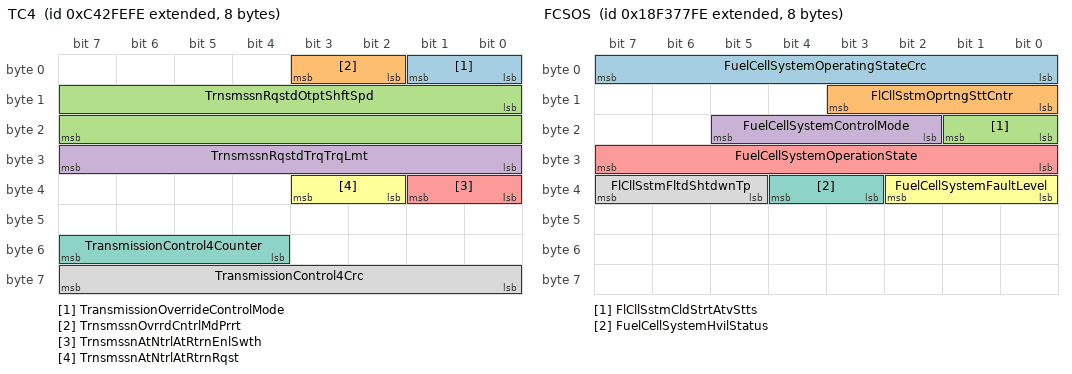
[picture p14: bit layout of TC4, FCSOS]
BO_ 2353200894 TC4: 8 Vector__XXX
 SG_ TransmissionOverrideControlMode : 0|2@1+ (1,0) [0|3] "" Vector__XXX
 SG_ TrnsmssnOvrrdCntrlMdPrrt : 2|2@1+ (1,0) [0|3] "" Vector__XXX
 SG_ TrnsmssnRqstdOtptShftSpd : 8|16@1+ (0.25,-8031.75) [-8031.375|8031.75] "rpm" Vector__XXX
 SG_ TrnsmssnRqstdTrqTrqLmt : 24|8@1+ (1,-125) [-125|125] "%" Vector__XXX
 SG_ TrnsmssnAtNtrlAtRtrnEnlSwth : 32|2@1+ (1,0) [0|3] "" Vector__XXX
 SG_ TrnsmssnAtNtrlAtRtrnRqst : 34|2@1+ (1,0) [0|3] "" Vector__XXX
 SG_ TransmissionControl4Counter : 52|4@1+ (1,0) [0|15] "" Vector__XXX
 SG_ TransmissionControl4Crc : 56|8@1+ (1,0) [0|250] "count" Vector__XXX

BO_ 2554789630 APISEL: 8 Vector__XXX
 SG_ SelectedEvApiId : 0|8@1+ (1,0) [0|250] "count" Vector__XXX
 SG_ SelectedEvApiManufacturerId : 8|12@1+ (1,0) [0|4015] "count" Vector__XXX
 SG_ SelectedEvApiDeviceRole : 20|4@1+ (1,0) [0|15] "" Vector__XXX
 SG_ SelectedEvApiMajorVersion : 24|8@1+ (1,0) [0|250] "count" Vector__XXX
 SG_ SelectedEvApiMinorVersion : 32|8@1+ (1,0) [0|250] "count" Vector__XXX

BO_ 2364574206 MG1IS3: 8 Vector__XXX
 SG_ MtrGnrtr1InvrtrCntrlStts3Cr : 0|8@1+ (1,0) [0|250] "count" Vector__XXX
 SG_ MtrGnrtr1InvrtrCntrlStts3Cntr : 8|4@1+ (1,0) [0|15] "" Vector__XXX
 SG_ MotorGenerator1MotorAngle : 16|16@1+ (0.0078125,0) [0|359.9921875] "deg" Vector__XXX

BO_ 2364574462 MG2IS3: 8 Vector__XXX
 SG_ MtrGnrtr2InvrtrCntrlStts3Cr : 0|8@1+ (1,0) [0|250] "count" Vector__XXX
 SG_ MtrGnrtr2InvrtrCntrlStts3Cntr : 8|4@1+ (1,0) [0|15] "" Vector__XXX
 SG_ MotorGenerator2MotorAngle : 16|16@1+ (0.0078125,0) [0|359.9921875] "deg" Vector__XXX

BO_ 2364574718 MG3IS3: 8 Vector__XXX
 SG_ MtrGnrtr3InvrtrCntrlStts3Cr : 0|8@1+ (1,0) [0|250] "count" Vector__XXX
 SG_ MtrGnrtr3InvrtrCntrlStts3Cntr : 8|4@1+ (1,0) [0|15] "" Vector__XXX
 SG_ MotorGenerator3MotorAngle : 16|16@1+ (0.0078125,0) [0|359.9921875] "deg" Vector__XXX

BO_ 2364574974 MG4IS3: 8 Vector__XXX
 SG_ MtrGnrtr4InvrtrCntrlStts3Cr : 0|8@1+ (1,0) [0|250] "count" Vector__XXX
 SG_ MtrGnrtr4InvrtrCntrlStts3Cntr : 8|4@1+ (1,0) [0|15] "" Vector__XXX
 SG_ MotorGenerator4MotorAngle : 16|16@1+ (0.0078125,0) [0|359.9921875] "deg" Vector__XXX

BO_ 2364575230 MG5IS3: 8 Vector__XXX
 SG_ MtrGnrtr5InvrtrCntrlStts3Cr : 0|8@1+ (1,0) [0|250] "count" Vector__XXX
 SG_ MtrGnrtr5InvrtrCntrlStts3Cntr : 8|4@1+ (1,0) [0|15] "" Vector__XXX
 SG_ MotorGenerator5MotorAngle : 16|16@1+ (0.0078125,0) [0|359.9921875] "deg" Vector__XXX

BO_ 2364575486 MG6IS3: 8 Vector__XXX
 SG_ MtrGnrtr6InvrtrCntrlStts3Cr : 0|8@1+ (1,0) [0|250] "count" Vector__XXX
 SG_ MtrGnrtr6InvrtrCntrlStts3Cntr : 8|4@1+ (1,0) [0|15] "" Vector__XXX
 SG_ MotorGenerator6MotorAngle : 16|16@1+ (0.0078125,0) [0|359.9921875] "deg" Vector__XXX

BO_ 2364764670 FCSCI: 8 Vector__XXX
 SG_ FlCllSstmOprtngInfrmtnCr : 0|8@1+ (1,0) [0|250] "count" Vector__XXX
 SG_ FlCllSstmOprtngInfrmtnCntr : 8|4@1+ (1,0) [0|15] "" Vector__XXX
 SG_ FuelCellSystemNetPower : 16|16@1+ (0.00390625,-125) [-125|125.99609375] "%" Vector__XXX
 SG_ FuelCellSystemNetCurrent : 32|16@1+ (0.00390625,-125) [-125|125.99609375] "%" Vector__XXX
 SG_ FuelCellSystemVoltage : 48|16@1+ (0.00390625,-125) [-125|125.99609375] "%" Vector__XXX

BO_ 2364764926 FCSMNPI: 8 Vector__XXX
 SG_ FlCllSstmMnmmPwrInfrmtnCr : 0|8@1+ (1,0) [0|250] "count" Vector__XXX
 SG_ FlCllSstmMnmmPwrInfrmtnCntr : 8|4@1+ (1,0) [0|15] "" Vector__XXX
 SG_ FlCllSstmAtlMnmmAvllNtPwr : 16|16@1+ (0.00390625,-125) [-125|125.99609375] "%" Vector__XXX
 SG_ FlCllSstmIntrnlMnmmAvllNtPwr : 32|16@1+ (0.00390625,-125) [-125|125.99609375] "%" Vector__XXX
 SG_ FCSstAtMAvNtPwSAddss : 48|8@1+ (1,0) [0|250] "sourceadr" Vector__XXX

BO_ 2364765182 FCSMXPI: 8 Vector__XXX
 SG_ FlCllSstmMxmmPwrInfrmtnCr : 0|8@1+ (1,0) [0|250] "count" Vector__XXX
 SG_ FlCllSstmMxmmPwrInfrmtnCntr : 8|4@1+ (1,0) [0|15] "" Vector__XXX
 SG_ FlCllSstmAtlMxmmAvllNtPwr : 16|16@1+ (0.00390625,-125) [-125|125.99609375] "%" Vector__XXX
 SG_ FlCllSstmIntrnlMxmmAvllNtPwr : 32|16@1+ (0.00390625,-125) [-125|125.99609375] "%" Vector__XXX
 SG_ FCSstAtMxAvNtPwSAddss : 48|8@1+ (1,0) [0|250] "sourceadr" Vector__XXX

BO_ 2364765438 FCSMNCI: 8 Vector__XXX
 SG_ FlCllSstmMnmmCrrntInfrmtnCr : 0|8@1+ (1,0) [0|250] "count" Vector__XXX
 SG_ FlCllSstmMnmmCrrntInfrmtnCntr : 8|4@1+ (1,0) [0|15] "" Vector__XXX
 SG_ FlCllSstmAtlMnmmAvllNtCrrnt : 16|16@1+ (0.00390625,-125) [-125|125.99609375] "%" Vector__XXX
 SG_ FlCllSstmIntrnlMnmmAvllNtCrrnt : 32|16@1+ (0.00390625,-125) [-125|125.99609375] "%" Vector__XXX
 SG_ FCSstAtMAvNtCtSAddss : 48|8@1+ (1,0) [0|250] "sourceadr" Vector__XXX

BO_ 2364765694 FCSMXCI: 8 Vector__XXX
 SG_ FlCllSstmMxmmCrrntInfrmtnCr : 0|8@1+ (1,0) [0|250] "count" Vector__XXX
 SG_ FlCllSstmMxmmCrrntInfrmtnCntr : 8|4@1+ (1,0) [0|15] "" Vector__XXX
 SG_ FlCllSstmAtlMxmmAvllNtCrrnt : 16|16@1+ (0.00390625,-125) [-125|125.99609375] "%" Vector__XXX
 SG_ FlCllSstmIntrnlMxmmAvllNtCrrnt : 32|16@1+ (0.00390625,-125) [-125|125.99609375] "%" Vector__XXX
 SG_ FCSstAtMxAvNtCtSAddss : 48|8@1+ (1,0) [0|250] "sourceadr" Vector__XXX

BO_ 2566092542 HSSI: 8 Vector__XXX
 SG_ HdrgnStrgSstmInfrmtnCr : 0|8@1+ (1,0) [0|250] "count" Vector__XXX
 SG_ HdrgnStrgSstmInfrmtnCntr : 8|4@1+ (1,0) [0|15] "" Vector__XXX
 SG_ HydrogenSupplyActiveStatus : 16|2@1+ (1,0) [0|3] "" Vector__XXX

BO_ 2566092798 FCSOS: 8 Vector__XXX
 SG_ FuelCellSystemOperatingStateCrc : 0|8@1+ (1,0) [0|250] "count" Vector__XXX
 SG_ FlCllSstmOprtngSttCntr : 8|4@1+ (1,0) [0|15] "" Vector__XXX
 SG_ FlCllSstmCldStrtAtvStts : 16|2@1+ (1,0) [0|3] "" Vector__XXX
 SG_ FuelCellSystemControlMode : 18|4@1+ (1,0) [0|15] "" Vector__XXX
 SG_ FuelCellSystemOperationState : 24|8@1+ (1,0) [0|250] "" Vector__XXX
 SG_ FuelCellSystemFaultLevel : 32|3@1+ (1,0) [0|7] "" Vector__XXX
 SG_ FuelCellSystemHvilStatus : 35|2@1+ (1,0) [0|3] "" Vector__XXX
 SG_ FlCllSstmFltdShtdwnTp : 37|3@1+ (1,0) [0|7] "" Vector__XXX

BO_ 2566093054 FCSOR: 8 Vector__XXX
 SG_ FlCllSstmOprtnsRqstCr : 0|8@1+ (1,0) [0|250] "count" Vector__XXX
 SG_ FlCllSstmOprtnsRqstCntr : 8|4@1+ (1,0) [0|15] "" Vector__XXX
 SG_ FCSstHVtPwSppItCd : 16|2@1+ (1,0) [0|3] "" Vector__XXX

BO_ 2566093310 FCSI: 8 Vector__XXX
 SG_ FuelCellStackCurrent : 0|8@1+ (0.4,0) [0|100] "%" Vector__XXX
 SG_ FuelCellStackVoltage : 8|8@1+ (0.4,0) [0|100] "%" Vector__XXX

BO_ 2566093566 FCSCF1S2: 8 Vector__XXX
 SG_ FlCllSstmClntFn1Vltg : 0|16@1+ (0.05,0) [0|3212.75] "V" Vector__XXX
 SG_ FlCllSstmClntFn1Crrnt : 16|16@1+ (0.05,-1600) [-1600|1612.75] "A" Vector__XXX
 SG_ FlCllSstmClntFn1HvlStts : 32|2@1+ (1,0) [0|3] "" Vector__XXX
 SG_ FlCllSstmClntFn1PrntSpdStts : 34|2@1+ (1,0) [0|3] "" Vector__XXX
 SG_ FlCllSstmClntFn1PrntSpd : 40|8@1+ (0.5,0) [0|100] "%" Vector__XXX

BO_ 2566093822 FCSCF2S2: 8 Vector__XXX
 SG_ FlCllSstmClntFn2Vltg : 0|16@1+ (0.05,0) [0|3212.75] "V" Vector__XXX
 SG_ FlCllSstmClntFn2Crrnt : 16|16@1+ (0.05,-1600) [-1600|1612.75] "A" Vector__XXX
 SG_ FlCllSstmClntFn2HvlStts : 32|2@1+ (1,0) [0|3] "" Vector__XXX
 SG_ FlCllSstmClntFn2PrntSpdStts : 34|2@1+ (1,0) [0|3] "" Vector__XXX
 SG_ FlCllSstmClntFn2PrntSpd : 40|8@1+ (0.5,0) [0|100] "%" Vector__XXX

BO_ 2566094078 FCSCF3S2: 8 Vector__XXX
 SG_ FlCllSstmClntFn3Vltg : 0|16@1+ (0.05,0) [0|3212.75] "V" Vector__XXX
 SG_ FlCllSstmClntFn3Crrnt : 16|16@1+ (0.05,-1600) [-1600|1612.75] "A" Vector__XXX
 SG_ FlCllSstmClntFn3HvlStts : 32|2@1+ (1,0) [0|3] "" Vector__XXX
 SG_ FlCllSstmClntFn3PrntSpdStts : 34|2@1+ (1,0) [0|3] "" Vector__XXX
 SG_ FlCllSstmClntFn3PrntSpd : 40|8@1+ (0.5,0) [0|100] "%" Vector__XXX

BO_ 2566094334 FCSCF4S2: 8 Vector__XXX
 SG_ FlCllSstmClntFn4Vltg : 0|16@1+ (0.05,0) [0|3212.75] "V" Vector__XXX
 SG_ FlCllSstmClntFn4Crrnt : 16|16@1+ (0.05,-1600) [-1600|1612.75] "A" Vector__XXX
 SG_ FlCllSstmClntFn4HvlStts : 32|2@1+ (1,0) [0|3] "" Vector__XXX
 SG_ FlCllSstmClntFn4PrntSpdStts : 34|2@1+ (1,0) [0|3] "" Vector__XXX
 SG_ FlCllSstmClntFn4PrntSpd : 40|8@1+ (0.5,0) [0|100] "%" Vector__XXX

BO_ 2566094590 HVESSCP1S2: 8 Vector__XXX
 SG_ HvessCoolantPump1Voltage : 0|16@1+ (0.05,0) [0|3212.75] "V" Vector__XXX
 SG_ HvessCoolantPump1Current : 16|16@1+ (0.05,-1600) [-1600|1612.75] "A" Vector__XXX
 SG_ HvessCoolantPump1HvilStatus : 32|2@1+ (1,0) [0|3] "" Vector__XXX
 SG_ HvssClntPmp1PrntSpdStts : 34|2@1+ (1,0) [0|3] "" Vector__XXX
 SG_ HvessCoolantPump1PercentSpeed : 40|8@1+ (0.5,0) [0|100] "%" Vector__XXX

BO_ 2566094846 HVESSCP2S2: 8 Vector__XXX
 SG_ HvessCoolantPump2Voltage : 0|16@1+ (0.05,0) [0|3212.75] "V" Vector__XXX
 SG_ HvessCoolantPump2Current : 16|16@1+ (0.05,-1600) [-1600|1612.75] "A" Vector__XXX
 SG_ HvessCoolantPump2HvilStatus : 32|2@1+ (1,0) [0|3] "" Vector__XXX
 SG_ HvssClntPmp2PrntSpdStts : 34|2@1+ (1,0) [0|3] "" Vector__XXX
 SG_ HvessCoolantPump2PercentSpeed : 40|8@1+ (0.5,0) [0|100] "%" Vector__XXX

BO_ 2566511870 HVESSTCH1: 8 Vector__XXX
 SG_ HvssTMtSstC1CpssDsAstPss : 0|16@1+ (1,0) [0|64255] "kPa" Vector__XXX
 SG_ HvssTMtSstC1CpssStAstPss : 16|16@1+ (1,0) [0|64255] "kPa" Vector__XXX
 SG_ HvssTMtSstC1OttCtTpt : 32|16@1+ (0.03125,-273) [-273|1734.96875] "degC" Vector__XXX
 SG_ HvssTMtSstC1CVvPst : 48|8@1+ (0.5,0) [0|125] "%" Vector__XXX

BO_ 2566512126 HVESSTCH2: 8 Vector__XXX
 SG_ HvssTMtSstC2CpssDsAstPss : 0|16@1+ (1,0) [0|64255] "kPa" Vector__XXX
 SG_ HvssTMtSstC2CpssStAstPss : 16|16@1+ (1,0) [0|64255] "kPa" Vector__XXX
 SG_ HvssTMtSstC2OttCtTpt : 32|16@1+ (0.03125,-273) [-273|1734.96875] "degC" Vector__XXX
 SG_ HvssTMtSstC2CVvPst : 48|8@1+ (0.5,0) [0|125] "%" Vector__XXX

BO_ 2566512382 HVESSTCH3: 8 Vector__XXX
 SG_ HvssTMtSstC3CpssDsAstPss : 0|16@1+ (1,0) [0|64255] "kPa" Vector__XXX
 SG_ HvssTMtSstC3CpssStAstPss : 16|16@1+ (1,0) [0|64255] "kPa" Vector__XXX
 SG_ HvssTMtSstC3OttCtTpt : 32|16@1+ (0.03125,-273) [-273|1734.96875] "degC" Vector__XXX
 SG_ HvssTMtSstC3CVvPst : 48|8@1+ (0.5,0) [0|125] "%" Vector__XXX

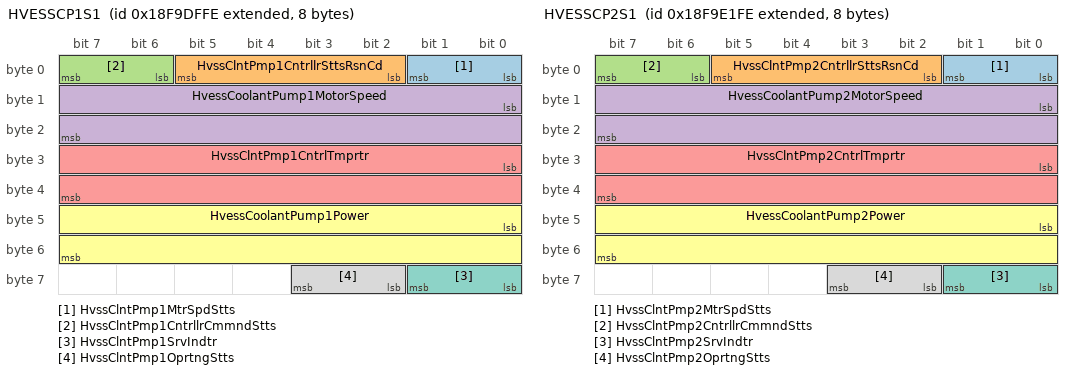
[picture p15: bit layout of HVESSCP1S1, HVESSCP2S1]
BO_ 2566512638 HVESSCP1S1: 8 Vector__XXX
 SG_ HvssClntPmp1MtrSpdStts : 0|2@1+ (1,0) [0|3] "" Vector__XXX
 SG_ HvssClntPmp1CntrllrSttsRsnCd : 2|4@1+ (1,0) [0|15] "" Vector__XXX
 SG_ HvssClntPmp1CntrllrCmmndStts : 6|2@1+ (1,0) [0|3] "" Vector__XXX
 SG_ HvessCoolantPump1MotorSpeed : 8|16@1+ (0.5,0) [0|32127.5] "rpm" Vector__XXX
 SG_ HvssClntPmp1CntrlTmprtr : 24|16@1+ (0.03125,-273) [-273|1734.96875] "degC" Vector__XXX
 SG_ HvessCoolantPump1Power : 40|16@1+ (0.5,0) [0|32127.5] "W" Vector__XXX
 SG_ HvssClntPmp1SrvIndtr : 56|2@1+ (1,0) [0|3] "" Vector__XXX
 SG_ HvssClntPmp1OprtngStts : 58|2@1+ (1,0) [0|3] "" Vector__XXX

BO_ 2566512894 HVESSCP1C: 8 Vector__XXX
 SG_ HvessCoolantPump1EnableCommand : 0|2@1+ (1,0) [0|3] "" Vector__XXX
 SG_ HvessCoolantPump1PowerHold : 2|2@1+ (1,0) [0|3] "" Vector__XXX
 SG_ HvessCoolantPump1SpeedCommand : 8|16@1+ (0.5,0) [0|32127.5] "rpm" Vector__XXX
 SG_ HvssClntPmp1PrntSpdCmmnd : 24|8@1+ (0.5,0) [0|100] "%" Vector__XXX
 SG_ HvssCtPp1CdEdddIttSppt : 50|2@1+ (1,0) [0|3] "" Vector__XXX
 SG_ HvessCoolantPump1CommandCounter : 52|4@1+ (1,0) [0|15] "count" Vector__XXX
 SG_ HvessCoolantPump1CommandCrc : 56|8@1+ (1,0) [0|250] "count" Vector__XXX

BO_ 2566513150 HVESSCP2S1: 8 Vector__XXX
 SG_ HvssClntPmp2MtrSpdStts : 0|2@1+ (1,0) [0|3] "" Vector__XXX
 SG_ HvssClntPmp2CntrllrSttsRsnCd : 2|4@1+ (1,0) [0|15] "" Vector__XXX
 SG_ HvssClntPmp2CntrllrCmmndStts : 6|2@1+ (1,0) [0|3] "" Vector__XXX
 SG_ HvessCoolantPump2MotorSpeed : 8|16@1+ (0.5,0) [0|32127.5] "rpm" Vector__XXX
 SG_ HvssClntPmp2CntrlTmprtr : 24|16@1+ (0.03125,-273) [-273|1734.96875] "degC" Vector__XXX
 SG_ HvessCoolantPump2Power : 40|16@1+ (0.5,0) [0|32127.5] "W" Vector__XXX
 SG_ HvssClntPmp2SrvIndtr : 56|2@1+ (1,0) [0|3] "" Vector__XXX
 SG_ HvssClntPmp2OprtngStts : 58|2@1+ (1,0) [0|3] "" Vector__XXX

BO_ 2566513406 HVESSCP2C: 8 Vector__XXX
 SG_ HvessCoolantPump2EnableCommand : 0|2@1+ (1,0) [0|3] "" Vector__XXX
 SG_ HvessCoolantPump2PowerHold : 2|2@1+ (1,0) [0|3] "" Vector__XXX
 SG_ HvessCoolantPump2SpeedCommand : 8|16@1+ (0.5,0) [0|32127.5] "rpm" Vector__XXX
 SG_ HvssClntPmp2PrntSpdCmmnd : 24|8@1+ (0.5,0) [0|100] "%" Vector__XXX
 SG_ HvssCtPp2CdEdddIttSppt : 50|2@1+ (1,0) [0|3] "" Vector__XXX
 SG_ HvessCoolantPump2CommandCounter : 52|4@1+ (1,0) [0|15] "count" Vector__XXX
 SG_ HvessCoolantPump2CommandCrc : 56|8@1+ (1,0) [0|250] "count" Vector__XXX

BO_ 2365187070 H2SNSINF: 8 Vector__XXX
 SG_ HydrogenInformationCrc : 0|8@1+ (1,0) [0|250] "count" Vector__XXX
 SG_ HydrogenInformationCounter : 8|4@1+ (1,0) [0|15] "" Vector__XXX
 SG_ HydrogenConcentration : 16|8@1+ (500,0) [0|125000] "ppm" Vector__XXX
 SG_ HdrgnCnntrtnPrlmnrFm : 24|5@1+ (1,0) [0|31] "" Vector__XXX

BO_ 2566514174 OIVSI1: 8 Vector__XXX
 SG_ OprtrIndmntVhlSpdDrt : 0|16@1+ (0.00390625,0) [0|250.99609375] "km/h" Vector__XXX
 SG_ OprtrIndmntNxtVhlSpdDrt : 16|16@1+ (0.00390625,0) [0|250.99609375] "km/h" Vector__XXX
 SG_ OprtrIndmntTmTNxtVhlSpdDrt : 32|16@1+ (10,0) [0|642550] "s" Vector__XXX

BO_ 2566514942 EPTDI: 8 Vector__XXX
 SG_ EngineProtectionTorqueReduction : 40|8@1+ (1,-125) [0|100] "%" Vector__XXX

BO_ 2566515198 ASI7: 8 Vector__XXX
 SG_ AttttDsExstFdCtCsptRt : 0|16@1+ (0.05,0) [0|3212.75] "l/h" Vector__XXX
 SG_ AttttDsExstFdPvsCsptRt : 16|16@1+ (0.05,0) [0|3212.75] "l/h" Vector__XXX

BO_ 2633624318 J20123B: 10 Vector__XXX
 SG_ NumberOfJ20123ByteDtcs : 0|8@1+ (1,0) [0|250] "count" Vector__XXX
 SG_ J20123ByteDtcOccurrenceCount : 72|7@1+ (1,0) [0|126] "count" Vector__XXX
 SG_ J20123ByteDtcStatus : 79|1@1+ (1,0) [0|1] "" Vector__XXX
 SG_ J20123ByteDtcBaseCode : 8|40@1+ (1,0) [0|255] "" Vector__XXX
 SG_ J20123ByteDtcDelimiter : 48|8@1+ (1,0) [0|250] "" Vector__XXX
 SG_ J20123ByteDtcFailureType : 56|16@1+ (1,0) [0|255] "" Vector__XXX

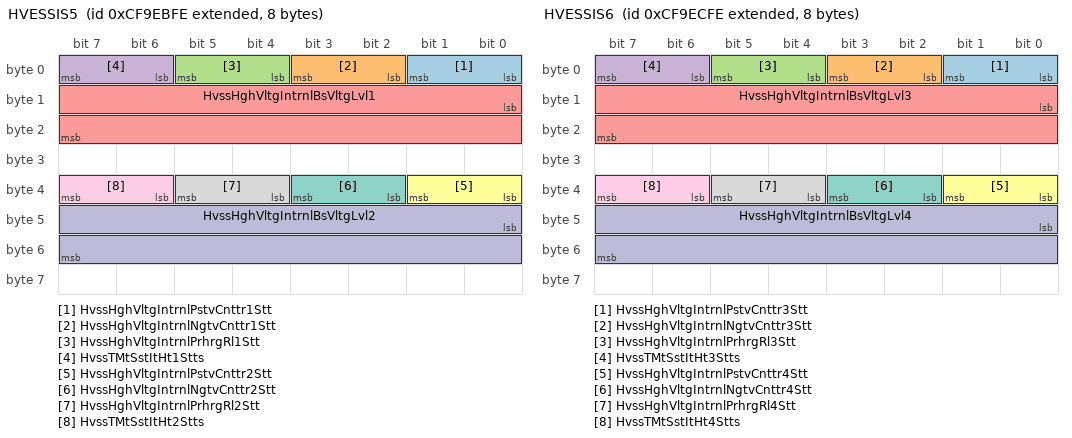
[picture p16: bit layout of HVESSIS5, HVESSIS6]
BO_ 2365189118 HVESSIS5: 8 Vector__XXX
 SG_ HvssHghVltgIntrnlPstvCnttr1Stt : 0|2@1+ (1,0) [0|3] "" Vector__XXX
 SG_ HvssHghVltgIntrnlNgtvCnttr1Stt : 2|2@1+ (1,0) [0|3] "" Vector__XXX
 SG_ HvssHghVltgIntrnlPrhrgRl1Stt : 4|2@1+ (1,0) [0|3] "" Vector__XXX
 SG_ HvssTMtSstItHt1Stts : 6|2@1+ (1,0) [0|3] "" Vector__XXX
 SG_ HvssHghVltgIntrnlBsVltgLvl1 : 8|16@1+ (0.05,0) [0|3212.75] "V" Vector__XXX
 SG_ HvssHghVltgIntrnlPstvCnttr2Stt : 32|2@1+ (1,0) [0|3] "" Vector__XXX
 SG_ HvssHghVltgIntrnlNgtvCnttr2Stt : 34|2@1+ (1,0) [0|3] "" Vector__XXX
 SG_ HvssHghVltgIntrnlPrhrgRl2Stt : 36|2@1+ (1,0) [0|3] "" Vector__XXX
 SG_ HvssTMtSstItHt2Stts : 38|2@1+ (1,0) [0|3] "" Vector__XXX
 SG_ HvssHghVltgIntrnlBsVltgLvl2 : 40|16@1+ (0.05,0) [0|3212.75] "V" Vector__XXX

BO_ 2365189374 HVESSIS6: 8 Vector__XXX
 SG_ HvssHghVltgIntrnlPstvCnttr3Stt : 0|2@1+ (1,0) [0|3] "" Vector__XXX
 SG_ HvssHghVltgIntrnlNgtvCnttr3Stt : 2|2@1+ (1,0) [0|3] "" Vector__XXX
 SG_ HvssHghVltgIntrnlPrhrgRl3Stt : 4|2@1+ (1,0) [0|3] "" Vector__XXX
 SG_ HvssTMtSstItHt3Stts : 6|2@1+ (1,0) [0|3] "" Vector__XXX
 SG_ HvssHghVltgIntrnlBsVltgLvl3 : 8|16@1+ (0.05,0) [0|3212.75] "V" Vector__XXX
 SG_ HvssHghVltgIntrnlPstvCnttr4Stt : 32|2@1+ (1,0) [0|3] "" Vector__XXX
 SG_ HvssHghVltgIntrnlNgtvCnttr4Stt : 34|2@1+ (1,0) [0|3] "" Vector__XXX
 SG_ HvssHghVltgIntrnlPrhrgRl4Stt : 36|2@1+ (1,0) [0|3] "" Vector__XXX
 SG_ HvssTMtSstItHt4Stts : 38|2@1+ (1,0) [0|3] "" Vector__XXX
 SG_ HvssHghVltgIntrnlBsVltgLvl4 : 40|16@1+ (0.05,0) [0|3212.75] "V" Vector__XXX

BO_ 2365189630 HVESSIS7: 8 Vector__XXX
 SG_ HvssNmrOfIntrnlCrtsRd : 0|8@1+ (1,0) [0|250] "count" Vector__XXX

BO_ 2566516478 ECAIDA1: 8 Vector__XXX
 SG_ EngnClndr1AvrgIgntnDlAngl : 0|16@1+ (0.0078125,-200) [-200|301.9921875] "deg" Vector__XXX
 SG_ EngnClndr2AvrgIgntnDlAngl : 16|16@1+ (0.0078125,-200) [-200|301.9921875] "deg" Vector__XXX
 SG_ EngnClndr3AvrgIgntnDlAngl : 32|16@1+ (0.0078125,-200) [-200|301.9921875] "deg" Vector__XXX
 SG_ EngnClndr4AvrgIgntnDlAngl : 48|16@1+ (0.0078125,-200) [-200|301.9921875] "deg" Vector__XXX

BO_ 2566516734 ECAIDA2: 8 Vector__XXX
 SG_ EngnClndr5AvrgIgntnDlAngl : 0|16@1+ (0.0078125,-200) [-200|301.9921875] "deg" Vector__XXX
 SG_ EngnClndr6AvrgIgntnDlAngl : 16|16@1+ (0.0078125,-200) [-200|301.9921875] "deg" Vector__XXX
 SG_ EngnClndr7AvrgIgntnDlAngl : 32|16@1+ (0.0078125,-200) [-200|301.9921875] "deg" Vector__XXX
 SG_ EngnClndr8AvrgIgntnDlAngl : 48|16@1+ (0.0078125,-200) [-200|301.9921875] "deg" Vector__XXX

BO_ 2566516990 ECAIDA3: 8 Vector__XXX
 SG_ EngnClndr9AvrgIgntnDlAngl : 0|16@1+ (0.0078125,-200) [-200|301.9921875] "deg" Vector__XXX
 SG_ EngnClndr10AvrgIgntnDlAngl : 16|16@1+ (0.0078125,-200) [-200|301.9921875] "deg" Vector__XXX
 SG_ EngnClndr11AvrgIgntnDlAngl : 32|16@1+ (0.0078125,-200) [-200|301.9921875] "deg" Vector__XXX
 SG_ EngnClndr12AvrgIgntnDlAngl : 48|16@1+ (0.0078125,-200) [-200|301.9921875] "deg" Vector__XXX

BO_ 2566517246 ECAIDA4: 8 Vector__XXX
 SG_ EngnClndr13AvrgIgntnDlAngl : 0|16@1+ (0.0078125,-200) [-200|301.9921875] "deg" Vector__XXX
 SG_ EngnClndr14AvrgIgntnDlAngl : 16|16@1+ (0.0078125,-200) [-200|301.9921875] "deg" Vector__XXX
 SG_ EngnClndr15AvrgIgntnDlAngl : 32|16@1+ (0.0078125,-200) [-200|301.9921875] "deg" Vector__XXX
 SG_ EngnClndr16AvrgIgntnDlAngl : 48|16@1+ (0.0078125,-200) [-200|301.9921875] "deg" Vector__XXX

BO_ 2566517502 ECAIDA5: 8 Vector__XXX
 SG_ EngnClndr17AvrgIgntnDlAngl : 0|16@1+ (0.0078125,-200) [-200|301.9921875] "deg" Vector__XXX
 SG_ EngnClndr18AvrgIgntnDlAngl : 16|16@1+ (0.0078125,-200) [-200|301.9921875] "deg" Vector__XXX
 SG_ EngnClndr19AvrgIgntnDlAngl : 32|16@1+ (0.0078125,-200) [-200|301.9921875] "deg" Vector__XXX
 SG_ EngnClndr20AvrgIgntnDlAngl : 48|16@1+ (0.0078125,-200) [-200|301.9921875] "deg" Vector__XXX

BO_ 2566517758 EIMEPI1: 8 Vector__XXX
 SG_ ECd1IdtdMEtvPssPwB : 0|8@1+ (1,0) [0|250] "%" Vector__XXX
 SG_ ECd2IdtdMEtvPssPwB : 8|8@1+ (1,0) [0|250] "%" Vector__XXX
 SG_ ECd3IdtdMEtvPssPwB : 16|8@1+ (1,0) [0|250] "%" Vector__XXX
 SG_ ECd4IdtdMEtvPssPwB : 24|8@1+ (1,0) [0|250] "%" Vector__XXX
 SG_ ECd5IdtdMEtvPssPwB : 32|8@1+ (1,0) [0|250] "%" Vector__XXX
 SG_ ECd6IdtdMEtvPssPwB : 40|8@1+ (1,0) [0|250] "%" Vector__XXX
 SG_ ECd7IdtdMEtvPssPwB : 48|8@1+ (1,0) [0|250] "%" Vector__XXX
 SG_ ECd8IdtdMEtvPssPwB : 56|8@1+ (1,0) [0|250] "%" Vector__XXX

BO_ 2566518014 EIMEPI2: 8 Vector__XXX
 SG_ ECd9IdtdMEtvPssPwB : 0|8@1+ (1,0) [0|250] "%" Vector__XXX
 SG_ ECd10IdtdMEtvPssPwB : 8|8@1+ (1,0) [0|250] "%" Vector__XXX
 SG_ ECd11IdtdMEtvPssPwB : 16|8@1+ (1,0) [0|250] "%" Vector__XXX
 SG_ ECd12IdtdMEtvPssPwB : 24|8@1+ (1,0) [0|250] "%" Vector__XXX
 SG_ ECd13IdtdMEtvPssPwB : 32|8@1+ (1,0) [0|250] "%" Vector__XXX
 SG_ ECd14IdtdMEtvPssPwB : 40|8@1+ (1,0) [0|250] "%" Vector__XXX
 SG_ ECd15IdtdMEtvPssPwB : 48|8@1+ (1,0) [0|250] "%" Vector__XXX
 SG_ ECd16IdtdMEtvPssPwB : 56|8@1+ (1,0) [0|250] "%" Vector__XXX

BO_ 2566518270 EIMEPI3: 8 Vector__XXX
 SG_ ECd17IdtdMEtvPssPwB : 0|8@1+ (1,0) [0|250] "%" Vector__XXX
 SG_ ECd18IdtdMEtvPssPwB : 8|8@1+ (1,0) [0|250] "%" Vector__XXX
 SG_ ECd19IdtdMEtvPssPwB : 16|8@1+ (1,0) [0|250] "%" Vector__XXX
 SG_ ECd20IdtdMEtvPssPwB : 24|8@1+ (1,0) [0|250] "%" Vector__XXX
 SG_ ECd21IdtdMEtvPssPwB : 32|8@1+ (1,0) [0|250] "%" Vector__XXX
 SG_ ECd22IdtdMEtvPssPwB : 40|8@1+ (1,0) [0|250] "%" Vector__XXX
 SG_ ECd23IdtdMEtvPssPwB : 48|8@1+ (1,0) [0|250] "%" Vector__XXX
 SG_ ECd24IdtdMEtvPssPwB : 56|8@1+ (1,0) [0|250] "%" Vector__XXX

BO_ 2566518526 FCSCF1C: 8 Vector__XXX
 SG_ FlCllSstmClntFn1EnlCmmnd : 0|2@1+ (1,0) [0|3] "" Vector__XXX
 SG_ FlCllSstmClntFn1PwrHld : 2|2@1+ (1,0) [0|3] "" Vector__XXX
 SG_ FlCllSstmClntFn1SpdCmmnd : 8|16@1+ (0.5,0) [0|32127.5] "rpm" Vector__XXX
 SG_ FlCllSstmClntFn1PrntSpdCmmnd : 24|8@1+ (0.5,0) [0|100] "%" Vector__XXX
 SG_ FCSstCtF1CdEdddIttSppt : 50|2@1+ (1,0) [0|3] "" Vector__XXX
 SG_ FlCllSstmClntFn1CmmndCntr : 52|4@1+ (1,0) [0|15] "count" Vector__XXX
 SG_ FlCllSstmClntFn1CmmndCr : 56|8@1+ (1,0) [0|250] "count" Vector__XXX

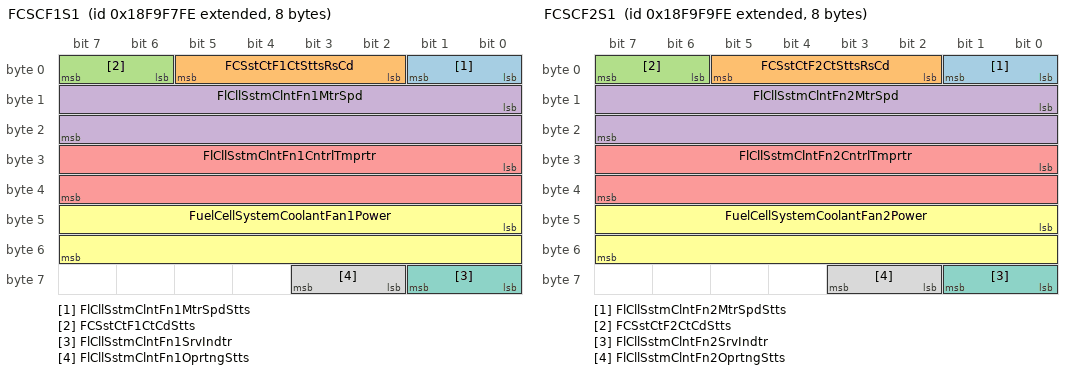
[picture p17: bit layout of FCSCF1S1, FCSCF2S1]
BO_ 2566518782 FCSCF1S1: 8 Vector__XXX
 SG_ FlCllSstmClntFn1MtrSpdStts : 0|2@1+ (1,0) [0|3] "" Vector__XXX
 SG_ FCSstCtF1CtSttsRsCd : 2|4@1+ (1,0) [0|15] "" Vector__XXX
 SG_ FCSstCtF1CtCdStts : 6|2@1+ (1,0) [0|3] "" Vector__XXX
 SG_ FlCllSstmClntFn1MtrSpd : 8|16@1+ (0.5,0) [0|32127.5] "rpm" Vector__XXX
 SG_ FlCllSstmClntFn1CntrlTmprtr : 24|16@1+ (0.03125,-273) [-273|1734.96875] "degC" Vector__XXX
 SG_ FuelCellSystemCoolantFan1Power : 40|16@1+ (0.5,0) [0|32127.5] "W" Vector__XXX
 SG_ FlCllSstmClntFn1SrvIndtr : 56|2@1+ (1,0) [0|3] "" Vector__XXX
 SG_ FlCllSstmClntFn1OprtngStts : 58|2@1+ (1,0) [0|3] "" Vector__XXX

BO_ 2566519038 FCSCF2C: 8 Vector__XXX
 SG_ FlCllSstmClntFn2EnlCmmnd : 0|2@1+ (1,0) [0|3] "" Vector__XXX
 SG_ FlCllSstmClntFn2PwrHld : 2|2@1+ (1,0) [0|3] "" Vector__XXX
 SG_ FlCllSstmClntFn2SpdCmmnd : 8|16@1+ (0.5,0) [0|32127.5] "rpm" Vector__XXX
 SG_ FlCllSstmClntFn2PrntSpdCmmnd : 24|8@1+ (0.5,0) [0|100] "%" Vector__XXX
 SG_ FCSstCtF2CdEdddIttSppt : 50|2@1+ (1,0) [0|3] "" Vector__XXX
 SG_ FlCllSstmClntFn2CmmndCntr : 52|4@1+ (1,0) [0|15] "count" Vector__XXX
 SG_ FlCllSstmClntFn2CmmndCr : 56|8@1+ (1,0) [0|250] "count" Vector__XXX

BO_ 2566519294 FCSCF2S1: 8 Vector__XXX
 SG_ FlCllSstmClntFn2MtrSpdStts : 0|2@1+ (1,0) [0|3] "" Vector__XXX
 SG_ FCSstCtF2CtSttsRsCd : 2|4@1+ (1,0) [0|15] "" Vector__XXX
 SG_ FCSstCtF2CtCdStts : 6|2@1+ (1,0) [0|3] "" Vector__XXX
 SG_ FlCllSstmClntFn2MtrSpd : 8|16@1+ (0.5,0) [0|32127.5] "rpm" Vector__XXX
 SG_ FlCllSstmClntFn2CntrlTmprtr : 24|16@1+ (0.03125,-273) [-273|1734.96875] "degC" Vector__XXX
 SG_ FuelCellSystemCoolantFan2Power : 40|16@1+ (0.5,0) [0|32127.5] "W" Vector__XXX
 SG_ FlCllSstmClntFn2SrvIndtr : 56|2@1+ (1,0) [0|3] "" Vector__XXX
 SG_ FlCllSstmClntFn2OprtngStts : 58|2@1+ (1,0) [0|3] "" Vector__XXX

BO_ 2566519550 FCSCF3C: 8 Vector__XXX
 SG_ FlCllSstmClntFn3EnlCmmnd : 0|2@1+ (1,0) [0|3] "" Vector__XXX
 SG_ FlCllSstmClntFn3PwrHld : 2|2@1+ (1,0) [0|3] "" Vector__XXX
 SG_ FlCllSstmClntFn3SpdCmmnd : 8|16@1+ (0.5,0) [0|32127.5] "rpm" Vector__XXX
 SG_ FlCllSstmClntFn3PrntSpdCmmnd : 24|8@1+ (0.5,0) [0|100] "%" Vector__XXX
 SG_ FCSstCtF3CdEdddIttSppt : 50|2@1+ (1,0) [0|3] "" Vector__XXX
 SG_ FlCllSstmClntFn3CmmndCntr : 52|4@1+ (1,0) [0|15] "count" Vector__XXX
 SG_ FlCllSstmClntFn3CmmndCr : 56|8@1+ (1,0) [0|250] "count" Vector__XXX

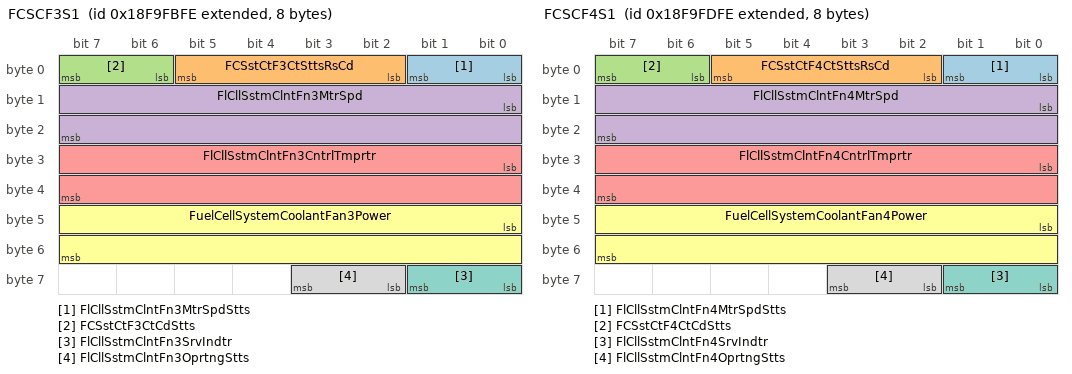
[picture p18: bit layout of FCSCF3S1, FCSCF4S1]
BO_ 2566519806 FCSCF3S1: 8 Vector__XXX
 SG_ FlCllSstmClntFn3MtrSpdStts : 0|2@1+ (1,0) [0|3] "" Vector__XXX
 SG_ FCSstCtF3CtSttsRsCd : 2|4@1+ (1,0) [0|15] "" Vector__XXX
 SG_ FCSstCtF3CtCdStts : 6|2@1+ (1,0) [0|3] "" Vector__XXX
 SG_ FlCllSstmClntFn3MtrSpd : 8|16@1+ (0.5,0) [0|32127.5] "rpm" Vector__XXX
 SG_ FlCllSstmClntFn3CntrlTmprtr : 24|16@1+ (0.03125,-273) [-273|1734.96875] "degC" Vector__XXX
 SG_ FuelCellSystemCoolantFan3Power : 40|16@1+ (0.5,0) [0|32127.5] "W" Vector__XXX
 SG_ FlCllSstmClntFn3SrvIndtr : 56|2@1+ (1,0) [0|3] "" Vector__XXX
 SG_ FlCllSstmClntFn3OprtngStts : 58|2@1+ (1,0) [0|3] "" Vector__XXX

BO_ 2566520062 FCSCF4C: 8 Vector__XXX
 SG_ FlCllSstmClntFn4EnlCmmnd : 0|2@1+ (1,0) [0|3] "" Vector__XXX
 SG_ FlCllSstmClntFn4PwrHld : 2|2@1+ (1,0) [0|3] "" Vector__XXX
 SG_ FlCllSstmClntFn4SpdCmmnd : 8|16@1+ (0.5,0) [0|32127.5] "rpm" Vector__XXX
 SG_ FlCllSstmClntFn4PrntSpdCmmnd : 24|8@1+ (0.5,0) [0|100] "%" Vector__XXX
 SG_ FCSstCtF4CdEdddIttSppt : 50|2@1+ (1,0) [0|3] "" Vector__XXX
 SG_ FlCllSstmClntFn4CmmndCntr : 52|4@1+ (1,0) [0|15] "count" Vector__XXX
 SG_ FlCllSstmClntFn4CmmndCr : 56|8@1+ (1,0) [0|250] "count" Vector__XXX

BO_ 2566520318 FCSCF4S1: 8 Vector__XXX
 SG_ FlCllSstmClntFn4MtrSpdStts : 0|2@1+ (1,0) [0|3] "" Vector__XXX
 SG_ FCSstCtF4CtSttsRsCd : 2|4@1+ (1,0) [0|15] "" Vector__XXX
 SG_ FCSstCtF4CtCdStts : 6|2@1+ (1,0) [0|3] "" Vector__XXX
 SG_ FlCllSstmClntFn4MtrSpd : 8|16@1+ (0.5,0) [0|32127.5] "rpm" Vector__XXX
 SG_ FlCllSstmClntFn4CntrlTmprtr : 24|16@1+ (0.03125,-273) [-273|1734.96875] "degC" Vector__XXX
 SG_ FuelCellSystemCoolantFan4Power : 40|16@1+ (0.5,0) [0|32127.5] "W" Vector__XXX
 SG_ FlCllSstmClntFn4SrvIndtr : 56|2@1+ (1,0) [0|3] "" Vector__XXX
 SG_ FlCllSstmClntFn4OprtngStts : 58|2@1+ (1,0) [0|3] "" Vector__XXX

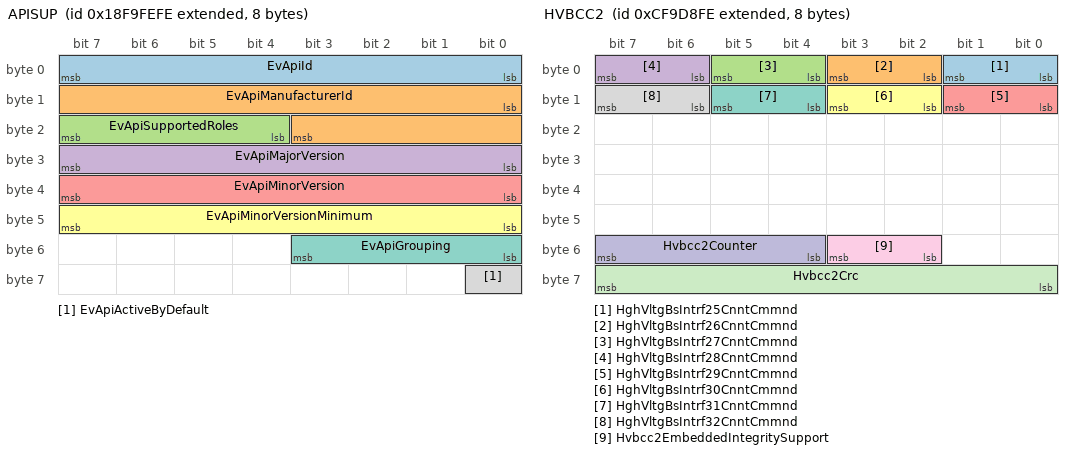
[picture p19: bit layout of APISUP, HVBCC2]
BO_ 2566520574 APISUP: 8 Vector__XXX
 SG_ EvApiId : 0|8@1+ (1,0) [0|250] "count" Vector__XXX
 SG_ EvApiManufacturerId : 8|12@1+ (1,0) [0|4015] "count" Vector__XXX
 SG_ EvApiSupportedRoles : 20|4@1+ (1,0) [0|15] "" Vector__XXX
 SG_ EvApiMajorVersion : 24|8@1+ (1,0) [0|250] "count" Vector__XXX
 SG_ EvApiMinorVersion : 32|8@1+ (1,0) [0|250] "count" Vector__XXX
 SG_ EvApiMinorVersionMinimum : 40|8@1+ (1,0) [0|250] "count" Vector__XXX
 SG_ EvApiGrouping : 48|4@1+ (1,0) [0|15] "" Vector__XXX
 SG_ EvApiActiveByDefault : 56|1@1+ (1,0) [0|1] "" Vector__XXX

BO_ 2566520830 FCSC: 8 Vector__XXX
 SG_ FuelCellSystemConfigurationCrc : 0|8@1+ (1,0) [0|250] "count" Vector__XXX
 SG_ FlCllSstmCnfgrtnCntr : 8|4@1+ (1,0) [0|15] "" Vector__XXX
 SG_ FuelCellSystemReferencePower : 16|16@1+ (0.05,0) [0|3212.75] "kW" Vector__XXX
 SG_ FuelCellSystemReferenceCurrent : 32|16@1+ (0.05,0) [0|3212.75] "A" Vector__XXX
 SG_ FuelCellSystemReferenceVoltage : 48|16@1+ (0.05,0) [0|3212.75] "V" Vector__XXX

BO_ 2566521086 FCSCI1: 8 Vector__XXX
 SG_ FlCllSstmClntInltTmprtrStpnt : 0|16@1+ (0.03125,-273) [-273|1734.96875] "degC" Vector__XXX
 SG_ FlCllSstmClntInltTmprtr : 16|16@1+ (0.03125,-273) [-273|1734.96875] "degC" Vector__XXX
 SG_ FlCllStkClntInltTmprtr : 32|8@1+ (1,-40) [-40|210] "degC" Vector__XXX
 SG_ FlCllStkClntOtltTmprtr : 40|8@1+ (1,-40) [-40|210] "degC" Vector__XXX

BO_ 2566521342 FCSCI2: 8 Vector__XXX
 SG_ FuelCellSystemCoolantLevel : 0|8@1+ (0.4,0) [0|100] "%" Vector__XXX
 SG_ FlCllStkInltClntAsltPrssr : 8|8@1+ (2,0) [0|500] "kPa" Vector__XXX
 SG_ FuelCellSystemCoolantFlowRate : 16|16@1+ (0.05,0) [0|3212.75] "l/h" Vector__XXX
 SG_ FuelCellStackCoolantFlowRate : 32|16@1+ (0.05,0) [0|3212.75] "l/h" Vector__XXX
 SG_ FlCllSstmClntCndtvt : 48|16@1+ (0.02,0) [0|1285.1] "micro Siemens/cm" Vector__XXX

BO_ 2566095102 HVESSFS2: 8 Vector__XXX
 SG_ HvessFanVoltage : 0|16@1+ (0.05,0) [0|3212.75] "V" Vector__XXX
 SG_ HvessFanCurrent : 16|16@1+ (0.05,-1600) [-1600|1612.75] "A" Vector__XXX
 SG_ HvessFanHvilStatus : 32|2@1+ (1,0) [0|3] "" Vector__XXX
 SG_ HvessFanStatus2Instance : 34|4@1+ (1,0) [0|15] "" Vector__XXX
 SG_ HvessFanPercentSpeedStatus : 38|2@1+ (1,0) [0|3] "" Vector__XXX
 SG_ HvessFanPercentSpeed : 40|8@1+ (0.5,0) [0|125] "%" Vector__XXX

BO_ 2566511614 EVSES2: 8 Vector__XXX
 SG_ EvseTempSensorType : 0|4@1+ (1,0) [0|15] "" Vector__XXX
 SG_ EvseConnectorTemperatureStatus : 4|2@1+ (1,0) [0|3] "" Vector__XXX
 SG_ EvChrgngInltCnntrTmprtr : 8|8@1+ (1,-40) [-40|210] "degC" Vector__XXX
 SG_ EvCItCtTptSsRsst : 16|24@1+ (1,0) [0|16449535] "ohm" Vector__XXX

BO_ 2566645502 HVESSFC: 8 Vector__XXX
 SG_ HvessFanEnableCommand : 0|2@1+ (1,0) [0|3] "" Vector__XXX
 SG_ HvessFanPowerHold : 2|2@1+ (1,0) [0|3] "" Vector__XXX
 SG_ HvessFanSpeedCommand : 8|16@1+ (0.5,0) [0|32127.5] "rpm" Vector__XXX
 SG_ HvessFanPercentSpeedCommand : 24|8@1+ (0.4,0) [0|100] "%" Vector__XXX
 SG_ HvessFanInstance1 : 32|1@1+ (1,0) [0|1] "" Vector__XXX
 SG_ HvessFanInstance2 : 33|1@1+ (1,0) [0|1] "" Vector__XXX
 SG_ HvessFanInstance3 : 34|1@1+ (1,0) [0|1] "" Vector__XXX
 SG_ HvessFanInstance4 : 35|1@1+ (1,0) [0|1] "" Vector__XXX
 SG_ HvessFanInstance5 : 36|1@1+ (1,0) [0|1] "" Vector__XXX
 SG_ HvessFanInstance6 : 37|1@1+ (1,0) [0|1] "" Vector__XXX
 SG_ HvessFanInstance7 : 38|1@1+ (1,0) [0|1] "" Vector__XXX
 SG_ HvessFanInstance8 : 39|1@1+ (1,0) [0|1] "" Vector__XXX
 SG_ HvessFanInstance9 : 40|1@1+ (1,0) [0|1] "" Vector__XXX
 SG_ HvessFanInstance10 : 41|1@1+ (1,0) [0|1] "" Vector__XXX
 SG_ HvessFanInstance11 : 42|1@1+ (1,0) [0|1] "" Vector__XXX
 SG_ HvessFanInstance12 : 43|1@1+ (1,0) [0|1] "" Vector__XXX
 SG_ HvessFanInstance13 : 44|1@1+ (1,0) [0|1] "" Vector__XXX
 SG_ HvessFanInstance14 : 45|1@1+ (1,0) [0|1] "" Vector__XXX
 SG_ HvessFanInstance15 : 46|1@1+ (1,0) [0|1] "" Vector__XXX
 SG_ HVtEStSstFCdsEdddIttSppt : 50|2@1+ (1,0) [0|3] "" Vector__XXX
 SG_ HghVltgEnrgStrgSstmFnCmmndsCntr : 52|4@1+ (1,0) [0|15] "count" Vector__XXX
 SG_ HghVltgEnrgStrgSstmFnCmmndsCr : 56|8@1+ (1,0) [0|250] "count" Vector__XXX

BO_ 2566504446 ENRI: 8 Vector__XXX
 SG_ TripEnrichmentPercentTime : 0|8@1+ (0.5,0) [0|125] "%" Vector__XXX
 SG_ TrpEnrhmntPrntTmDTAlrtrPdl : 8|8@1+ (0.5,0) [0|125] "%" Vector__XXX
 SG_ TrpEnrhmntPrntTmDTEngnPrttn : 16|8@1+ (0.5,0) [0|125] "%" Vector__XXX
 SG_ TpEtPtTDTAttttPtt : 24|8@1+ (0.5,0) [0|125] "%" Vector__XXX
 SG_ LifetimeEnrichmentPercentTime : 32|8@1+ (0.5,0) [0|125] "%" Vector__XXX
 SG_ LftmEnrhmntPrntTmDTAlrtrPdl : 40|8@1+ (0.5,0) [0|125] "%" Vector__XXX
 SG_ LftmEnrhmntPrntTmDTEngnPrttn : 48|8@1+ (0.5,0) [0|125] "%" Vector__XXX
 SG_ LtEtPtTDTAttttPtt : 56|8@1+ (0.5,0) [0|125] "%" Vector__XXX

BO_ 2566504702 FCSVLC: 8 Vector__XXX
 SG_ FcsvlcCrc : 0|8@1+ (1,0) [0|250] "count" Vector__XXX
 SG_ FcsvlcCounter : 8|4@1+ (1,0) [0|15] "" Vector__XXX
 SG_ FlCllSstmNmnlVltgCmmnd : 16|16@1+ (0.00390625,-125) [0|125.99609375] "%" Vector__XXX
 SG_ FlCllSstmMnmmOprtngVltgCmmnd : 32|16@1+ (0.00390625,-125) [0|125.99609375] "%" Vector__XXX
 SG_ FlCllSstmMxmmOprtngVltgCmmnd : 48|16@1+ (0.00390625,-125) [0|125.99609375] "%" Vector__XXX

BO_ 2566505470 AUXIO17: 8 Vector__XXX
 SG_ AuxiliaryIOChannel62 : 0|16@1+ (1,0) [0|64255] "count" Vector__XXX
 SG_ AuxiliaryIOChannel61 : 16|16@1+ (1,0) [0|64255] "count" Vector__XXX
 SG_ AuxiliaryIOChannel60 : 32|16@1+ (1,0) [0|64255] "count" Vector__XXX
 SG_ AuxiliaryIOChannel59 : 48|16@1+ (1,0) [0|64255] "count" Vector__XXX

BO_ 2566505726 AUXIO16: 8 Vector__XXX
 SG_ AuxiliaryIOChannel58 : 0|16@1+ (1,0) [0|64255] "count" Vector__XXX
 SG_ AuxiliaryIOChannel57 : 16|16@1+ (1,0) [0|64255] "count" Vector__XXX
 SG_ AuxiliaryIOChannel56 : 32|16@1+ (1,0) [0|64255] "count" Vector__XXX
 SG_ AuxiliaryIOChannel55 : 48|16@1+ (1,0) [0|64255] "count" Vector__XXX

BO_ 2566505982 AUXIO15: 8 Vector__XXX
 SG_ AuxiliaryIOChannel54 : 0|16@1+ (1,0) [0|64255] "count" Vector__XXX
 SG_ AuxiliaryIOChannel53 : 16|16@1+ (1,0) [0|64255] "count" Vector__XXX
 SG_ AuxiliaryIOChannel52 : 32|16@1+ (1,0) [0|64255] "count" Vector__XXX
 SG_ AuxiliaryIOChannel51 : 48|16@1+ (1,0) [0|64255] "count" Vector__XXX

BO_ 2566506238 AUXIO14: 8 Vector__XXX
 SG_ AuxiliaryIOChannel50 : 0|16@1+ (1,0) [0|64255] "count" Vector__XXX
 SG_ AuxiliaryIOChannel49 : 16|16@1+ (1,0) [0|64255] "count" Vector__XXX
 SG_ AuxiliaryIOChannel48 : 32|16@1+ (1,0) [0|64255] "count" Vector__XXX
 SG_ AuxiliaryIOChannel47 : 48|16@1+ (1,0) [0|64255] "count" Vector__XXX

BO_ 2566506494 AUXIO13: 8 Vector__XXX
 SG_ AuxiliaryIOChannel46 : 0|16@1+ (1,0) [0|64255] "count" Vector__XXX
 SG_ AuxiliaryIOChannel45 : 16|16@1+ (1,0) [0|64255] "count" Vector__XXX
 SG_ AuxiliaryIOChannel44 : 32|16@1+ (1,0) [0|64255] "count" Vector__XXX
 SG_ AuxiliaryIOChannel43 : 48|16@1+ (1,0) [0|64255] "count" Vector__XXX

BO_ 2566506750 AUXIO12: 8 Vector__XXX
 SG_ AuxiliaryIOChannel42 : 0|16@1+ (1,0) [0|64255] "count" Vector__XXX
 SG_ AuxiliaryIOChannel41 : 16|16@1+ (1,0) [0|64255] "count" Vector__XXX
 SG_ AuxiliaryIOChannel40 : 32|16@1+ (1,0) [0|64255] "count" Vector__XXX
 SG_ AuxiliaryIOChannel39 : 48|16@1+ (1,0) [0|64255] "count" Vector__XXX

BO_ 2566507006 AUXIO11: 8 Vector__XXX
 SG_ AuxiliaryIOChannel38 : 0|16@1+ (1,0) [0|64255] "count" Vector__XXX
 SG_ AuxiliaryIOChannel37 : 16|16@1+ (1,0) [0|64255] "count" Vector__XXX
 SG_ AuxiliaryIOChannel36 : 32|16@1+ (1,0) [0|64255] "count" Vector__XXX
 SG_ AuxiliaryIOChannel35 : 48|16@1+ (1,0) [0|64255] "count" Vector__XXX

BO_ 2566507262 AUXIO10: 8 Vector__XXX
 SG_ AuxiliaryIOChannel34 : 0|16@1+ (1,0) [0|64255] "count" Vector__XXX
 SG_ AuxiliaryIOChannel33 : 16|16@1+ (1,0) [0|64255] "count" Vector__XXX
 SG_ AuxiliaryIOChannel32 : 32|16@1+ (1,0) [0|64255] "count" Vector__XXX
 SG_ AuxiliaryIOChannel31 : 48|16@1+ (1,0) [0|64255] "count" Vector__XXX

BO_ 2566507518 AUXIO9: 8 Vector__XXX
 SG_ AuxiliaryIOChannel30 : 0|16@1+ (1,0) [0|64255] "count" Vector__XXX
 SG_ AuxiliaryIOChannel29 : 16|16@1+ (1,0) [0|64255] "count" Vector__XXX
 SG_ AuxiliaryIOChannel28 : 32|16@1+ (1,0) [0|64255] "count" Vector__XXX
 SG_ AuxiliaryIOChannel27 : 48|16@1+ (1,0) [0|64255] "count" Vector__XXX

BO_ 2566507774 AUXIO8: 8 Vector__XXX
 SG_ AuxiliaryIOChannel26 : 0|16@1+ (1,0) [0|64255] "count" Vector__XXX
 SG_ AuxiliaryIOChannel25 : 16|16@1+ (1,0) [0|64255] "count" Vector__XXX
 SG_ AuxiliaryIOChannel24 : 32|16@1+ (1,0) [0|64255] "count" Vector__XXX
 SG_ AuxiliaryIOChannel23 : 48|16@1+ (1,0) [0|64255] "count" Vector__XXX

BO_ 2633616894 ASI8: 8 Vector__XXX
 SG_ AftrtrtmntDslExhstFldEnm : 0|16@1+ (0.015625,0) [0|1003.984375] "km/L" Vector__XXX
 SG_ AftrtrtmntDslExhstFldLftmEnm : 16|16@1+ (0.015625,0) [0|1003.984375] "km/L" Vector__XXX

BO_ 2566508286 BKT6: 8 Vector__XXX
 SG_ BrkTmprtrRrAxl10LftWhl : 0|16@1+ (0.03125,-273) [-273|1734.96875] "degC" Vector__XXX
 SG_ BrkTmprtrRrAxl10RghtWhl : 16|16@1+ (0.03125,-273) [-273|1734.96875] "degC" Vector__XXX

BO_ 2566508542 BKT5: 8 Vector__XXX
 SG_ BrkTmprtrRrAxl8LftWhl : 0|16@1+ (0.03125,-273) [-273|1734.96875] "degC" Vector__XXX
 SG_ BrkTmprtrRrAxl8RghtWhl : 16|16@1+ (0.03125,-273) [-273|1734.96875] "degC" Vector__XXX
 SG_ BrkTmprtrRrAxl9LftWhl : 32|16@1+ (0.03125,-273) [-273|1734.96875] "degC" Vector__XXX
 SG_ BrkTmprtrRrAxl9RghtWhl : 48|16@1+ (0.03125,-273) [-273|1734.96875] "degC" Vector__XXX

BO_ 2566508798 BKT4: 8 Vector__XXX
 SG_ BrkTmprtrRrAxl6LftWhl : 0|16@1+ (0.03125,-273) [-273|1734.96875] "degC" Vector__XXX
 SG_ BrkTmprtrRrAxl6RghtWhl : 16|16@1+ (0.03125,-273) [-273|1734.96875] "degC" Vector__XXX
 SG_ BrkTmprtrRrAxl7LftWhl : 32|16@1+ (0.03125,-273) [-273|1734.96875] "degC" Vector__XXX
 SG_ BrkTmprtrRrAxl7RghtWhl : 48|16@1+ (0.03125,-273) [-273|1734.96875] "degC" Vector__XXX

BO_ 2566509054 BKT3: 8 Vector__XXX
 SG_ BrkTmprtrRrAxl4LftWhl : 0|16@1+ (0.03125,-273) [-273|1734.96875] "degC" Vector__XXX
 SG_ BrkTmprtrRrAxl4RghtWhl : 16|16@1+ (0.03125,-273) [-273|1734.96875] "degC" Vector__XXX
 SG_ BrkTmprtrRrAxl5LftWhl : 32|16@1+ (0.03125,-273) [-273|1734.96875] "degC" Vector__XXX
 SG_ BrkTmprtrRrAxl5RghtWhl : 48|16@1+ (0.03125,-273) [-273|1734.96875] "degC" Vector__XXX

BO_ 2566509310 BKT2: 8 Vector__XXX
 SG_ BrkTmprtrRrAxl2LftWhl : 0|16@1+ (0.03125,-273) [-273|1734.96875] "degC" Vector__XXX
 SG_ BrkTmprtrRrAxl2RghtWhl : 16|16@1+ (0.03125,-273) [-273|1734.96875] "degC" Vector__XXX
 SG_ BrkTmprtrRrAxl3LftWhl : 32|16@1+ (0.03125,-273) [-273|1734.96875] "degC" Vector__XXX
 SG_ BrkTmprtrRrAxl3RghtWhl : 48|16@1+ (0.03125,-273) [-273|1734.96875] "degC" Vector__XXX

BO_ 2566509566 BKT1: 8 Vector__XXX
 SG_ BrkTmprtrFrntAxlLftWhl : 0|16@1+ (0.03125,-273) [-273|1734.96875] "degC" Vector__XXX
 SG_ BrkTmprtrFrntAxlRghtWhl : 16|16@1+ (0.03125,-273) [-273|1734.96875] "degC" Vector__XXX
 SG_ BrkTmprtrRrAxl1LftWhl : 32|16@1+ (0.03125,-273) [-273|1734.96875] "degC" Vector__XXX
 SG_ BrkTmprtrRrAxl1RghtWhl : 48|16@1+ (0.03125,-273) [-273|1734.96875] "degC" Vector__XXX

BO_ 2633618686 EBC7: 8 Vector__XXX
 SG_ BrkLnngRmnngRrAxl8LftWhl : 0|8@1+ (0.4,0) [0|100] "%" Vector__XXX
 SG_ BrkLnngRmnngRrAxl8RghtWhl : 8|8@1+ (0.4,0) [0|100] "%" Vector__XXX
 SG_ BrkLnngRmnngRrAxl9LftWhl : 16|8@1+ (0.4,0) [0|100] "%" Vector__XXX
 SG_ BrkLnngRmnngRrAxl9RghtWhl : 24|8@1+ (0.4,0) [0|100] "%" Vector__XXX
 SG_ BrkLnngRmnngRrAxl10LftWhl : 32|8@1+ (0.4,0) [0|100] "%" Vector__XXX
 SG_ BrkLnngRmnngRrAxl10RghtWhl : 40|8@1+ (0.4,0) [0|100] "%" Vector__XXX

BO_ 2633618942 EBC6: 8 Vector__XXX
 SG_ BrkLnngRmnngRrAxl4LftWhl : 0|8@1+ (0.4,0) [0|100] "%" Vector__XXX
 SG_ BrkLnngRmnngRrAxl4RghtWhl : 8|8@1+ (0.4,0) [0|100] "%" Vector__XXX
 SG_ BrkLnngRmnngRrAxl5LftWhl : 16|8@1+ (0.4,0) [0|100] "%" Vector__XXX
 SG_ BrkLnngRmnngRrAxl5RghtWhl : 24|8@1+ (0.4,0) [0|100] "%" Vector__XXX
 SG_ BrkLnngRmnngRrAxl6LftWhl : 32|8@1+ (0.4,0) [0|100] "%" Vector__XXX
 SG_ BrkLnngRmnngRrAxl6RghtWhl : 40|8@1+ (0.4,0) [0|100] "%" Vector__XXX
 SG_ BrkLnngRmnngRrAxl7LftWhl : 48|8@1+ (0.4,0) [0|100] "%" Vector__XXX
 SG_ BrkLnngRmnngRrAxl7RghtWhl : 56|8@1+ (0.4,0) [0|100] "%" Vector__XXX

BO_ 2365183742 HVBCS3: 8 Vector__XXX
 SG_ Hvbcs3EmbeddedIntegritySupport : 50|2@1+ (1,0) [0|3] "" Vector__XXX
 SG_ Hvbcs3Counter : 52|4@1+ (1,0) [0|15] "" Vector__XXX
 SG_ Hvbcs3Crc : 56|8@1+ (1,0) [0|250] "count" Vector__XXX

BO_ 2365183998 HVBCS2: 8 Vector__XXX
 SG_ Hvbcs2EmbeddedIntegritySupport : 50|2@1+ (1,0) [0|3] "" Vector__XXX
 SG_ Hvbcs2Counter : 52|4@1+ (1,0) [0|15] "" Vector__XXX
 SG_ Hvbcs2Crc : 56|8@1+ (1,0) [0|250] "count" Vector__XXX

BO_ 2365184254 HVBCC2: 8 Vector__XXX
 SG_ HghVltgBsIntrf25CnntCmmnd : 0|2@1+ (1,0) [0|3] "" Vector__XXX
 SG_ HghVltgBsIntrf26CnntCmmnd : 2|2@1+ (1,0) [0|3] "" Vector__XXX
 SG_ HghVltgBsIntrf27CnntCmmnd : 4|2@1+ (1,0) [0|3] "" Vector__XXX
 SG_ HghVltgBsIntrf28CnntCmmnd : 6|2@1+ (1,0) [0|3] "" Vector__XXX
 SG_ HghVltgBsIntrf29CnntCmmnd : 8|2@1+ (1,0) [0|3] "" Vector__XXX
 SG_ HghVltgBsIntrf30CnntCmmnd : 10|2@1+ (1,0) [0|3] "" Vector__XXX
 SG_ HghVltgBsIntrf31CnntCmmnd : 12|2@1+ (1,0) [0|3] "" Vector__XXX
 SG_ HghVltgBsIntrf32CnntCmmnd : 14|2@1+ (1,0) [0|3] "" Vector__XXX
 SG_ Hvbcc2EmbeddedIntegritySupport : 50|2@1+ (1,0) [0|3] "" Vector__XXX
 SG_ Hvbcc2Counter : 52|4@1+ (1,0) [0|15] "" Vector__XXX
 SG_ Hvbcc2Crc : 56|8@1+ (1,0) [0|250] "count" Vector__XXX

BO_ 2566095358 PTODE2: 8 Vector__XXX
 SG_ EnlSwthTrnsmssnInptShftPt3 : 0|2@1+ (1,0) [0|3] "" Vector__XXX
 SG_ EnlSwthTrnsmssnInptShftPt4 : 2|2@1+ (1,0) [0|3] "" Vector__XXX
 SG_ EnggmntCnsntTrnsmssnInptShftPt3 : 8|2@1+ (1,0) [0|3] "" Vector__XXX
 SG_ EnggmntCnsntTrnsmssnInptShftPt4 : 10|2@1+ (1,0) [0|3] "" Vector__XXX
 SG_ EnggmntSttsTrnsmssnInptShftPt3 : 16|2@1+ (1,0) [0|3] "" Vector__XXX
 SG_ EnggmntSttsTrnsmssnInptShftPt4 : 18|2@1+ (1,0) [0|3] "" Vector__XXX

BO_ 2364769022 FCSHP: 8 Vector__XXX
 SG_ FcshpCrc : 0|8@1+ (1,0) [0|250] "count" Vector__XXX
 SG_ FcshpCounter : 8|4@1+ (1,0) [0|15] "" Vector__XXX
 SG_ FlCllSstmHdrgnInltPrssr : 16|16@1+ (0.125,0) [0|8031.875] "kPa" Vector__XXX

BO_ 2566502142 WSP5: 8 Vector__XXX
 SG_ EstmtdWllStmltnPmpLOlFlwRt : 0|16@1+ (0.05,0) [0|3212.75] "l/h" Vector__XXX
 SG_ AtlWllStmltnPmpLOlFlwRt : 16|16@1+ (0.05,0) [0|3212.75] "l/h" Vector__XXX
 SG_ EstmtdWllStmltnPmpGrBxLOlFlwRt : 32|16@1+ (0.05,0) [0|3212.75] "l/h" Vector__XXX
 SG_ AtlWllStmltnPmpGrBxLOlFlwRt : 48|16@1+ (0.05,0) [0|3212.75] "l/h" Vector__XXX

BO_ 2566502398 WSP4: 8 Vector__XXX
 SG_ WellStimulationPumpOilPressure : 0|16@1+ (0.1,0) [0|6425.5] "kPa" Vector__XXX
 SG_ WllStmltnPmpOtltOlPrssr : 16|16@1+ (0.1,0) [0|6425.5] "kPa" Vector__XXX
 SG_ WllStmltnPmpOtltOlTmprtr : 32|8@1+ (1,-40) [-40|210] "degC" Vector__XXX

BO_ 2566502654 TI: 8 Vector__XXX
 SG_ TireRollingDistance : 0|16@1+ (0.05,0) [0|3212.75] "rev/km" Vector__XXX

BO_ 2566502910 H2SS: 8 Vector__XXX
 SG_ HydrogenRedLampData : 0|2@1+ (1,0) [0|3] "" Vector__XXX
 SG_ HydrogenYellowLampData : 2|2@1+ (1,0) [0|3] "" Vector__XXX

BO_ 2566503166 RWGPSC: 9 Vector__XXX
 SG_ RouteNumberOfWaypoints : 0|8@1+ (1,0) [0|250] "count" Vector__XXX
 SG_ RouteWaypointLatitude : 8|32@1+ (0.0000001,-210) [-210|211.1081215] "deg" Vector__XXX
 SG_ RouteWaypointLongitude : 40|32@1+ (0.0000001,-210) [-210|211.1081215] "deg" Vector__XXX

BO_ 2566503422 RTI: 8 Vector__XXX
 SG_ RouteRemainingTime : 0|16@1+ (1,0) [0|64255] "min" Vector__XXX
 SG_ RouteRemainingDistance : 16|16@1+ (0.25,0) [0|16063.75] "km" Vector__XXX
 SG_ RouteNextWaypoint : 32|8@1+ (1,0) [0|250] "count" Vector__XXX
 SG_ RouteIdentifier : 40|4@1+ (1,0) [0|13] "count" Vector__XXX

BO_ 2566503678 EFLP15: 8 Vector__XXX
 SG_ EngnCrnksBrthrOlSprtrIntkPrssr : 0|16@1+ (0.0078125,-100) [-100|401.9921875] "kPa" Vector__XXX

BO_ 2566503934 FCSCI3: 8 Vector__XXX
 SG_ FlCllSstmClntFlwRtExtnddRng : 0|16@1+ (0.5,0) [0|32127.5] "l/min" Vector__XXX
 SG_ FlCllStkClntFlwRtExtnddRng : 16|16@1+ (0.5,0) [0|32127.5] "l/min" Vector__XXX

BO_ 2566504190 TCFG3: 8 Vector__XXX
 SG_ TransmissionMode1Configuration : 0|2@1+ (1,0) [0|3] "" Vector__XXX
 SG_ TransmissionMode2Configuration : 2|2@1+ (1,0) [0|3] "" Vector__XXX
 SG_ TransmissionMode3Configuration : 4|2@1+ (1,0) [0|3] "" Vector__XXX
 SG_ TransmissionMode4Configuration : 6|2@1+ (1,0) [0|3] "" Vector__XXX
 SG_ TransmissionMode5Configuration : 8|2@1+ (1,0) [0|3] "" Vector__XXX
 SG_ TransmissionMode6Configuration : 10|2@1+ (1,0) [0|3] "" Vector__XXX
 SG_ TransmissionMode7Configuration : 12|2@1+ (1,0) [0|3] "" Vector__XXX
 SG_ TransmissionMode8Configuration : 14|2@1+ (1,0) [0|3] "" Vector__XXX
 SG_ TransmissionMode9Configuration : 16|2@1+ (1,0) [0|3] "" Vector__XXX
 SG_ TransmissionMode10Configuration : 18|2@1+ (1,0) [0|3] "" Vector__XXX
 SG_ TransmissionMode11Configuration : 20|2@1+ (1,0) [0|3] "" Vector__XXX
 SG_ TransmissionMode12Configuration : 22|2@1+ (1,0) [0|3] "" Vector__XXX
 SG_ TransmissionMode13Configuration : 24|2@1+ (1,0) [0|3] "" Vector__XXX
 SG_ TransmissionMode14Configuration : 26|2@1+ (1,0) [0|3] "" Vector__XXX
 SG_ TransmissionMode15Configuration : 28|2@1+ (1,0) [0|3] "" Vector__XXX
 SG_ TransmissionMode16Configuration : 30|2@1+ (1,0) [0|3] "" Vector__XXX
 SG_ TransmissionMode17Configuration : 32|2@1+ (1,0) [0|3] "" Vector__XXX
 SG_ TransmissionMode18Configuration : 34|2@1+ (1,0) [0|3] "" Vector__XXX
 SG_ TransmissionMode19Configuration : 36|2@1+ (1,0) [0|3] "" Vector__XXX
 SG_ TransmissionMode20Configuration : 38|2@1+ (1,0) [0|3] "" Vector__XXX

BO_ 2566505214 H2SYSINF: 8 Vector__XXX
 SG_ HydrogenRedLampCommand : 0|2@1+ (1,0) [0|3] "" Vector__XXX
 SG_ HydrogenYellowLampCommand : 2|2@1+ (1,0) [0|3] "" Vector__XXX

BO_ 2566095870 EGF2: 8 Vector__XXX
 SG_ EngnTrhrgr1CmprssrIntkFlwRt : 0|16@1+ (0.2,0) [0|12851] "kg/h" Vector__XXX
 SG_ EngnTrhrgr2CmprssrIntkFlwRt : 16|16@1+ (0.2,0) [0|12851] "kg/h" Vector__XXX
 SG_ EngnIntkArMssFlwRtExtnddRng : 32|16@1+ (0.2,0) [0|12851] "kg/h" Vector__XXX

BO_ 2566096126 ESI: 8 Vector__XXX
 SG_ EngnSprhrgr1BpssAttrPstn : 0|8@1+ (0.4,0) [0|100] "%" Vector__XXX
 SG_ EngnSprhrgr2BpssAttrPstn : 8|8@1+ (0.4,0) [0|100] "%" Vector__XXX
 SG_ EngnSprhrgr1ClthVlvCmmnd : 16|8@1+ (0.4,0) [0|100] "%" Vector__XXX
 SG_ EngnSprhrgr2ClthVlvCmmnd : 24|8@1+ (0.4,0) [0|100] "%" Vector__XXX
 SG_ EngineSupercharger1Speed : 32|16@1+ (4,0) [0|257020] "rpm" Vector__XXX
 SG_ EngineSupercharger2Speed : 48|16@1+ (4,0) [0|257020] "rpm" Vector__XXX

BO_ 2365156094 ERDCDC4RF: 8 Vector__XXX
 SG_ ErDcDc4ReferenceCrc : 0|8@1+ (1,0) [0|250] "count" Vector__XXX
 SG_ ErDcDc4ReferenceCounter : 8|4@1+ (1,0) [0|15] "" Vector__XXX
 SG_ ErDcDc4ReferenceCurrent : 16|16@1+ (0.125,0) [0|8031.875] "A" Vector__XXX
 SG_ ErDcDc4ReferenceVoltage : 32|16@1+ (0.125,0) [0|8031.875] "V" Vector__XXX
 SG_ ErDcDc4ReferencePower : 48|16@1+ (0.0625,0) [0|4015.9375] "kW" Vector__XXX

BO_ 2365156350 ERDCDC4PLR: 8 Vector__XXX
 SG_ ErDD4PrmrSdPwrMnmmLmtRqst : 0|16@1+ (0.00390625,-125) [-125|125.99609375] "%" Vector__XXX
 SG_ ErDD4PrmrSdPwrMxmmLmtRqst : 16|16@1+ (0.00390625,-125) [-125|125.99609375] "%" Vector__XXX
 SG_ ErDD4SndrSdPwrMnmmLmtRqst : 32|16@1+ (0.00390625,-125) [-125|125.99609375] "%" Vector__XXX
 SG_ ErDD4SndrSdPwrMxmmLmtRqst : 48|16@1+ (0.00390625,-125) [-125|125.99609375] "%" Vector__XXX

BO_ 2365156606 ERDCDC4CLR: 8 Vector__XXX
 SG_ ErDD4PrmrSdCrrntMnmmLmtRqst : 0|16@1+ (0.00390625,-125) [-125|125.99609375] "%" Vector__XXX
 SG_ ErDD4PrmrSdCrrntMxmmLmtRqst : 16|16@1+ (0.00390625,-125) [-125|125.99609375] "%" Vector__XXX
 SG_ ErDD4SndrSdCrrntMnmmLmtRqst : 32|16@1+ (0.00390625,-125) [-125|125.99609375] "%" Vector__XXX
 SG_ ErDD4SndrSdCrrntMxmmLmtRqst : 48|16@1+ (0.00390625,-125) [-125|125.99609375] "%" Vector__XXX

BO_ 2365156862 ERDCDC4VLR: 8 Vector__XXX
 SG_ ErDD4PrmrSdVltgMnmmLmtRqst : 0|16@1+ (0.00390625,-125) [0|125.99609375] "%" Vector__XXX
 SG_ ErDD4PrmrSdVltgMxmmLmtRqst : 16|16@1+ (0.00390625,-125) [0|125.99609375] "%" Vector__XXX
 SG_ ErDD4SndrSdVltgMnmmLmtRqst : 32|16@1+ (0.00390625,-125) [0|125.99609375] "%" Vector__XXX
 SG_ ErDD4SndrSdVltgMxmmLmtRqst : 48|16@1+ (0.00390625,-125) [0|125.99609375] "%" Vector__XXX

BO_ 2365157118 ERDCDC4T: 8 Vector__XXX
 SG_ ErDcDc4ConverterTemperature : 0|8@1+ (1,-40) [-40|210] "degC" Vector__XXX
 SG_ ErDD4CnvrtrEltrnFltrTmprtr : 8|8@1+ (1,-40) [-40|210] "degC" Vector__XXX
 SG_ ErDD4PwrEltrnsTmprtr : 16|8@1+ (1,-40) [-40|210] "degC" Vector__XXX
 SG_ ErDcDc4CoolantInTemperature : 24|8@1+ (1,-40) [-40|210] "degC" Vector__XXX
 SG_ ErDcDc4CoolantOutTemperature : 32|8@1+ (1,-40) [-40|210] "degC" Vector__XXX

BO_ 2566483966 ERDCDC4PLS: 8 Vector__XXX
 SG_ ErDD4PrmrSdPwrMnmmLmtSttng : 0|16@1+ (0.00390625,-125) [-125|125.99609375] "%" Vector__XXX
 SG_ ErDD4PrmrSdPwrMxmmLmtSttng : 16|16@1+ (0.00390625,-125) [-125|125.99609375] "%" Vector__XXX
 SG_ ErDD4SndrSdPwrMnmmLmtSttng : 32|16@1+ (0.00390625,-125) [-125|125.99609375] "%" Vector__XXX
 SG_ ErDD4SndrSdPwrMxmmLmtSttng : 48|16@1+ (0.00390625,-125) [-125|125.99609375] "%" Vector__XXX

BO_ 2566484222 ERDCDC4CLS: 8 Vector__XXX
 SG_ ErDD4PrmrSdCrrntMnmmLmtSttng : 0|16@1+ (0.00390625,-125) [-125|125.99609375] "%" Vector__XXX
 SG_ ErDD4PrmrSdCrrntMxmmLmtSttng : 16|16@1+ (0.00390625,-125) [-125|125.99609375] "%" Vector__XXX
 SG_ ErDD4SndrSdCrrntMnmmLmtSttng : 32|16@1+ (0.00390625,-125) [-125|125.99609375] "%" Vector__XXX
 SG_ ErDD4SndrSdCrrntMxmmLmtSttng : 48|16@1+ (0.00390625,-125) [-125|125.99609375] "%" Vector__XXX

BO_ 2566484478 ERDCDC4VLS: 8 Vector__XXX
 SG_ ErDD4PrmrSdVltgMnmmLmtSttng : 0|16@1+ (0.00390625,-125) [0|125.99609375] "%" Vector__XXX
 SG_ ErDD4PrmrSdVltgMxmmLmtSttng : 16|16@1+ (0.00390625,-125) [0|125.99609375] "%" Vector__XXX
 SG_ ErDD4SndrSdVltgMnmmLmtSttng : 32|16@1+ (0.00390625,-125) [0|125.99609375] "%" Vector__XXX
 SG_ ErDD4SndrSdVltgMxmmLmtSttng : 48|16@1+ (0.00390625,-125) [0|125.99609375] "%" Vector__XXX

BO_ 2365158142 ERDCDC4LV: 8 Vector__XXX
 SG_ ErDD4CntrllrInptIgntnVltg : 0|16@1+ (0.05,0) [0|3212.75] "V" Vector__XXX
 SG_ ErDD4CntrllrInptUnswthdSlVltg : 16|16@1+ (0.05,0) [0|3212.75] "V" Vector__XXX

BO_ 2365158398 ERDCDC4PCV: 8 Vector__XXX
 SG_ ErDcDc4PrimarySidePower : 0|16@1+ (0.00390625,-125) [-125|125.99609375] "%" Vector__XXX
 SG_ ErDcDc4SecondarySidePower : 16|16@1+ (0.00390625,-125) [-125|125.99609375] "%" Vector__XXX
 SG_ ErDD4PrmrSdNgtvTChsssGrndVltg : 32|16@1+ (0.00390625,-125) [0|125.99609375] "%" Vector__XXX
 SG_ ErDD4SndrSdNgtvTChsssGrndVltg : 48|16@1+ (0.00390625,-125) [0|125.99609375] "%" Vector__XXX

BO_ 2365158654 ERDCDC4VC: 8 Vector__XXX
 SG_ ErDcDc4PrimarySideVoltage : 0|16@1+ (0.00390625,-125) [0|125.99609375] "%" Vector__XXX
 SG_ ErDcDc4SecondarySideVoltage : 16|16@1+ (0.00390625,-125) [0|125.99609375] "%" Vector__XXX
 SG_ ErDcDc4PrimarySideCurrent : 32|16@1+ (0.00390625,-125) [-125|125.99609375] "%" Vector__XXX
 SG_ ErDcDc4SecondarySideCurrent : 48|16@1+ (0.00390625,-125) [-125|125.99609375] "%" Vector__XXX

BO_ 2365158910 ERDCDC4OS: 8 Vector__XXX
 SG_ ErDcDc4StatusCrc : 0|8@1+ (1,0) [0|250] "count" Vector__XXX
 SG_ ErDcDc4StatusCounter : 8|4@1+ (1,0) [0|15] "" Vector__XXX
 SG_ ErDcDc4OperationalStatus : 12|4@1+ (1,0) [0|15] "" Vector__XXX
 SG_ ErDcDc4HvilStatus : 16|2@1+ (1,0) [0|3] "" Vector__XXX
 SG_ ErDcDc4LoadshedRequest : 18|2@1+ (1,0) [0|3] "" Vector__XXX
 SG_ ErDD4PwrLmtDTPrmrSdCrrntMnmm : 20|2@1+ (1,0) [0|3] "" Vector__XXX
 SG_ ErDD4PwrLmtDTPrmrSdCrrntMxmm : 22|2@1+ (1,0) [0|3] "" Vector__XXX
 SG_ ErDD4PwrLmtDTSndrSdCrrntMnmm : 24|2@1+ (1,0) [0|3] "" Vector__XXX
 SG_ ErDD4PwrLmtDTSndrSdCrrntMxmm : 26|2@1+ (1,0) [0|3] "" Vector__XXX
 SG_ ErDD4PwrLmtDTPrmrSdVltgMnmm : 28|2@1+ (1,0) [0|3] "" Vector__XXX
 SG_ ErDD4PwrLmtDTPrmrSdVltgMxmm : 30|2@1+ (1,0) [0|3] "" Vector__XXX
 SG_ ErDD4PwrLmtDTSndrSdVltgMnmm : 32|2@1+ (1,0) [0|3] "" Vector__XXX
 SG_ ErDD4PwrLmtDTSndrSdVltgMxmm : 34|2@1+ (1,0) [0|3] "" Vector__XXX
 SG_ ErDD4PwrLmtDTCnvrtrTmprtr : 36|2@1+ (1,0) [0|3] "" Vector__XXX
 SG_ ErDD4PwrLmtDTEltrnFltrTmprtr : 38|2@1+ (1,0) [0|3] "" Vector__XXX
 SG_ ErDD4PwrLmtDTPwrEltrnsTmprtr : 40|2@1+ (1,0) [0|3] "" Vector__XXX
 SG_ ErDD4PwrLmtDTUndfndRsn : 42|2@1+ (1,0) [0|3] "" Vector__XXX

BO_ 2365159166 ERDCDC4C: 8 Vector__XXX
 SG_ ErDcDc4CommandCrc : 0|8@1+ (1,0) [0|250] "count" Vector__XXX
 SG_ ErDcDc4CommandCounter : 8|4@1+ (1,0) [0|15] "" Vector__XXX
 SG_ ErDcDc4OperationalCommand : 12|4@1+ (1,0) [0|15] "" Vector__XXX
 SG_ ErDcDc4OperationalSetpoint : 16|16@1+ (0.00390625,-125) [-125|125.99609375] "%" Vector__XXX

BO_ 2365159422 ERDCDC3RF: 8 Vector__XXX
 SG_ ErDcDc3ReferenceCrc : 0|8@1+ (1,0) [0|250] "count" Vector__XXX
 SG_ ErDcDc3ReferenceCounter : 8|4@1+ (1,0) [0|15] "" Vector__XXX
 SG_ ErDcDc3ReferenceCurrent : 16|16@1+ (0.125,0) [0|8031.875] "A" Vector__XXX
 SG_ ErDcDc3ReferenceVoltage : 32|16@1+ (0.125,0) [0|8031.875] "V" Vector__XXX
 SG_ ErDcDc3ReferencePower : 48|16@1+ (0.0625,0) [0|4015.9375] "kW" Vector__XXX

BO_ 2365159678 ERDCDC3PLR: 8 Vector__XXX
 SG_ ErDD3PrmrSdPwrMnmmLmtRqst : 0|16@1+ (0.00390625,-125) [-125|125.99609375] "%" Vector__XXX
 SG_ ErDD3PrmrSdPwrMxmmLmtRqst : 16|16@1+ (0.00390625,-125) [-125|125.99609375] "%" Vector__XXX
 SG_ ErDD3SndrSdPwrMnmmLmtRqst : 32|16@1+ (0.00390625,-125) [-125|125.99609375] "%" Vector__XXX
 SG_ ErDD3SndrSdPwrMxmmLmtRqst : 48|16@1+ (0.00390625,-125) [-125|125.99609375] "%" Vector__XXX

BO_ 2365159934 ERDCDC3CLR: 8 Vector__XXX
 SG_ ErDD3PrmrSdCrrntMnmmLmtRqst : 0|16@1+ (0.00390625,-125) [-125|125.99609375] "%" Vector__XXX
 SG_ ErDD3PrmrSdCrrntMxmmLmtRqst : 16|16@1+ (0.00390625,-125) [-125|125.99609375] "%" Vector__XXX
 SG_ ErDD3SndrSdCrrntMnmmLmtRqst : 32|16@1+ (0.00390625,-125) [-125|125.99609375] "%" Vector__XXX
 SG_ ErDD3SndrSdCrrntMxmmLmtRqst : 48|16@1+ (0.00390625,-125) [-125|125.99609375] "%" Vector__XXX

BO_ 2365160190 ERDCDC3VLR: 8 Vector__XXX
 SG_ ErDD3PrmrSdVltgMnmmLmtRqst : 0|16@1+ (0.00390625,-125) [0|125.99609375] "%" Vector__XXX
 SG_ ErDD3PrmrSdVltgMxmmLmtRqst : 16|16@1+ (0.00390625,-125) [0|125.99609375] "%" Vector__XXX
 SG_ ErDD3SndrSdVltgMnmmLmtRqst : 32|16@1+ (0.00390625,-125) [0|125.99609375] "%" Vector__XXX
 SG_ ErDD3SndrSdVltgMxmmLmtRqst : 48|16@1+ (0.00390625,-125) [0|125.99609375] "%" Vector__XXX

BO_ 2365160446 ERDCDC3T: 8 Vector__XXX
 SG_ ErDcDc3ConverterTemperature : 0|8@1+ (1,-40) [-40|210] "degC" Vector__XXX
 SG_ ErDD3CnvrtrEltrnFltrTmprtr : 8|8@1+ (1,-40) [-40|210] "degC" Vector__XXX
 SG_ ErDD3PwrEltrnsTmprtr : 16|8@1+ (1,-40) [-40|210] "degC" Vector__XXX
 SG_ ErDcDc3CoolantInTemperature : 24|8@1+ (1,-40) [-40|210] "degC" Vector__XXX
 SG_ ErDcDc3CoolantOutTemperature : 32|8@1+ (1,-40) [-40|210] "degC" Vector__XXX

BO_ 2566487294 ERDCDC3PLS: 8 Vector__XXX
 SG_ ErDD3PrmrSdPwrMnmmLmtSttng : 0|16@1+ (0.00390625,-125) [-125|125.99609375] "%" Vector__XXX
 SG_ ErDD3PrmrSdPwrMxmmLmtSttng : 16|16@1+ (0.00390625,-125) [-125|125.99609375] "%" Vector__XXX
 SG_ ErDD3SndrSdPwrMnmmLmtSttng : 32|16@1+ (0.00390625,-125) [-125|125.99609375] "%" Vector__XXX
 SG_ ErDD3SndrSdPwrMxmmLmtSttng : 48|16@1+ (0.00390625,-125) [-125|125.99609375] "%" Vector__XXX

BO_ 2566487550 ERDCDC3CLS: 8 Vector__XXX
 SG_ ErDD3PrmrSdCrrntMnmmLmtSttng : 0|16@1+ (0.00390625,-125) [-125|125.99609375] "%" Vector__XXX
 SG_ ErDD3PrmrSdCrrntMxmmLmtSttng : 16|16@1+ (0.00390625,-125) [-125|125.99609375] "%" Vector__XXX
 SG_ ErDD3SndrSdCrrntMnmmLmtSttng : 32|16@1+ (0.00390625,-125) [-125|125.99609375] "%" Vector__XXX
 SG_ ErDD3SndrSdCrrntMxmmLmtSttng : 48|16@1+ (0.00390625,-125) [-125|125.99609375] "%" Vector__XXX

BO_ 2566487806 ERDCDC3VLS: 8 Vector__XXX
 SG_ ErDD3PrmrSdVltgMnmmLmtSttng : 0|16@1+ (0.00390625,-125) [0|125.99609375] "%" Vector__XXX
 SG_ ErDD3PrmrSdVltgMxmmLmtSttng : 16|16@1+ (0.00390625,-125) [0|125.99609375] "%" Vector__XXX
 SG_ ErDD3SndrSdVltgMnmmLmtSttng : 32|16@1+ (0.00390625,-125) [0|125.99609375] "%" Vector__XXX
 SG_ ErDD3SndrSdVltgMxmmLmtSttng : 48|16@1+ (0.00390625,-125) [0|125.99609375] "%" Vector__XXX

BO_ 2365161470 ERDCDC3LV: 8 Vector__XXX
 SG_ ErDD3CntrllrInptIgntnVltg : 0|16@1+ (0.05,0) [0|3212.75] "V" Vector__XXX
 SG_ ErDD3CntrllrInptUnswthdSlVltg : 16|16@1+ (0.05,0) [0|3212.75] "V" Vector__XXX

BO_ 2365161726 ERDCDC3PCV: 8 Vector__XXX
 SG_ ErDcDc3PrimarySidePower : 0|16@1+ (0.00390625,-125) [-125|125.99609375] "%" Vector__XXX
 SG_ ErDcDc3SecondarySidePower : 16|16@1+ (0.00390625,-125) [-125|125.99609375] "%" Vector__XXX
 SG_ ErDD3PrmrSdNgtvTChsssGrndVltg : 32|16@1+ (0.00390625,-125) [0|125.99609375] "%" Vector__XXX
 SG_ ErDD3SndrSdNgtvTChsssGrndVltg : 48|16@1+ (0.00390625,-125) [0|125.99609375] "%" Vector__XXX

BO_ 2365161982 ERDCDC3VC: 8 Vector__XXX
 SG_ ErDcDc3PrimarySideVoltage : 0|16@1+ (0.00390625,-125) [0|125.99609375] "%" Vector__XXX
 SG_ ErDcDc3SecondarySideVoltage : 16|16@1+ (0.00390625,-125) [0|125.99609375] "%" Vector__XXX
 SG_ ErDcDc3PrimarySideCurrent : 32|16@1+ (0.00390625,-125) [-125|125.99609375] "%" Vector__XXX
 SG_ ErDcDc3SecondarySideCurrent : 48|16@1+ (0.00390625,-125) [-125|125.99609375] "%" Vector__XXX

BO_ 2365162238 ERDCDC3OS: 8 Vector__XXX
 SG_ ErDcDc3StatusCrc : 0|8@1+ (1,0) [0|250] "count" Vector__XXX
 SG_ ErDcDc3StatusCounter : 8|4@1+ (1,0) [0|15] "" Vector__XXX
 SG_ ErDcDc3OperationalStatus : 12|4@1+ (1,0) [0|15] "" Vector__XXX
 SG_ ErDcDc3HvilStatus : 16|2@1+ (1,0) [0|3] "" Vector__XXX
 SG_ ErDcDc3LoadshedRequest : 18|2@1+ (1,0) [0|3] "" Vector__XXX
 SG_ ErDD3PwrLmtDTPrmrSdCrrntMnmm : 20|2@1+ (1,0) [0|3] "" Vector__XXX
 SG_ ErDD3PwrLmtDTPrmrSdCrrntMxmm : 22|2@1+ (1,0) [0|3] "" Vector__XXX
 SG_ ErDD3PwrLmtDTSndrSdCrrntMnmm : 24|2@1+ (1,0) [0|3] "" Vector__XXX
 SG_ ErDD3PwrLmtDTSndrSdCrrntMxmm : 26|2@1+ (1,0) [0|3] "" Vector__XXX
 SG_ ErDD3PwrLmtDTPrmrSdVltgMnmm : 28|2@1+ (1,0) [0|3] "" Vector__XXX
 SG_ ErDD3PwrLmtDTPrmrSdVltgMxmm : 30|2@1+ (1,0) [0|3] "" Vector__XXX
 SG_ ErDD3PwrLmtDTSndrSdVltgMnmm : 32|2@1+ (1,0) [0|3] "" Vector__XXX
 SG_ ErDD3PwrLmtDTSndrSdVltgMxmm : 34|2@1+ (1,0) [0|3] "" Vector__XXX
 SG_ ErDD3PwrLmtDTCnvrtrTmprtr : 36|2@1+ (1,0) [0|3] "" Vector__XXX
 SG_ ErDD3PwrLmtDTEltrnFltrTmprtr : 38|2@1+ (1,0) [0|3] "" Vector__XXX
 SG_ ErDD3PwrLmtDTPwrEltrnsTmprtr : 40|2@1+ (1,0) [0|3] "" Vector__XXX
 SG_ ErDD3PwrLmtDTUndfndRsn : 42|2@1+ (1,0) [0|3] "" Vector__XXX

BO_ 2365162494 ERDCDC3C: 8 Vector__XXX
 SG_ ErDcDc3CommandCrc : 0|8@1+ (1,0) [0|250] "count" Vector__XXX
 SG_ ErDcDc3CommandCounter : 8|4@1+ (1,0) [0|15] "" Vector__XXX
 SG_ ErDcDc3OperationalCommand : 12|4@1+ (1,0) [0|15] "" Vector__XXX
 SG_ ErDcDc3OperationalSetpoint : 16|16@1+ (0.00390625,-125) [-125|125.99609375] "%" Vector__XXX

BO_ 2365162750 ERDCDC2RF: 8 Vector__XXX
 SG_ ErDcDc2ReferenceCrc : 0|8@1+ (1,0) [0|250] "count" Vector__XXX
 SG_ ErDcDc2ReferenceCounter : 8|4@1+ (1,0) [0|15] "" Vector__XXX
 SG_ ErDcDc2ReferenceCurrent : 16|16@1+ (0.125,0) [0|8031.875] "A" Vector__XXX
 SG_ ErDcDc2ReferenceVoltage : 32|16@1+ (0.125,0) [0|8031.875] "V" Vector__XXX
 SG_ ErDcDc2ReferencePower : 48|16@1+ (0.0625,0) [0|4015.9375] "kW" Vector__XXX

BO_ 2365163006 ERDCDC2PLR: 8 Vector__XXX
 SG_ ErDD2PrmrSdPwrMnmmLmtRqst : 0|16@1+ (0.00390625,-125) [-125|125.99609375] "%" Vector__XXX
 SG_ ErDD2PrmrSdPwrMxmmLmtRqst : 16|16@1+ (0.00390625,-125) [-125|125.99609375] "%" Vector__XXX
 SG_ ErDD2SndrSdPwrMnmmLmtRqst : 32|16@1+ (0.00390625,-125) [-125|125.99609375] "%" Vector__XXX
 SG_ ErDD2SndrSdPwrMxmmLmtRqst : 48|16@1+ (0.00390625,-125) [-125|125.99609375] "%" Vector__XXX

BO_ 2365163262 ERDCDC2CLR: 8 Vector__XXX
 SG_ ErDD2PrmrSdCrrntMnmmLmtRqst : 0|16@1+ (0.00390625,-125) [-125|125.99609375] "%" Vector__XXX
 SG_ ErDD2PrmrSdCrrntMxmmLmtRqst : 16|16@1+ (0.00390625,-125) [-125|125.99609375] "%" Vector__XXX
 SG_ ErDD2SndrSdCrrntMnmmLmtRqst : 32|16@1+ (0.00390625,-125) [-125|125.99609375] "%" Vector__XXX
 SG_ ErDD2SndrSdCrrntMxmmLmtRqst : 48|16@1+ (0.00390625,-125) [-125|125.99609375] "%" Vector__XXX

BO_ 2365163518 ERDCDC2VLR: 8 Vector__XXX
 SG_ ErDD2PrmrSdVltgMnmmLmtRqst : 0|16@1+ (0.00390625,-125) [0|125.99609375] "%" Vector__XXX
 SG_ ErDD2PrmrSdVltgMxmmLmtRqst : 16|16@1+ (0.00390625,-125) [0|125.99609375] "%" Vector__XXX
 SG_ ErDD2SndrSdVltgMnmmLmtRqst : 32|16@1+ (0.00390625,-125) [0|125.99609375] "%" Vector__XXX
 SG_ ErDD2SndrSdVltgMxmmLmtRqst : 48|16@1+ (0.00390625,-125) [0|125.99609375] "%" Vector__XXX

BO_ 2365163774 ERDCDC2T: 8 Vector__XXX
 SG_ ErDcDc2ConverterTemperature : 0|8@1+ (1,-40) [-40|210] "degC" Vector__XXX
 SG_ ErDD2CnvrtrEltrnFltrTmprtr : 8|8@1+ (1,-40) [-40|210] "degC" Vector__XXX
 SG_ ErDD2PwrEltrnsTmprtr : 16|8@1+ (1,-40) [-40|210] "degC" Vector__XXX
 SG_ ErDcDc2CoolantInTemperature : 24|8@1+ (1,-40) [-40|210] "degC" Vector__XXX
 SG_ ErDcDc2CoolantOutTemperature : 32|8@1+ (1,-40) [-40|210] "degC" Vector__XXX

BO_ 2566490622 ERDCDC2PLS: 8 Vector__XXX
 SG_ ErDD2PrmrSdPwrMnmmLmtSttng : 0|16@1+ (0.00390625,-125) [-125|125.99609375] "%" Vector__XXX
 SG_ ErDD2PrmrSdPwrMxmmLmtSttng : 16|16@1+ (0.00390625,-125) [-125|125.99609375] "%" Vector__XXX
 SG_ ErDD2SndrSdPwrMnmmLmtSttng : 32|16@1+ (0.00390625,-125) [-125|125.99609375] "%" Vector__XXX
 SG_ ErDD2SndrSdPwrMxmmLmtSttng : 48|16@1+ (0.00390625,-125) [-125|125.99609375] "%" Vector__XXX

BO_ 2566490878 ERDCDC2CLS: 8 Vector__XXX
 SG_ ErDD2PrmrSdCrrntMnmmLmtSttng : 0|16@1+ (0.00390625,-125) [-125|125.99609375] "%" Vector__XXX
 SG_ ErDD2PrmrSdCrrntMxmmLmtSttng : 16|16@1+ (0.00390625,-125) [-125|125.99609375] "%" Vector__XXX
 SG_ ErDD2SndrSdCrrntMnmmLmtSttng : 32|16@1+ (0.00390625,-125) [-125|125.99609375] "%" Vector__XXX
 SG_ ErDD2SndrSdCrrntMxmmLmtSttng : 48|16@1+ (0.00390625,-125) [-125|125.99609375] "%" Vector__XXX

BO_ 2566491134 ERDCDC2VLS: 8 Vector__XXX
 SG_ ErDD2PrmrSdVltgMnmmLmtSttng : 0|16@1+ (0.00390625,-125) [0|125.99609375] "%" Vector__XXX
 SG_ ErDD2PrmrSdVltgMxmmLmtSttng : 16|16@1+ (0.00390625,-125) [0|125.99609375] "%" Vector__XXX
 SG_ ErDD2SndrSdVltgMnmmLmtSttng : 32|16@1+ (0.00390625,-125) [0|125.99609375] "%" Vector__XXX
 SG_ ErDD2SndrSdVltgMxmmLmtSttng : 48|16@1+ (0.00390625,-125) [0|125.99609375] "%" Vector__XXX

BO_ 2365164798 ERDCDC2LV: 8 Vector__XXX
 SG_ ErDD2CntrllrInptIgntnVltg : 0|16@1+ (0.05,0) [0|3212.75] "V" Vector__XXX
 SG_ ErDD2CntrllrInptUnswthdSlVltg : 16|16@1+ (0.05,0) [0|3212.75] "V" Vector__XXX

BO_ 2365165054 ERDCDC2PCV: 8 Vector__XXX
 SG_ ErDcDc2PrimarySidePower : 0|16@1+ (0.00390625,-125) [-125|125.99609375] "%" Vector__XXX
 SG_ ErDcDc2SecondarySidePower : 16|16@1+ (0.00390625,-125) [-125|125.99609375] "%" Vector__XXX
 SG_ ErDD2PrmrSdNgtvTChsssGrndVltg : 32|16@1+ (0.00390625,-125) [0|125.99609375] "%" Vector__XXX
 SG_ ErDD2SndrSdNgtvTChsssGrndVltg : 48|16@1+ (0.00390625,-125) [0|125.99609375] "%" Vector__XXX

BO_ 2365165310 ERDCDC2VC: 8 Vector__XXX
 SG_ ErDcDc2PrimarySideVoltage : 0|16@1+ (0.00390625,-125) [0|125.99609375] "%" Vector__XXX
 SG_ ErDcDc2SecondarySideVoltage : 16|16@1+ (0.00390625,-125) [0|125.99609375] "%" Vector__XXX
 SG_ ErDcDc2PrimarySideCurrent : 32|16@1+ (0.00390625,-125) [-125|125.99609375] "%" Vector__XXX
 SG_ ErDcDc2SecondarySideCurrent : 48|16@1+ (0.00390625,-125) [-125|125.99609375] "%" Vector__XXX

BO_ 2365165566 ERDCDC2OS: 8 Vector__XXX
 SG_ ErDcDc2StatusCrc : 0|8@1+ (1,0) [0|250] "count" Vector__XXX
 SG_ ErDcDc2StatusCounter : 8|4@1+ (1,0) [0|15] "" Vector__XXX
 SG_ ErDcDc2OperationalStatus : 12|4@1+ (1,0) [0|15] "" Vector__XXX
 SG_ ErDcDc2HvilStatus : 16|2@1+ (1,0) [0|3] "" Vector__XXX
 SG_ ErDcDc2LoadshedRequest : 18|2@1+ (1,0) [0|3] "" Vector__XXX
 SG_ ErDD2PwrLmtDTPrmrSdCrrntMnmm : 20|2@1+ (1,0) [0|3] "" Vector__XXX
 SG_ ErDD2PwrLmtDTPrmrSdCrrntMxmm : 22|2@1+ (1,0) [0|3] "" Vector__XXX
 SG_ ErDD2PwrLmtDTSndrSdCrrntMnmm : 24|2@1+ (1,0) [0|3] "" Vector__XXX
 SG_ ErDD2PwrLmtDTSndrSdCrrntMxmm : 26|2@1+ (1,0) [0|3] "" Vector__XXX
 SG_ ErDD2PwrLmtDTPrmrSdVltgMnmm : 28|2@1+ (1,0) [0|3] "" Vector__XXX
 SG_ ErDD2PwrLmtDTPrmrSdVltgMxmm : 30|2@1+ (1,0) [0|3] "" Vector__XXX
 SG_ ErDD2PwrLmtDTSndrSdVltgMnmm : 32|2@1+ (1,0) [0|3] "" Vector__XXX
 SG_ ErDD2PwrLmtDTSndrSdVltgMxmm : 34|2@1+ (1,0) [0|3] "" Vector__XXX
 SG_ ErDD2PwrLmtDTCnvrtrTmprtr : 36|2@1+ (1,0) [0|3] "" Vector__XXX
 SG_ ErDD2PwrLmtDTEltrnFltrTmprtr : 38|2@1+ (1,0) [0|3] "" Vector__XXX
 SG_ ErDD2PwrLmtDTPwrEltrnsTmprtr : 40|2@1+ (1,0) [0|3] "" Vector__XXX
 SG_ ErDD2PwrLmtDTUndfndRsn : 42|2@1+ (1,0) [0|3] "" Vector__XXX

BO_ 2365165822 ERDCDC2C: 8 Vector__XXX
 SG_ ErDcDc2CommandCrc : 0|8@1+ (1,0) [0|250] "count" Vector__XXX
 SG_ ErDcDc2CommandCounter : 8|4@1+ (1,0) [0|15] "" Vector__XXX
 SG_ ErDcDc2OperationalCommand : 12|4@1+ (1,0) [0|15] "" Vector__XXX
 SG_ ErDcDc2OperationalSetpoint : 16|16@1+ (0.00390625,-125) [-125|125.99609375] "%" Vector__XXX

BO_ 2365166078 ERDCDC1RF: 8 Vector__XXX
 SG_ ErDcDc1ReferenceCrc : 0|8@1+ (1,0) [0|250] "count" Vector__XXX
 SG_ ErDcDc1ReferenceCounter : 8|4@1+ (1,0) [0|15] "" Vector__XXX
 SG_ ErDcDc1ReferenceCurrent : 16|16@1+ (0.125,0) [0|8031.875] "A" Vector__XXX
 SG_ ErDcDc1ReferenceVoltage : 32|16@1+ (0.125,0) [0|8031.875] "V" Vector__XXX
 SG_ ErDcDc1ReferencePower : 48|16@1+ (0.0625,0) [0|4015.9375] "kW" Vector__XXX

BO_ 2365166334 ERDCDC1PLR: 8 Vector__XXX
 SG_ ErDD1PrmrSdPwrMnmmLmtRqst : 0|16@1+ (0.00390625,-125) [-125|125.99609375] "%" Vector__XXX
 SG_ ErDD1PrmrSdPwrMxmmLmtRqst : 16|16@1+ (0.00390625,-125) [-125|125.99609375] "%" Vector__XXX
 SG_ ErDD1SndrSdPwrMnmmLmtRqst : 32|16@1+ (0.00390625,-125) [-125|125.99609375] "%" Vector__XXX
 SG_ ErDD1SndrSdPwrMxmmLmtRqst : 48|16@1+ (0.00390625,-125) [-125|125.99609375] "%" Vector__XXX

BO_ 2365166590 ERDCDC1CLR: 8 Vector__XXX
 SG_ ErDD1PrmrSdCrrntMnmmLmtRqst : 0|16@1+ (0.00390625,-125) [-125|125.99609375] "%" Vector__XXX
 SG_ ErDD1PrmrSdCrrntMxmmLmtRqst : 16|16@1+ (0.00390625,-125) [-125|125.99609375] "%" Vector__XXX
 SG_ ErDD1SndrSdCrrntMnmmLmtRqst : 32|16@1+ (0.00390625,-125) [-125|125.99609375] "%" Vector__XXX
 SG_ ErDD1SndrSdCrrntMxmmLmtRqst : 48|16@1+ (0.00390625,-125) [-125|125.99609375] "%" Vector__XXX

BO_ 2365166846 ERDCDC1VLR: 8 Vector__XXX
 SG_ ErDD1PrmrSdVltgMnmmLmtRqst : 0|16@1+ (0.00390625,-125) [0|125.99609375] "%" Vector__XXX
 SG_ ErDD1PrmrSdVltgMxmmLmtRqst : 16|16@1+ (0.00390625,-125) [0|125.99609375] "%" Vector__XXX
 SG_ ErDD1SndrSdVltgMnmmLmtRqst : 32|16@1+ (0.00390625,-125) [0|125.99609375] "%" Vector__XXX
 SG_ ErDD1SndrSdVltgMxmmLmtRqst : 48|16@1+ (0.00390625,-125) [0|125.99609375] "%" Vector__XXX

BO_ 2365167102 ERDCDC1T: 8 Vector__XXX
 SG_ ErDcDc1ConverterTemperature : 0|8@1+ (1,-40) [-40|210] "degC" Vector__XXX
 SG_ ErDD1CnvrtrEltrnFltrTmprtr : 8|8@1+ (1,-40) [-40|210] "degC" Vector__XXX
 SG_ ErDD1PwrEltrnsTmprtr : 16|8@1+ (1,-40) [-40|210] "degC" Vector__XXX
 SG_ ErDcDc1CoolantInTemperature : 24|8@1+ (1,-40) [-40|210] "degC" Vector__XXX
 SG_ ErDcDc1CoolantOutTemperature : 32|8@1+ (1,-40) [-40|210] "degC" Vector__XXX

BO_ 2566493950 ERDCDC1PLS: 8 Vector__XXX
 SG_ ErDD1PrmrSdPwrMnmmLmtSttng : 0|16@1+ (0.00390625,-125) [-125|125.99609375] "%" Vector__XXX
 SG_ ErDD1PrmrSdPwrMxmmLmtSttng : 16|16@1+ (0.00390625,-125) [-125|125.99609375] "%" Vector__XXX
 SG_ ErDD1SndrSdPwrMnmmLmtSttng : 32|16@1+ (0.00390625,-125) [-125|125.99609375] "%" Vector__XXX
 SG_ ErDD1SndrSdPwrMxmmLmtSttng : 48|16@1+ (0.00390625,-125) [-125|125.99609375] "%" Vector__XXX

BO_ 2566494206 ERDCDC1CLS: 8 Vector__XXX
 SG_ ErDD1PrmrSdCrrntMnmmLmtSttng : 0|16@1+ (0.00390625,-125) [-125|125.99609375] "%" Vector__XXX
 SG_ ErDD1PrmrSdCrrntMxmmLmtSttng : 16|16@1+ (0.00390625,-125) [-125|125.99609375] "%" Vector__XXX
 SG_ ErDD1SndrSdCrrntMnmmLmtSttng : 32|16@1+ (0.00390625,-125) [-125|125.99609375] "%" Vector__XXX
 SG_ ErDD1SndrSdCrrntMxmmLmtSttng : 48|16@1+ (0.00390625,-125) [-125|125.99609375] "%" Vector__XXX

BO_ 2566494462 ERDCDC1VLS: 8 Vector__XXX
 SG_ ErDD1PrmrSdVltgMnmmLmtSttng : 0|16@1+ (0.00390625,-125) [0|125.99609375] "%" Vector__XXX
 SG_ ErDD1PrmrSdVltgMxmmLmtSttng : 16|16@1+ (0.00390625,-125) [0|125.99609375] "%" Vector__XXX
 SG_ ErDD1SndrSdVltgMnmmLmtSttng : 32|16@1+ (0.00390625,-125) [0|125.99609375] "%" Vector__XXX
 SG_ ErDD1SndrSdVltgMxmmLmtSttng : 48|16@1+ (0.00390625,-125) [0|125.99609375] "%" Vector__XXX

BO_ 2365168126 ERDCDC1LV: 8 Vector__XXX
 SG_ ErDD1CntrllrInptIgntnVltg : 0|16@1+ (0.05,0) [0|3212.75] "V" Vector__XXX
 SG_ ErDD1CntrllrInptUnswthdSlVltg : 16|16@1+ (0.05,0) [0|3212.75] "V" Vector__XXX

BO_ 2365168382 ERDCDC1PCV: 8 Vector__XXX
 SG_ ErDcDc1PrimarySidePower : 0|16@1+ (0.00390625,-125) [-125|125.99609375] "%" Vector__XXX
 SG_ ErDcDc1SecondarySidePower : 16|16@1+ (0.00390625,-125) [-125|125.99609375] "%" Vector__XXX
 SG_ ErDD1PrmrSdNgtvTChsssGrndVltg : 32|16@1+ (0.00390625,-125) [0|125.99609375] "%" Vector__XXX
 SG_ ErDD1SndrSdNgtvTChsssGrndVltg : 48|16@1+ (0.00390625,-125) [0|125.99609375] "%" Vector__XXX

BO_ 2365168638 ERDCDC1VC: 8 Vector__XXX
 SG_ ErDcDc1PrimarySideVoltage : 0|16@1+ (0.00390625,-125) [0|125.99609375] "%" Vector__XXX
 SG_ ErDcDc1SecondarySideVoltage : 16|16@1+ (0.00390625,-125) [0|125.99609375] "%" Vector__XXX
 SG_ ErDcDc1PrimarySideCurrent : 32|16@1+ (0.00390625,-125) [-125|125.99609375] "%" Vector__XXX
 SG_ ErDcDc1SecondarySideCurrent : 48|16@1+ (0.00390625,-125) [-125|125.99609375] "%" Vector__XXX

BO_ 2365168894 ERDCDC1OS: 8 Vector__XXX
 SG_ ErDcDc1StatusCrc : 0|8@1+ (1,0) [0|250] "count" Vector__XXX
 SG_ ErDcDc1StatusCounter : 8|4@1+ (1,0) [0|15] "" Vector__XXX
 SG_ ErDcDc1OperationalStatus : 12|4@1+ (1,0) [0|15] "" Vector__XXX
 SG_ ErDcDc1HvilStatus : 16|2@1+ (1,0) [0|3] "" Vector__XXX
 SG_ ErDcDc1LoadshedRequest : 18|2@1+ (1,0) [0|3] "" Vector__XXX
 SG_ ErDD1PwrLmtDTPrmrSdCrrntMnmm : 20|2@1+ (1,0) [0|3] "" Vector__XXX
 SG_ ErDD1PwrLmtDTPrmrSdCrrntMxmm : 22|2@1+ (1,0) [0|3] "" Vector__XXX
 SG_ ErDD1PwrLmtDTSndrSdCrrntMnmm : 24|2@1+ (1,0) [0|3] "" Vector__XXX
 SG_ ErDD1PwrLmtDTSndrSdCrrntMxmm : 26|2@1+ (1,0) [0|3] "" Vector__XXX
 SG_ ErDD1PwrLmtDTPrmrSdVltgMnmm : 28|2@1+ (1,0) [0|3] "" Vector__XXX
 SG_ ErDD1PwrLmtDTPrmrSdVltgMxmm : 30|2@1+ (1,0) [0|3] "" Vector__XXX
 SG_ ErDD1PwrLmtDTSndrSdVltgMnmm : 32|2@1+ (1,0) [0|3] "" Vector__XXX
 SG_ ErDD1PwrLmtDTSndrSdVltgMxmm : 34|2@1+ (1,0) [0|3] "" Vector__XXX
 SG_ ErDD1PwrLmtDTCnvrtrTmprtr : 36|2@1+ (1,0) [0|3] "" Vector__XXX
 SG_ ErDD1PwrLmtDTEltrnFltrTmprtr : 38|2@1+ (1,0) [0|3] "" Vector__XXX
 SG_ ErDD1PwrLmtDTPwrEltrnsTmprtr : 40|2@1+ (1,0) [0|3] "" Vector__XXX
 SG_ ErDD1PwrLmtDTUndfndRsn : 42|2@1+ (1,0) [0|3] "" Vector__XXX

BO_ 2365169150 ERDCDC1C: 8 Vector__XXX
 SG_ ErDcDc1CommandCrc : 0|8@1+ (1,0) [0|250] "count" Vector__XXX
 SG_ ErDcDc1CommandCounter : 8|4@1+ (1,0) [0|15] "" Vector__XXX
 SG_ ErDcDc1OperationalCommand : 12|4@1+ (1,0) [0|15] "" Vector__XXX
 SG_ ErDcDc1OperationalSetpoint : 16|16@1+ (0.00390625,-125) [-125|125.99609375] "%" Vector__XXX

BO_ 2566495998 CAQSI2: 8 Vector__XXX
 SG_ CabCo2ConcentrationStatus : 0|3@1+ (1,0) [0|7] "" Vector__XXX
 SG_ CabPressureStatus : 3|3@1+ (1,0) [0|7] "" Vector__XXX
 SG_ CabDustConcentrationStatus : 6|3@1+ (1,0) [0|7] "" Vector__XXX

BO_ 2566496254 CAQSI1: 8 Vector__XXX
 SG_ CabCo2Concentration : 0|16@1+ (1,0) [0|64255] "ppm" Vector__XXX
 SG_ CabPressure : 16|16@1+ (0.0078125,-250) [-100|251.9921875] "kPa" Vector__XXX
 SG_ CabDustConcentration : 32|16@1+ (1,-25) [-25|64230] "microg/m3" Vector__XXX
 SG_ CabPressureSensorStatus : 48|2@1+ (1,0) [0|3] "" Vector__XXX
 SG_ CabCo2ConcentrationSensorStatus : 50|2@1+ (1,0) [0|3] "" Vector__XXX
 SG_ CDstCnntrtnSnsrStts : 52|2@1+ (1,0) [0|3] "" Vector__XXX

BO_ 2566496510 WSP6: 8 Vector__XXX
 SG_ AtWSttPpLOFwRtExtddR : 0|16@1+ (0.5,0) [0|32127.5] "l/min" Vector__XXX
 SG_ EsttdWSttPpLOFwRtExtddR : 16|16@1+ (0.5,0) [0|32127.5] "l/min" Vector__XXX
 SG_ AtWSttPpGBxLOFwRtExtddR : 32|16@1+ (0.5,0) [0|32127.5] "l/min" Vector__XXX
 SG_ EsttdWSttPpGBxLOFwRtExtddR : 48|16@1+ (0.5,0) [0|32127.5] "l/min" Vector__XXX

BO_ 2566496766 EFS4: 8 Vector__XXX
 SG_ EngnFlInjtnSstmDsrdOlPmpMtrSpd : 0|16@1+ (0.5,0) [0|32127.5] "rpm" Vector__XXX
 SG_ EngnFlInjtnSstmOlRl1Prssr : 16|16@1+ (0.00390625,0) [0|250.99609375] "MPa" Vector__XXX
 SG_ EngnFlInjtnSstmOlRl2Prssr : 32|16@1+ (0.00390625,0) [0|250.99609375] "MPa" Vector__XXX
 SG_ EFItSstOPpFwCtVvCd : 48|8@1+ (0.4,0) [0|100] "%" Vector__XXX
 SG_ EFItSstOPssLttVvCd : 56|2@1+ (1,0) [0|3] "" Vector__XXX
 SG_ EngnFlInjtnSstmOlPmpMtrEnlCmmnd : 58|2@1+ (1,0) [0|3] "" Vector__XXX

BO_ 2566497022 AF6: 8 Vector__XXX
 SG_ EF2ItMtR1PssExtddR : 0|16@1+ (0.00390625,0) [0|250.99609375] "MPa" Vector__XXX
 SG_ EF2ItMtR2PssExtddR : 16|16@1+ (0.00390625,0) [0|250.99609375] "MPa" Vector__XXX
 SG_ EngnFl2DsrdPmpMtrSpd : 32|16@1+ (0.5,0) [0|32127.5] "rpm" Vector__XXX
 SG_ EngnFl2PmpMtrEnlCmmnd : 48|2@1+ (1,0) [0|3] "" Vector__XXX
 SG_ EngnFl2PmpBpssVlvCmmnd : 50|2@1+ (1,0) [0|3] "" Vector__XXX

BO_ 2566497278 ECDAC: 8 Vector__XXX
 SG_ EngnCtlstDvrtrAttr1Cmmnd : 0|8@1+ (0.4,0) [0|100] "%" Vector__XXX
 SG_ EngnCtlstDvrtrAttr2Cmmnd : 8|8@1+ (0.4,0) [0|100] "%" Vector__XXX

BO_ 2566497534 AMB4: 8 Vector__XXX
 SG_ FuelSpecificHumidity : 0|16@1+ (0.01,0) [0|642.55] "g/kg" Vector__XXX
 SG_ EngineChargeAirSpecificHumidity : 16|16@1+ (0.01,0) [0|642.55] "g/kg" Vector__XXX
 SG_ FuelRelativeHumidity : 32|8@1+ (0.4,0) [0|100] "%" Vector__XXX
 SG_ EngineChargeAirRelativeHumidity : 40|8@1+ (0.4,0) [0|100] "%" Vector__XXX

BO_ 2566497790 EEPCSI2: 8 Vector__XXX
 SG_ Atttt2ExstPttCtSstDstT : 0|32@1+ (1,0) [0|4211081215] "s" Vector__XXX
 SG_ Atttt2ExstPttCtSstDstCt : 32|32@1+ (1,0) [0|4211081215] "count" Vector__XXX

BO_ 2566498046 EEPCSI1: 8 Vector__XXX
 SG_ Atttt1ExstPttCtSstDstT : 0|32@1+ (1,0) [0|4211081215] "s" Vector__XXX
 SG_ Atttt1ExstPttCtSstDstCt : 32|32@1+ (1,0) [0|4211081215] "count" Vector__XXX

BO_ 2566498302 ASI20: 8 Vector__XXX
 SG_ Atttt2TtERtWtNDsExstFdDv : 0|32@1+ (1,0) [0|4211081215] "s" Vector__XXX
 SG_ Atttt2TtEvtCtWtNDsExstFdDv : 32|32@1+ (1,0) [0|4211081215] "count" Vector__XXX

BO_ 2566498558 ASI19: 8 Vector__XXX
 SG_ Aftrtrtmnt2SrIntkHghTmprtrTm : 0|32@1+ (1,0) [0|4211081215] "s" Vector__XXX
 SG_ Aftrtrtmnt2SrIntkHghTmprtrCnt : 32|32@1+ (1,0) [0|4211081215] "count" Vector__XXX

BO_ 2566498814 ASI18: 8 Vector__XXX
 SG_ Aftrtrtmnt2DslExhstFldFrznTm : 0|32@1+ (1,0) [0|4211081215] "s" Vector__XXX
 SG_ Aftrtrtmnt2DslExhstFldFrznCnt : 32|32@1+ (1,0) [0|4211081215] "count" Vector__XXX

BO_ 2566499070 ASI17: 8 Vector__XXX
 SG_ Aftrtrtmnt2SrMlfntnTm : 0|32@1+ (1,0) [0|4211081215] "s" Vector__XXX
 SG_ Aftrtrtmnt2SrMlfntnCnt : 32|32@1+ (1,0) [0|4211081215] "count" Vector__XXX

BO_ 2566499326 ASI16: 8 Vector__XXX
 SG_ Atttt2DsExstFdQtMtT : 0|32@1+ (1,0) [0|4211081215] "s" Vector__XXX
 SG_ Atttt2DsExstFdQtMtCt : 32|32@1+ (1,0) [0|4211081215] "count" Vector__XXX

BO_ 2566499582 ASI15: 8 Vector__XXX
 SG_ Atttt2DsExstFdT1EptT : 0|32@1+ (1,0) [0|4211081215] "s" Vector__XXX
 SG_ Atttt2DsExstFdT1EptCt : 32|32@1+ (1,0) [0|4211081215] "count" Vector__XXX

BO_ 2566499838 ASI14: 8 Vector__XXX
 SG_ AttttTtERtWtNDsExstFdDv : 0|32@1+ (1,0) [0|4211081215] "s" Vector__XXX
 SG_ AttttTtEvtCtWtNDsExstFdDv : 32|32@1+ (1,0) [0|4211081215] "count" Vector__XXX

BO_ 2566500094 ASI13: 8 Vector__XXX
 SG_ AftrtrtmntSrIntkHghTmprtrTm : 0|32@1+ (1,0) [0|4211081215] "s" Vector__XXX
 SG_ AftrtrtmntSrIntkHghTmprtrCnt : 32|32@1+ (1,0) [0|4211081215] "count" Vector__XXX

BO_ 2566500350 ASI12: 8 Vector__XXX
 SG_ Aftrtrtmnt1DslExhstFldFrznTm : 0|32@1+ (1,0) [0|4211081215] "s" Vector__XXX
 SG_ Aftrtrtmnt1DslExhstFldFrznCnt : 32|32@1+ (1,0) [0|4211081215] "count" Vector__XXX

BO_ 2566500606 ASI11: 8 Vector__XXX
 SG_ Aftrtrtmnt1SrMlfntnTm : 0|32@1+ (1,0) [0|4211081215] "s" Vector__XXX
 SG_ Aftrtrtmnt1SrMlfntnCnt : 32|32@1+ (1,0) [0|4211081215] "count" Vector__XXX

BO_ 2566500862 ASI10: 8 Vector__XXX
 SG_ Atttt1DsExstFdQtMtT : 0|32@1+ (1,0) [0|4211081215] "s" Vector__XXX
 SG_ Atttt1DsExstFdQtMtCt : 32|32@1+ (1,0) [0|4211081215] "count" Vector__XXX

BO_ 2566501118 ASI9: 8 Vector__XXX
 SG_ Atttt1DsExstFdT1EptT : 0|32@1+ (1,0) [0|4211081215] "s" Vector__XXX
 SG_ Atttt1DsExstFdT1EptCt : 32|32@1+ (1,0) [0|4211081215] "count" Vector__XXX

BO_ 2499392766 GSF2: 8 Vector__XXX
 SG_ SmltdMnsFrqnOffstExtnddRng : 0|16@1+ (0.01,-321.28) [-321.28|321.27] "Hz" Vector__XXX

BO_ 2566501886 AS2: 8 Vector__XXX
 SG_ AltrntrStpntVltgFdk : 0|16@1+ (0.001,0) [0|64.255] "V" Vector__XXX
 SG_ AlternatorOutputVoltage : 16|16@1+ (0.001,0) [0|64.255] "V" Vector__XXX
 SG_ AltrntrVltgRgltrTmprtr : 32|8@1+ (1,-40) [-40|210] "degC" Vector__XXX
 SG_ AlternatorExcitationCurrent : 40|8@1+ (0.25,0) [0|62.5] "A" Vector__XXX
 SG_ AlternatorExcitationDutyCycle : 48|8@1+ (0.4,0) [0|100] "%" Vector__XXX

BO_ 2499417598 GSF: 8 Vector__XXX
 SG_ RtvPwrRmtInptCmpnstnFtr : 32|16@1+ (0.01,-321.27) [-321.27|321.28] "%" Vector__XXX
 SG_ RlPwrRmtInptCmpnstnFtr : 48|16@1+ (0.01,-321.27) [-321.27|321.28] "%" Vector__XXX

BO_ 2163828734 AF7: 7 Vector__XXX
 SG_ EngineFuel2DeliveryPressure : 0|8@1+ (4,0) [0|1000] "kPa" Vector__XXX
 SG_ EngnFl2FltrDffrntlPrssr : 8|8@1+ (2,0) [0|500] "kPa" Vector__XXX
 SG_ EngnFl2DlvrAsltPrssr : 16|8@1+ (4,0) [0|1000] "kPa" Vector__XXX
 SG_ EngnFltrdFl2DlvrPrssr : 24|8@1+ (4,0) [0|1000] "kPa" Vector__XXX
 SG_ EngnFltrdFl2DlvrAsltPrssr : 32|8@1+ (4,0) [0|1000] "kPa" Vector__XXX
 SG_ EngnFl2RltvDltrt1 : 40|8@1+ (0.25,0) [0|62.5] "" Vector__XXX
 SG_ EngnFl2RltvDltrt2 : 48|8@1+ (0.25,0) [0|62.5] "" Vector__XXX

BO_ 2566482174 ECDAI: 8 Vector__XXX
 SG_ EngnCtlstDvrtrAttr1Pstn : 0|8@1+ (0.4,0) [0|100] "%" Vector__XXX
 SG_ EngnCtlstDvrtrAttr2Pstn : 8|8@1+ (0.4,0) [0|100] "%" Vector__XXX

BO_ 2566482430 ELDHOS: 8 Vector__XXX
 SG_ EldHsPrplsnSstmPwrStts : 0|2@1+ (1,0) [0|3] "" Vector__XXX
 SG_ EldHosVehicleMotionStatus : 2|2@1+ (1,0) [0|3] "" Vector__XXX
 SG_ EldHosVehicleDistance : 8|24@1+ (1.6,0) [0|26319256] "km" Vector__XXX
 SG_ EldHosEngineHours : 32|24@1+ (0.1,0) [0|1644953.5] "h" Vector__XXX

BA_DEF_ BO_  "VFrameFormat" ENUM  "StandardCAN","ExtendedCAN","reserved","J1939PG";
BA_DEF_DEF_  "VFrameFormat" "J1939PG";
